[part 7 of 12: package /E40_Platform_System_SystemPackage/Components]
AUTOSAR XML (schema 4-2-1)
package /E40_Platform_System_SystemPackage/Components  (continued)
  10 x constant specification:
    View_IlluminationIlluminationDataDataValue0: value-spec={short-label=View_IlluminationIlluminationDataDataValue0, fields=[View_IlluminationIlluminationDataDataValue_0:0, View_IlluminationIlluminationDataDataValue_1:0, View_IlluminationIlluminationDataDataValue_2:0, View_IlluminationIlluminationDataDataValue_3:0]}
    View_IlluminationIllumStatusValue0: value-spec=View_IlluminationIllumStatusValue0:0
    View_IlluminationIgnitionSubstateValue0: value-spec=View_IlluminationIgnitionSubstateValue0:0
    View_IlluminationWSSCurrentVehicleStateValue0: value-spec=View_IlluminationWSSCurrentVehicleStateValue0:0
    View_IlluminationEcoRunSystem_FlagValue0: value-spec=View_IlluminationEcoRunSystem_FlagValue0:0
    View_IlluminationIllumCtrl_Op_DataValue0: value-spec={short-label=View_IlluminationIllumCtrl_Op_DataValue0, fields=[View_IlluminationIllumCtrl_Op_DataValue_0:0, View_IlluminationIllumCtrl_Op_DataValue_1:0, View_IlluminationIllumCtrl_Op_DataValue_2:0, View_IlluminationIllumCtrl_Op_DataValue_3:0, View_IlluminationIllumCtrl_Op_DataValue_4:0, View_IlluminationIllumCtrl_Op_DataValue_5:0, View_IlluminationIllumCtrl_Op_DataValue_6:0, View_IlluminationIllumCtrl_Op_DataValue_7:0]}
    View_IlluminationRheostatDayStepValue0: value-spec=View_IlluminationRheostatDayStepValue0:0
    View_IlluminationRheostatNightStepValue0: value-spec=View_IlluminationRheostatNightStepValue0:0
    View_IlluminationRheoUpdateValValue0: value-spec=View_IlluminationRheoUpdateValValue0:0
    View_IlluminationTFTDisplayOnValue0: value-spec=View_IlluminationTFTDisplayOnValue0:0
  swc implementation IMPL_View_Illumination: programming-language=C, behavior=IB_View_Illumination
    code-descriptors:
      code CodeDescriptor
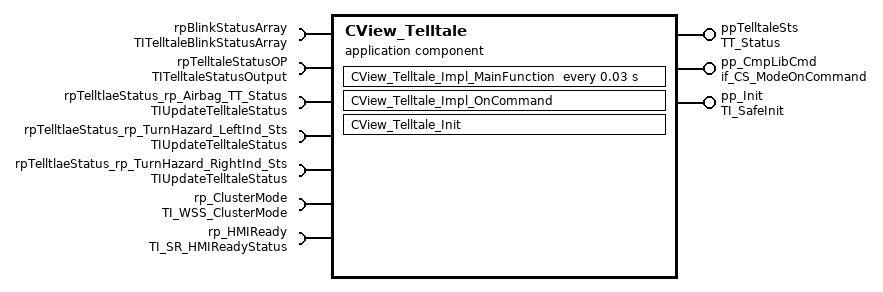
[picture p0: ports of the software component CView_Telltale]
  application sw component type CView_Telltale
    provide port ppTelltaleSts: nonqueued-sender-com-spec{data-element=TT_StatusData, init-value=constant-reference=CView_TelltaleTT_StatusDataValue0}, provided-interface=TT_Status
    provide port pp_CmpLibCmd: server-com-spec{operation=Impl_OnCommand, queue-length=1}, provided-interface=if_CS_ModeOnCommand
    provide port pp_Init: server-com-spec{operation=TI_SafeInit/Init, queue-length=1}, provided-interface=TI_SafeInit
    7 x require port:
      rpBlinkStatusArray: required-interface=TITelltaleBlinkStatusArray
        required-com-specs:
          data-element=TTBlinkStatusArray, init-value=constant-reference=CView_TelltaleTTBlinkStatusArrayValue0
          data-element=TTdummyDataForTypes, init-value=constant-reference=CView_TelltaleTTdummyDataForTypesValue0
      rpTelltaleStatusOP: nonqueued-receiver-com-spec{data-element=TelltaleOpArray, init-value=constant-reference=CView_TelltaleTelltaleOpArrayValue0}, required-interface=TITelltaleStatusOutput
      rpTelltlaeStatus_rp_Airbag_TT_Status: nonqueued-receiver-com-spec{data-element=CurrentTelltaleStatus, init-value=constant-reference=CView_TelltaleCurrentTelltaleStatusValue0}, required-interface=TIUpdateTelltaleStatus
      rpTelltlaeStatus_rp_TurnHazard_LeftInd_Sts: nonqueued-receiver-com-spec{data-element=CurrentTelltaleStatus, init-value=constant-reference=CView_TelltaleCurrentTelltaleStatusValue0}, required-interface=TIUpdateTelltaleStatus
      rpTelltlaeStatus_rp_TurnHazard_RightInd_Sts: nonqueued-receiver-com-spec{data-element=CurrentTelltaleStatus, init-value=constant-reference=CView_TelltaleCurrentTelltaleStatusValue0}, required-interface=TIUpdateTelltaleStatus
      rp_ClusterMode: nonqueued-receiver-com-spec{data-element=WSSCurrentClusterMode, init-value=constant-reference=CView_TelltaleWSSCurrentClusterModeValue0}, required-interface=TI_WSS_ClusterMode
      rp_HMIReady: nonqueued-receiver-com-spec{data-element=HMI_ReadyStatus, init-value=constant-reference=CView_TelltaleHMI_ReadyStatusValue0}, required-interface=TI_SR_HMIReadyStatus
    behavior IB_CView_Telltale
      timing event TECView_Telltale_Impl_MainFunction: start-on-event=CView_Telltale_Impl_MainFunction, period=0.03
      operation invoked event OIE_pp_CmpLibCmd_CView_Telltale_Impl_OnCommandTrigByImpl_OnCommand: start-on-event=CView_Telltale_Impl_OnCommand, operation=pp_CmpLibCmd.Impl_OnCommand
      operation invoked event OIE_pp_Init_CView_Telltale_InitTrigByInit: start-on-event=CView_Telltale_Init, operation=pp_Init.Init
      port-api-options:
        enable-take-address=false, indirect-api=false, port=ppTelltaleSts
        enable-take-address=false, indirect-api=false, port=CView_Telltale/pp_CmpLibCmd
        enable-take-address=false, indirect-api=false, port=CView_Telltale/pp_Init
        enable-take-address=false, indirect-api=false, port=rpBlinkStatusArray
        enable-take-address=false, indirect-api=false, port=CView_Telltale/rpTelltaleStatusOP
        enable-take-address=false, indirect-api=false, port=CView_Telltale/rpTelltlaeStatus_rp_Airbag_TT_Status
        enable-take-address=false, indirect-api=false, port=CView_Telltale/rpTelltlaeStatus_rp_TurnHazard_LeftInd_Sts
        enable-take-address=false, indirect-api=false, port=CView_Telltale/rpTelltlaeStatus_rp_TurnHazard_RightInd_Sts
        enable-take-address=false, indirect-api=false, port=CView_Telltale/rp_ClusterMode
        enable-take-address=false, indirect-api=false, port=rp_HMIReady
      runnable CView_Telltale_Impl_MainFunction: can-be-invoked-concurrently=true
        data-receive-point-by-arguments:
          8 x access:
            DRA_rpBlinkStatusArray_TTBlinkStatusArray: accessed-variable=rpBlinkStatusArray.TTBlinkStatusArray
            DRA_rpBlinkStatusArray_TTdummyDataForTypes: accessed-variable=rpBlinkStatusArray.TTdummyDataForTypes
            DRA_rpTelltaleStatusOP_TelltaleOpArray: accessed-variable=rpTelltaleStatusOP.TelltaleOpArray
            DRA_rpTelltlaeStatus_rp_Airbag_TT_Status_CurrentTelltaleStatus: accessed-variable=rpTelltlaeStatus_rp_Airbag_TT_Status.CurrentTelltaleStatus
            DRA_rpTelltlaeStatus_rp_TurnHazard_LeftInd_Sts_CurrentTelltaleStatus: accessed-variable=rpTelltlaeStatus_rp_TurnHazard_LeftInd_Sts.CurrentTelltaleStatus
            DRA_rpTelltlaeStatus_rp_TurnHazard_RightInd_Sts_CurrentTelltaleStatus: accessed-variable=rpTelltlaeStatus_rp_TurnHazard_RightInd_Sts.CurrentTelltaleStatus
            DRA_rp_ClusterMode_WSSCurrentClusterMode: accessed-variable=rp_ClusterMode.WSSCurrentClusterMode
            DRA_rp_HMIReady_HMI_ReadyStatus: accessed-variable=rp_HMIReady.HMI_ReadyStatus
        data-send-points:
          access DWA_ppTelltaleSts_TT_StatusData: accessed-variable=ppTelltaleSts.TT_StatusData
      runnable CView_Telltale_Impl_OnCommand: can-be-invoked-concurrently=true
      runnable CView_Telltale_Init: can-be-invoked-concurrently=true
  7 x constant specification:
    CView_TelltaleTT_StatusDataValue0: value-spec={short-label=CView_TelltaleTT_StatusDataValue0, fields=CView_TelltaleTT_StatusDataValue_0:[CView_Telltalemask0Value:0, CView_Telltalemask1Value:0, CView_Telltalemask2Value:0, CView_Telltalemask3Value:0, CView_Telltalemask4Value:0, CView_Telltalemask5Value:0, CView_Telltalemask6Value:0, CView_Telltalemask7Value:0, CView_Telltalemask8Value:0, CView_Telltalemask9Value:0, CView_Telltalemask10Value:0, CView_Telltalemask11Value:0, CView_Telltalemask12Value:0, CView_Telltalemask13Value:0, CView_Telltalemask14Value:0]}
    CView_TelltaleTTBlinkStatusArrayValue0: value-spec=CView_TelltaleTTBlinkStatusArrayValue0:[CView_TelltaleTTBlinkStatusArray0Value:0, CView_TelltaleTTBlinkStatusArray1Value:0, CView_TelltaleTTBlinkStatusArray2Value:0, CView_TelltaleTTBlinkStatusArray3Value:0, CView_TelltaleTTBlinkStatusArray4Value:0, CView_TelltaleTTBlinkStatusArray5Value:0, CView_TelltaleTTBlinkStatusArray6Value:0, CView_TelltaleTTBlinkStatusArray7Value:0, CView_TelltaleTTBlinkStatusArray8Value:0, CView_TelltaleTTBlinkStatusArray9Value:0, CView_TelltaleTTBlinkStatusArray10Value:0, CView_TelltaleTTBlinkStatusArray11Value:0, CView_TelltaleTTBlinkStatusArray12Value:0, CView_TelltaleTTBlinkStatusArray13Value:0, CView_TelltaleTTBlinkStatusArray14Value:0, CView_TelltaleTTBlinkStatusArray15Value:0]
    CView_TelltaleTTdummyDataForTypesValue0: value-spec=CView_TelltaleTTdummyDataForTypesValue0:0
    CView_TelltaleTelltaleOpArrayValue0: value-spec=CView_TelltaleTelltaleOpArrayValue0:[CView_TelltaleTelltaleOpArray0Value:0, CView_TelltaleTelltaleOpArray1Value:0, CView_TelltaleTelltaleOpArray2Value:0, CView_TelltaleTelltaleOpArray3Value:0, CView_TelltaleTelltaleOpArray4Value:0, CView_TelltaleTelltaleOpArray5Value:0, CView_TelltaleTelltaleOpArray6Value:0, CView_TelltaleTelltaleOpArray7Value:0, CView_TelltaleTelltaleOpArray8Value:0, CView_TelltaleTelltaleOpArray9Value:0, CView_TelltaleTelltaleOpArray10Value:0, CView_TelltaleTelltaleOpArray11Value:0, CView_TelltaleTelltaleOpArray12Value:0, CView_TelltaleTelltaleOpArray13Value:0, CView_TelltaleTelltaleOpArray14Value:0, CView_TelltaleTelltaleOpArray15Value:0, CView_TelltaleTelltaleOpArray16Value:0, CView_TelltaleTelltaleOpArray17Value:0, CView_TelltaleTelltaleOpArray18Value:0, CView_TelltaleTelltaleOpArray19Value:0, CView_TelltaleTelltaleOpArray20Value:0, CView_TelltaleTelltaleOpArray21Value:0, CView_TelltaleTelltaleOpArray22Value:0, CView_TelltaleTelltaleOpArray23Value:0, CView_TelltaleTelltaleOpArray24Value:0, CView_TelltaleTelltaleOpArray25Value:0, CView_TelltaleTelltaleOpArray26Value:0, CView_TelltaleTelltaleOpArray27Value:0, CView_TelltaleTelltaleOpArray28Value:0, CView_TelltaleTelltaleOpArray29Value:0, CView_TelltaleTelltaleOpArray30Value:0, CView_TelltaleTelltaleOpArray31Value:0, CView_TelltaleTelltaleOpArray32Value:0, CView_TelltaleTelltaleOpArray33Value:0, CView_TelltaleTelltaleOpArray34Value:0, CView_TelltaleTelltaleOpArray35Value:0, CView_TelltaleTelltaleOpArray36Value:0, CView_TelltaleTelltaleOpArray37Value:0, CView_TelltaleTelltaleOpArray38Value:0, CView_TelltaleTelltaleOpArray39Value:0, CView_TelltaleTelltaleOpArray40Value:0, CView_TelltaleTelltaleOpArray41Value:0, CView_TelltaleTelltaleOpArray42Value:0, CView_TelltaleTelltaleOpArray43Value:0, CView_TelltaleTelltaleOpArray44Value:0, CView_TelltaleTelltaleOpArray45Value:0, CView_TelltaleTelltaleOpArray46Value:0, CView_TelltaleTelltaleOpArray47Value:0, CView_TelltaleTelltaleOpArray48Value:0, CView_TelltaleTelltaleOpArray49Value:0, CView_TelltaleTelltaleOpArray50Value:0, CView_TelltaleTelltaleOpArray51Value:0, CView_TelltaleTelltaleOpArray52Value:0, CView_TelltaleTelltaleOpArray53Value:0, CView_TelltaleTelltaleOpArray54Value:0, CView_TelltaleTelltaleOpArray55Value:0, CView_TelltaleTelltaleOpArray56Value:0, CView_TelltaleTelltaleOpArray57Value:0, CView_TelltaleTelltaleOpArray58Value:0, CView_TelltaleTelltaleOpArray59Value:0, CView_TelltaleTelltaleOpArray60Value:0, CView_TelltaleTelltaleOpArray61Value:0, CView_TelltaleTelltaleOpArray62Value:0, CView_TelltaleTelltaleOpArray63Value:0, CView_TelltaleTelltaleOpArray64Value:0, CView_TelltaleTelltaleOpArray65Value:0, CView_TelltaleTelltaleOpArray66Value:0, CView_TelltaleTelltaleOpArray67Value:0, CView_TelltaleTelltaleOpArray68Value:0, CView_TelltaleTelltaleOpArray69Value:0, CView_TelltaleTelltaleOpArray70Value:0, CView_TelltaleTelltaleOpArray71Value:0, CView_TelltaleTelltaleOpArray72Value:0, CView_TelltaleTelltaleOpArray73Value:0, CView_TelltaleTelltaleOpArray74Value:0, CView_TelltaleTelltaleOpArray75Value:0, CView_TelltaleTelltaleOpArray76Value:0, CView_TelltaleTelltaleOpArray77Value:0, CView_TelltaleTelltaleOpArray78Value:0, CView_TelltaleTelltaleOpArray79Value:0, CView_TelltaleTelltaleOpArray80Value:0, CView_TelltaleTelltaleOpArray81Value:0, CView_TelltaleTelltaleOpArray82Value:0, CView_TelltaleTelltaleOpArray83Value:0, CView_TelltaleTelltaleOpArray84Value:0, CView_TelltaleTelltaleOpArray85Value:0, CView_TelltaleTelltaleOpArray86Value:0, CView_TelltaleTelltaleOpArray87Value:0, CView_TelltaleTelltaleOpArray88Value:0, CView_TelltaleTelltaleOpArray89Value:0, CView_TelltaleTelltaleOpArray90Value:0, CView_TelltaleTelltaleOpArray91Value:0]
    CView_TelltaleCurrentTelltaleStatusValue0: value-spec=CView_TelltaleCurrentTelltaleStatusValue0:0
    CView_TelltaleWSSCurrentClusterModeValue0: value-spec=CView_TelltaleWSSCurrentClusterModeValue0:0
    CView_TelltaleHMI_ReadyStatusValue0: value-spec=CView_TelltaleHMI_ReadyStatusValue0:0
  swc implementation IMPL_CView_Telltale: programming-language=C, behavior=IB_CView_Telltale
    code-descriptors:
      code CodeDescriptor
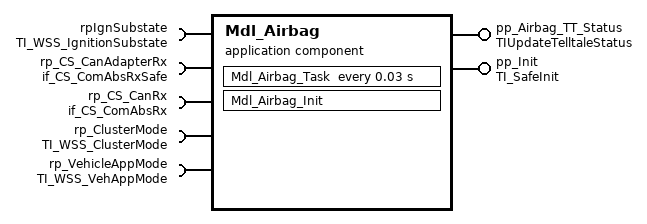
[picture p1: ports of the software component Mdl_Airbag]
  application sw component type Mdl_Airbag
    provide port pp_Airbag_TT_Status: nonqueued-sender-com-spec{data-element=CurrentTelltaleStatus, init-value=constant-reference=Mdl_AirbagCurrentTelltaleStatusValue0}, provided-interface=TIUpdateTelltaleStatus
    provide port pp_Init: server-com-spec{operation=TI_SafeInit/Init, queue-length=1}, provided-interface=TI_SafeInit
    5 x require port:
      rpIgnSubstate: nonqueued-receiver-com-spec{data-element=IgnitionSubstate, init-value=constant-reference=Mdl_AirbagIgnitionSubstateValue0}, required-interface=TI_WSS_IgnitionSubstate
      rp_CS_CanAdapterRx: required-interface=if_CS_ComAbsRxSafe
      rp_CS_CanRx: required-interface=if_CS_ComAbsRx
      rp_ClusterMode: nonqueued-receiver-com-spec{data-element=WSSCurrentClusterMode, init-value=constant-reference=Mdl_AirbagWSSCurrentClusterModeValue0}, required-interface=TI_WSS_ClusterMode
      rp_VehicleAppMode: nonqueued-receiver-com-spec{data-element=WSSCurrentVehicleState, init-value=constant-reference=Mdl_AirbagWSSCurrentVehicleStateValue0}, required-interface=TI_WSS_VehAppMode
    behavior IB_Mdl_Airbag
      operation invoked event OIE_pp_Init_Mdl_Airbag_InitTrigByInit: start-on-event=Mdl_Airbag_Init, operation=pp_Init.Init
      timing event TEMdl_Airbag_Task: start-on-event=Mdl_Airbag_Task, period=0.03
      port-api-options:
        enable-take-address=false, indirect-api=false, port=pp_Airbag_TT_Status
        enable-take-address=false, indirect-api=false, port=Mdl_Airbag/pp_Init
        enable-take-address=false, indirect-api=false, port=Mdl_Airbag/rpIgnSubstate
        enable-take-address=false, indirect-api=false, port=rp_CS_CanAdapterRx
        enable-take-address=false, indirect-api=false, port=Mdl_Airbag/rp_CS_CanRx
        enable-take-address=false, indirect-api=false, port=Mdl_Airbag/rp_ClusterMode
        enable-take-address=false, indirect-api=false, port=rp_VehicleAppMode
      runnable Mdl_Airbag_Init: can-be-invoked-concurrently=true
      runnable Mdl_Airbag_Task: can-be-invoked-concurrently=true
        data-receive-point-by-arguments:
          access DRA_rpIgnSubstate_IgnitionSubstate: accessed-variable=rpIgnSubstate.IgnitionSubstate
          access DRA_rp_ClusterMode_WSSCurrentClusterMode: accessed-variable=rp_ClusterMode.WSSCurrentClusterMode
          access DRA_rp_VehicleAppMode_WSSCurrentVehicleState: accessed-variable=rp_VehicleAppMode.WSSCurrentVehicleState
        data-send-points:
          access DWA_pp_Airbag_TT_Status_CurrentTelltaleStatus: accessed-variable=pp_Airbag_TT_Status.CurrentTelltaleStatus
        18 x sync call, all with timeout=0.0:
          OA_rp_CS_CanAdapterRx_RxCan_GetSignalValueU8Arr: operation=rp_CS_CanAdapterRx.RxCan_GetSignalValueU8Arr
          OA_rp_CS_CanAdapterRx_RxCan_SetSignalInitValue: operation=rp_CS_CanAdapterRx.RxCan_SetSignalInitValue
          OA_rp_CS_CanAdapterRx_RxCan_SetSignalInitValueU8Arr: operation=rp_CS_CanAdapterRx.RxCan_SetSignalInitValueU8Arr
          OA_rp_CS_CanAdapterRx_RxCan_SignalInvalidProcessingControl: operation=rp_CS_CanAdapterRx.RxCan_SignalInvalidProcessingControl
          OA_rp_CS_CanAdapterRx_RxCan_SignalMissingProcessingControl: operation=rp_CS_CanAdapterRx.RxCan_SignalMissingProcessingControl
          OA_rp_CS_CanAdapterRx_RxCan_SignalNRProcessingControl: operation=rp_CS_CanAdapterRx.RxCan_SignalNRProcessingControl
          OA_rp_CS_CanAdapterRx_RxCan_SignalGetJustRcvdStatus: operation=rp_CS_CanAdapterRx.RxCan_SignalGetJustRcvdStatus
          OA_rp_CS_CanAdapterRx_RxCan_SignalClearJustRcvdStatus: operation=rp_CS_CanAdapterRx.RxCan_SignalClearJustRcvdStatus
          OA_rp_CS_CanAdapterRx_RxCan_GetSignalValue: operation=rp_CS_CanAdapterRx.RxCan_GetSignalValue
          OA_rp_CS_CanRx_RxCan_GetSignalValueU8Arr: operation=rp_CS_CanRx.RxCan_GetSignalValueU8Arr
          OA_rp_CS_CanRx_RxCan_SetSignalInitValue: operation=rp_CS_CanRx.RxCan_SetSignalInitValue
          OA_rp_CS_CanRx_RxCan_SetSignalInitValueU8Arr: operation=rp_CS_CanRx.RxCan_SetSignalInitValueU8Arr
          OA_rp_CS_CanRx_RxCan_SignalInvalidProcessingControl: operation=rp_CS_CanRx.RxCan_SignalInvalidProcessingControl
          OA_rp_CS_CanRx_RxCan_SignalMissingProcessingControl: operation=rp_CS_CanRx.RxCan_SignalMissingProcessingControl
          OA_rp_CS_CanRx_RxCan_SignalNRProcessingControl: operation=rp_CS_CanRx.RxCan_SignalNRProcessingControl
          OA_rp_CS_CanRx_RxCan_SignalGetJustRcvdStatus: operation=rp_CS_CanRx.RxCan_SignalGetJustRcvdStatus
          OA_rp_CS_CanRx_RxCan_SignalClearJustRcvdStatus: operation=rp_CS_CanRx.RxCan_SignalClearJustRcvdStatus
          OA_rp_CS_CanRx_RxCan_GetSignalValue: operation=rp_CS_CanRx.RxCan_GetSignalValue
  4 x constant specification:
    Mdl_AirbagCurrentTelltaleStatusValue0: value-spec=Mdl_AirbagCurrentTelltaleStatusValue0:0
    Mdl_AirbagIgnitionSubstateValue0: value-spec=Mdl_AirbagIgnitionSubstateValue0:0
    Mdl_AirbagWSSCurrentClusterModeValue0: value-spec=Mdl_AirbagWSSCurrentClusterModeValue0:0
    Mdl_AirbagWSSCurrentVehicleStateValue0: value-spec=Mdl_AirbagWSSCurrentVehicleStateValue0:0
  swc implementation IMPL_Mdl_Airbag: programming-language=C, behavior=IB_Mdl_Airbag
    code-descriptors:
      code CodeDescriptor
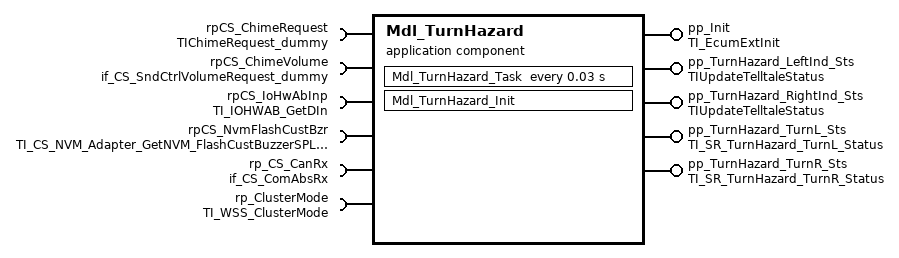
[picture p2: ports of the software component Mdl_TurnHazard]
  application sw component type Mdl_TurnHazard
    5 x provide port:
      pp_Init: server-com-spec{operation=TI_EcumExtInit/Init, queue-length=1}, provided-interface=TI_EcumExtInit
      pp_TurnHazard_LeftInd_Sts: nonqueued-sender-com-spec{data-element=CurrentTelltaleStatus, init-value=constant-reference=Mdl_TurnHazardCurrentTelltaleStatusValue0}, provided-interface=TIUpdateTelltaleStatus
      pp_TurnHazard_RightInd_Sts: nonqueued-sender-com-spec{data-element=CurrentTelltaleStatus, init-value=constant-reference=Mdl_TurnHazardCurrentTelltaleStatusValue0}, provided-interface=TIUpdateTelltaleStatus
      pp_TurnHazard_TurnL_Sts: nonqueued-sender-com-spec{data-element=LeftIndicatorSts, init-value=constant-reference=Mdl_TurnHazardLeftIndicatorStsValue0}, provided-interface=TI_SR_TurnHazard_TurnL_Status
      pp_TurnHazard_TurnR_Sts: nonqueued-sender-com-spec{data-element=RightIndicatorSts, init-value=constant-reference=Mdl_TurnHazardRightIndicatorStsValue0}, provided-interface=TI_SR_TurnHazard_TurnR_Status
    6 x require port:
      rpCS_ChimeRequest: nonqueued-receiver-com-spec{data-element=Chime_Request, init-value=constant-reference=Mdl_TurnHazardChime_RequestValue0}, required-interface=TIChimeRequest_dummy
      rpCS_ChimeVolume: nonqueued-receiver-com-spec{data-element=UpdateChimeVolume, init-value=constant-reference=Mdl_TurnHazardUpdateChimeVolumeValue0}, required-interface=if_CS_SndCtrlVolumeRequest_dummy
      rpCS_IoHwAbInp: required-interface=TI_IOHWAB_GetDIn
      rpCS_NvmFlashCustBzr: nonqueued-receiver-com-spec{data-element=Nvmdata, init-value=constant-reference=Mdl_TurnHazardNvmdataValue0}, required-interface=TI_CS_NVM_Adapter_GetNVM_FlashCustBuzzerSPL_Dummy
      rp_CS_CanRx: required-interface=if_CS_ComAbsRx
      rp_ClusterMode: nonqueued-receiver-com-spec{data-element=WSSCurrentClusterMode, init-value=constant-reference=Mdl_TurnHazardWSSCurrentClusterModeValue0}, required-interface=TI_WSS_ClusterMode
    behavior IB_Mdl_TurnHazard
      operation invoked event OIE_pp_Init_Mdl_TurnHazard_InitTrigByInit: start-on-event=Mdl_TurnHazard_Init, operation=pp_Init.Init
      timing event TEMdl_TurnHazard_Task: start-on-event=Mdl_TurnHazard_Task, period=0.03
      port-api-options:
        enable-take-address=false, indirect-api=false, port=Mdl_TurnHazard/pp_Init
        enable-take-address=false, indirect-api=false, port=pp_TurnHazard_LeftInd_Sts
        enable-take-address=false, indirect-api=false, port=pp_TurnHazard_RightInd_Sts
        enable-take-address=false, indirect-api=false, port=pp_TurnHazard_TurnL_Sts
        enable-take-address=false, indirect-api=false, port=pp_TurnHazard_TurnR_Sts
        enable-take-address=false, indirect-api=false, port=Mdl_TurnHazard/rpCS_ChimeRequest
        enable-take-address=false, indirect-api=false, port=rpCS_ChimeVolume
        enable-take-address=false, indirect-api=false, port=rpCS_IoHwAbInp
        enable-take-address=false, indirect-api=false, port=rpCS_NvmFlashCustBzr
        enable-take-address=false, indirect-api=false, port=Mdl_TurnHazard/rp_CS_CanRx
        enable-take-address=false, indirect-api=false, port=Mdl_TurnHazard/rp_ClusterMode
      runnable Mdl_TurnHazard_Init: can-be-invoked-concurrently=true
      runnable Mdl_TurnHazard_Task: can-be-invoked-concurrently=true
        data-receive-point-by-arguments:
          4 x access:
            DRA_rpCS_ChimeRequest_Chime_Request: accessed-variable=rpCS_ChimeRequest.Chime_Request
            DRA_rpCS_ChimeVolume_UpdateChimeVolume: accessed-variable=rpCS_ChimeVolume.UpdateChimeVolume
            DRA_rpCS_NvmFlashCustBzr_Nvmdata: accessed-variable=rpCS_NvmFlashCustBzr.Nvmdata
            DRA_rp_ClusterMode_WSSCurrentClusterMode: accessed-variable=rp_ClusterMode.WSSCurrentClusterMode
        data-send-points:
          4 x access:
            DWA_pp_TurnHazard_LeftInd_Sts_CurrentTelltaleStatus: accessed-variable=pp_TurnHazard_LeftInd_Sts.CurrentTelltaleStatus
            DWA_pp_TurnHazard_RightInd_Sts_CurrentTelltaleStatus: accessed-variable=pp_TurnHazard_RightInd_Sts.CurrentTelltaleStatus
            DWA_pp_TurnHazard_TurnL_Sts_LeftIndicatorSts: accessed-variable=pp_TurnHazard_TurnL_Sts.LeftIndicatorSts
            DWA_pp_TurnHazard_TurnR_Sts_RightIndicatorSts: accessed-variable=pp_TurnHazard_TurnR_Sts.RightIndicatorSts
        13 x sync call, all with timeout=0.0:
          OA_rpCS_IoHwAbInp_GetAsyncRawInput: operation=rpCS_IoHwAbInp.GetAsyncRawInput
          OA_rpCS_IoHwAbInp_GetProcessedInput: operation=rpCS_IoHwAbInp.GetProcessedInput
          OA_rpCS_IoHwAbInp_GetSyncRawInput: operation=rpCS_IoHwAbInp.GetSyncRawInput
          OA_rpCS_IoHwAbInp_GetInputGroup: operation=rpCS_IoHwAbInp.GetInputGroup
          OA_rp_CS_CanRx_RxCan_GetSignalValueU8Arr: operation=rp_CS_CanRx.RxCan_GetSignalValueU8Arr
          OA_rp_CS_CanRx_RxCan_SetSignalInitValue: operation=rp_CS_CanRx.RxCan_SetSignalInitValue
          OA_rp_CS_CanRx_RxCan_SetSignalInitValueU8Arr: operation=rp_CS_CanRx.RxCan_SetSignalInitValueU8Arr
          OA_rp_CS_CanRx_RxCan_SignalInvalidProcessingControl: operation=rp_CS_CanRx.RxCan_SignalInvalidProcessingControl
          OA_rp_CS_CanRx_RxCan_SignalMissingProcessingControl: operation=rp_CS_CanRx.RxCan_SignalMissingProcessingControl
          OA_rp_CS_CanRx_RxCan_SignalNRProcessingControl: operation=rp_CS_CanRx.RxCan_SignalNRProcessingControl
          OA_rp_CS_CanRx_RxCan_SignalGetJustRcvdStatus: operation=rp_CS_CanRx.RxCan_SignalGetJustRcvdStatus
          OA_rp_CS_CanRx_RxCan_SignalClearJustRcvdStatus: operation=rp_CS_CanRx.RxCan_SignalClearJustRcvdStatus
          OA_rp_CS_CanRx_RxCan_GetSignalValue: operation=rp_CS_CanRx.RxCan_GetSignalValue
  7 x constant specification:
    Mdl_TurnHazardCurrentTelltaleStatusValue0: value-spec=Mdl_TurnHazardCurrentTelltaleStatusValue0:0
    Mdl_TurnHazardLeftIndicatorStsValue0: value-spec=Mdl_TurnHazardLeftIndicatorStsValue0:0
    Mdl_TurnHazardRightIndicatorStsValue0: value-spec=Mdl_TurnHazardRightIndicatorStsValue0:0
    Mdl_TurnHazardChime_RequestValue0: value-spec=Mdl_TurnHazardChime_RequestValue0:0
    Mdl_TurnHazardUpdateChimeVolumeValue0: value-spec=Mdl_TurnHazardUpdateChimeVolumeValue0:0
    Mdl_TurnHazardNvmdataValue0: value-spec=Mdl_TurnHazardNvmdataValue0:0
    Mdl_TurnHazardWSSCurrentClusterModeValue0: value-spec=Mdl_TurnHazardWSSCurrentClusterModeValue0:0
  swc implementation IMPL_Mdl_TurnHazard: programming-language=C, behavior=IB_Mdl_TurnHazard
    code-descriptors:
      code CodeDescriptor
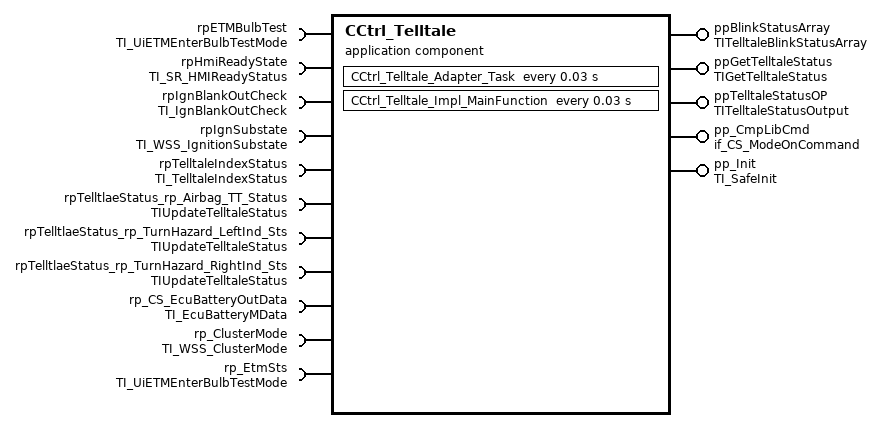
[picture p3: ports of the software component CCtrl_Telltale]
  application sw component type CCtrl_Telltale
    5 x provide port:
      ppBlinkStatusArray: provided-interface=TITelltaleBlinkStatusArray
        provided-com-specs:
          data-element=TTBlinkStatusArray, init-value=constant-reference=CCtrl_TelltaleTTBlinkStatusArrayValue0
          data-element=TTdummyDataForTypes, init-value=constant-reference=CCtrl_TelltaleTTdummyDataForTypesValue0
      ppGetTelltaleStatus: nonqueued-sender-com-spec{data-element=TelltaleFunctionalOpStatus, init-value=constant-reference=CCtrl_TelltaleTelltaleFunctionalOpStatusValue0}, provided-interface=TIGetTelltaleStatus
      ppTelltaleStatusOP: nonqueued-sender-com-spec{data-element=TelltaleOpArray, init-value=constant-reference=CCtrl_TelltaleTelltaleOpArrayValue0}, provided-interface=TITelltaleStatusOutput
      pp_CmpLibCmd: server-com-spec{operation=Impl_OnCommand, queue-length=1}, provided-interface=if_CS_ModeOnCommand
      pp_Init: server-com-spec{operation=TI_SafeInit/Init, queue-length=1}, provided-interface=TI_SafeInit
    11 x require port:
      rpETMBulbTest: nonqueued-receiver-com-spec{data-element=CurrentBulbTestStatus, init-value=constant-reference=CCtrl_TelltaleCurrentBulbTestStatusValue0}, required-interface=TI_UiETMEnterBulbTestMode
      rpHmiReadyState: nonqueued-receiver-com-spec{data-element=HMI_ReadyStatus, init-value=constant-reference=CCtrl_TelltaleHMI_ReadyStatusValue0}, required-interface=TI_SR_HMIReadyStatus
      rpIgnBlankOutCheck: nonqueued-receiver-com-spec{data-element=IgnBlankOutCheck, init-value=constant-reference=CCtrl_TelltaleIgnBlankOutCheckValue0}, required-interface=TI_IgnBlankOutCheck
      rpIgnSubstate: nonqueued-receiver-com-spec{data-element=IgnitionSubstate, init-value=constant-reference=CCtrl_TelltaleIgnitionSubstateValue0}, required-interface=TI_WSS_IgnitionSubstate
      rpTelltaleIndexStatus: required-interface=TI_TelltaleIndexStatus
        required-com-specs:
          data-element=TTIndex, init-value=constant-reference=CCtrl_TelltaleTTIndexValue0
          data-element=TTStatus, init-value=constant-reference=CCtrl_TelltaleTTStatusValue0
      rpTelltlaeStatus_rp_Airbag_TT_Status: nonqueued-receiver-com-spec{data-element=CurrentTelltaleStatus, init-value=constant-reference=CCtrl_TelltaleCurrentTelltaleStatusValue0}, required-interface=TIUpdateTelltaleStatus
      rpTelltlaeStatus_rp_TurnHazard_LeftInd_Sts: nonqueued-receiver-com-spec{data-element=CurrentTelltaleStatus, init-value=constant-reference=CCtrl_TelltaleCurrentTelltaleStatusValue0}, required-interface=TIUpdateTelltaleStatus
      rpTelltlaeStatus_rp_TurnHazard_RightInd_Sts: nonqueued-receiver-com-spec{data-element=CurrentTelltaleStatus, init-value=constant-reference=CCtrl_TelltaleCurrentTelltaleStatusValue0}, required-interface=TIUpdateTelltaleStatus
      rp_CS_EcuBatteryOutData: required-interface=TI_EcuBatteryMData
      rp_ClusterMode: nonqueued-receiver-com-spec{data-element=WSSCurrentClusterMode, init-value=constant-reference=CCtrl_TelltaleWSSCurrentClusterModeValue0}, required-interface=TI_WSS_ClusterMode
      rp_EtmSts: nonqueued-receiver-com-spec{data-element=CurrentBulbTestStatus, init-value=constant-reference=CCtrl_TelltaleCurrentBulbTestStatusValue0}, required-interface=TI_UiETMEnterBulbTestMode
    behavior IB_CCtrl_Telltale
      timing event TECCtrl_Telltale_Adapter_Task: start-on-event=CCtrl_Telltale_Adapter_Task, period=0.03
      timing event TECCtrl_Telltale_Impl_MainFunction: start-on-event=CCtrl_Telltale_Impl_MainFunction, period=0.03
      operation invoked event OIE_pp_CmpLibCmd_CCtrl_Telltale_Impl_OnCommandTrigByImpl_OnCommand: start-on-event=CCtrl_Telltale_Impl_OnCommand, operation=pp_CmpLibCmd.Impl_OnCommand
      operation invoked event OIE_pp_Init_CCtrl_Telltale_InitTrigByInit: start-on-event=CCtrl_Telltale_Init, operation=pp_Init.Init
      port-api-options:
        enable-take-address=false, indirect-api=false, port=ppBlinkStatusArray
        enable-take-address=false, indirect-api=false, port=ppGetTelltaleStatus
        enable-take-address=false, indirect-api=false, port=ppTelltaleStatusOP
        enable-take-address=false, indirect-api=false, port=CCtrl_Telltale/pp_CmpLibCmd
        enable-take-address=false, indirect-api=false, port=CCtrl_Telltale/pp_Init
        enable-take-address=false, indirect-api=false, port=rpETMBulbTest
        enable-take-address=false, indirect-api=false, port=rpHmiReadyState
        enable-take-address=false, indirect-api=false, port=rpIgnBlankOutCheck
        enable-take-address=false, indirect-api=false, port=CCtrl_Telltale/rpIgnSubstate
        enable-take-address=false, indirect-api=false, port=rpTelltaleIndexStatus
        enable-take-address=false, indirect-api=false, port=CCtrl_Telltale/rpTelltlaeStatus_rp_Airbag_TT_Status
        enable-take-address=false, indirect-api=false, port=CCtrl_Telltale/rpTelltlaeStatus_rp_TurnHazard_LeftInd_Sts
        enable-take-address=false, indirect-api=false, port=CCtrl_Telltale/rpTelltlaeStatus_rp_TurnHazard_RightInd_Sts
        enable-take-address=false, indirect-api=false, port=CCtrl_Telltale/rp_CS_EcuBatteryOutData
        enable-take-address=false, indirect-api=false, port=CCtrl_Telltale/rp_ClusterMode
        enable-take-address=false, indirect-api=false, port=rp_EtmSts
      4 x runnable, all with can-be-invoked-concurrently=true:
        CCtrl_Telltale_Adapter_Task
          data-receive-point-by-arguments:
            11 x access:
              DRA_rpETMBulbTest_CurrentBulbTestStatus: accessed-variable=rpETMBulbTest.CurrentBulbTestStatus
              DRA_rpHmiReadyState_HMI_ReadyStatus: accessed-variable=rpHmiReadyState.HMI_ReadyStatus
              DRA_rpIgnBlankOutCheck_IgnBlankOutCheck: accessed-variable=rpIgnBlankOutCheck.IgnBlankOutCheck
              DRA_rpIgnSubstate_IgnitionSubstate: accessed-variable=rpIgnSubstate.IgnitionSubstate
              DRA_rpTelltaleIndexStatus_TTIndex: accessed-variable=rpTelltaleIndexStatus.TTIndex
              DRA_rpTelltaleIndexStatus_TTStatus: accessed-variable=rpTelltaleIndexStatus.TTStatus
              DRA_rpTelltlaeStatus_rp_Airbag_TT_Status_CurrentTelltaleStatus: accessed-variable=rpTelltlaeStatus_rp_Airbag_TT_Status.CurrentTelltaleStatus
              DRA_rpTelltlaeStatus_rp_TurnHazard_LeftInd_Sts_CurrentTelltaleStatus: accessed-variable=rpTelltlaeStatus_rp_TurnHazard_LeftInd_Sts.CurrentTelltaleStatus
              DRA_rpTelltlaeStatus_rp_TurnHazard_RightInd_Sts_CurrentTelltaleStatus: accessed-variable=rpTelltlaeStatus_rp_TurnHazard_RightInd_Sts.CurrentTelltaleStatus
              DRA_rp_ClusterMode_WSSCurrentClusterMode: accessed-variable=rp_ClusterMode.WSSCurrentClusterMode
              DRA_rp_EtmSts_CurrentBulbTestStatus: accessed-variable=rp_EtmSts.CurrentBulbTestStatus
          data-send-points:
            4 x access:
              DWA_ppBlinkStatusArray_TTBlinkStatusArray: accessed-variable=ppBlinkStatusArray.TTBlinkStatusArray
              DWA_ppBlinkStatusArray_TTdummyDataForTypes: accessed-variable=ppBlinkStatusArray.TTdummyDataForTypes
              DWA_ppGetTelltaleStatus_TelltaleFunctionalOpStatus: accessed-variable=ppGetTelltaleStatus.TelltaleFunctionalOpStatus
              DWA_ppTelltaleStatusOP_TelltaleOpArray: accessed-variable=ppTelltaleStatusOP.TelltaleOpArray
          sync call OA_rp_CS_EcuBatteryOutData_EcuBatteryM_GetChannelStatus: operation=rp_CS_EcuBatteryOutData.EcuBatteryM_GetChannelStatus, timeout=0.0
          sync call OA_rp_CS_EcuBatteryOutData_EcuBatteryM_GetDIOStatus: operation=rp_CS_EcuBatteryOutData.EcuBatteryM_GetDIOStatus, timeout=0.0
        CCtrl_Telltale_Impl_MainFunction
          data-receive-point-by-arguments:
            11 x access:
              DRA_rpETMBulbTest_CurrentBulbTestStatus: accessed-variable=rpETMBulbTest.CurrentBulbTestStatus
              DRA_rpHmiReadyState_HMI_ReadyStatus: accessed-variable=rpHmiReadyState.HMI_ReadyStatus
              DRA_rpIgnBlankOutCheck_IgnBlankOutCheck: accessed-variable=rpIgnBlankOutCheck.IgnBlankOutCheck
              DRA_rpIgnSubstate_IgnitionSubstate: accessed-variable=rpIgnSubstate.IgnitionSubstate
              DRA_rpTelltaleIndexStatus_TTIndex: accessed-variable=rpTelltaleIndexStatus.TTIndex
              DRA_rpTelltaleIndexStatus_TTStatus: accessed-variable=rpTelltaleIndexStatus.TTStatus
              DRA_rpTelltlaeStatus_rp_Airbag_TT_Status_CurrentTelltaleStatus: accessed-variable=rpTelltlaeStatus_rp_Airbag_TT_Status.CurrentTelltaleStatus
              DRA_rpTelltlaeStatus_rp_TurnHazard_LeftInd_Sts_CurrentTelltaleStatus: accessed-variable=rpTelltlaeStatus_rp_TurnHazard_LeftInd_Sts.CurrentTelltaleStatus
              DRA_rpTelltlaeStatus_rp_TurnHazard_RightInd_Sts_CurrentTelltaleStatus: accessed-variable=rpTelltlaeStatus_rp_TurnHazard_RightInd_Sts.CurrentTelltaleStatus
              DRA_rp_ClusterMode_WSSCurrentClusterMode: accessed-variable=rp_ClusterMode.WSSCurrentClusterMode
              DRA_rp_EtmSts_CurrentBulbTestStatus: accessed-variable=rp_EtmSts.CurrentBulbTestStatus
          data-send-points:
            4 x access:
              DWA_ppBlinkStatusArray_TTBlinkStatusArray: accessed-variable=ppBlinkStatusArray.TTBlinkStatusArray
              DWA_ppBlinkStatusArray_TTdummyDataForTypes: accessed-variable=ppBlinkStatusArray.TTdummyDataForTypes
              DWA_ppGetTelltaleStatus_TelltaleFunctionalOpStatus: accessed-variable=ppGetTelltaleStatus.TelltaleFunctionalOpStatus
              DWA_ppTelltaleStatusOP_TelltaleOpArray: accessed-variable=ppTelltaleStatusOP.TelltaleOpArray
          sync call OA_rp_CS_EcuBatteryOutData_EcuBatteryM_GetChannelStatus: operation=rp_CS_EcuBatteryOutData.EcuBatteryM_GetChannelStatus, timeout=0.0
          sync call OA_rp_CS_EcuBatteryOutData_EcuBatteryM_GetDIOStatus: operation=rp_CS_EcuBatteryOutData.EcuBatteryM_GetDIOStatus, timeout=0.0
        CCtrl_Telltale_Impl_OnCommand
        CCtrl_Telltale_Init
  12 x constant specification:
    CCtrl_TelltaleTTBlinkStatusArrayValue0: value-spec=CCtrl_TelltaleTTBlinkStatusArrayValue0:[CCtrl_TelltaleTTBlinkStatusArray0Value:0, CCtrl_TelltaleTTBlinkStatusArray1Value:0, CCtrl_TelltaleTTBlinkStatusArray2Value:0, CCtrl_TelltaleTTBlinkStatusArray3Value:0, CCtrl_TelltaleTTBlinkStatusArray4Value:0, CCtrl_TelltaleTTBlinkStatusArray5Value:0, CCtrl_TelltaleTTBlinkStatusArray6Value:0, CCtrl_TelltaleTTBlinkStatusArray7Value:0, CCtrl_TelltaleTTBlinkStatusArray8Value:0, CCtrl_TelltaleTTBlinkStatusArray9Value:0, CCtrl_TelltaleTTBlinkStatusArray10Value:0, CCtrl_TelltaleTTBlinkStatusArray11Value:0, CCtrl_TelltaleTTBlinkStatusArray12Value:0, CCtrl_TelltaleTTBlinkStatusArray13Value:0, CCtrl_TelltaleTTBlinkStatusArray14Value:0, CCtrl_TelltaleTTBlinkStatusArray15Value:0]
    CCtrl_TelltaleTTdummyDataForTypesValue0: value-spec=CCtrl_TelltaleTTdummyDataForTypesValue0:0
    CCtrl_TelltaleTelltaleFunctionalOpStatusValue0: value-spec=CCtrl_TelltaleTelltaleFunctionalOpStatusValue0:[CCtrl_TelltaleTelltaleFunctionalOpStatus0Value:0, CCtrl_TelltaleTelltaleFunctionalOpStatus1Value:0, CCtrl_TelltaleTelltaleFunctionalOpStatus2Value:0, CCtrl_TelltaleTelltaleFunctionalOpStatus3Value:0, CCtrl_TelltaleTelltaleFunctionalOpStatus4Value:0, CCtrl_TelltaleTelltaleFunctionalOpStatus5Value:0, CCtrl_TelltaleTelltaleFunctionalOpStatus6Value:0, CCtrl_TelltaleTelltaleFunctionalOpStatus7Value:0, CCtrl_TelltaleTelltaleFunctionalOpStatus8Value:0, CCtrl_TelltaleTelltaleFunctionalOpStatus9Value:0, CCtrl_TelltaleTelltaleFunctionalOpStatus10Value:0, CCtrl_TelltaleTelltaleFunctionalOpStatus11Value:0, CCtrl_TelltaleTelltaleFunctionalOpStatus12Value:0, CCtrl_TelltaleTelltaleFunctionalOpStatus13Value:0, CCtrl_TelltaleTelltaleFunctionalOpStatus14Value:0, CCtrl_TelltaleTelltaleFunctionalOpStatus15Value:0, CCtrl_TelltaleTelltaleFunctionalOpStatus16Value:0, CCtrl_TelltaleTelltaleFunctionalOpStatus17Value:0, CCtrl_TelltaleTelltaleFunctionalOpStatus18Value:0, CCtrl_TelltaleTelltaleFunctionalOpStatus19Value:0, CCtrl_TelltaleTelltaleFunctionalOpStatus20Value:0, CCtrl_TelltaleTelltaleFunctionalOpStatus21Value:0, CCtrl_TelltaleTelltaleFunctionalOpStatus22Value:0, CCtrl_TelltaleTelltaleFunctionalOpStatus23Value:0, CCtrl_TelltaleTelltaleFunctionalOpStatus24Value:0, CCtrl_TelltaleTelltaleFunctionalOpStatus25Value:0, CCtrl_TelltaleTelltaleFunctionalOpStatus26Value:0, CCtrl_TelltaleTelltaleFunctionalOpStatus27Value:0, CCtrl_TelltaleTelltaleFunctionalOpStatus28Value:0, CCtrl_TelltaleTelltaleFunctionalOpStatus29Value:0, CCtrl_TelltaleTelltaleFunctionalOpStatus30Value:0, CCtrl_TelltaleTelltaleFunctionalOpStatus31Value:0, CCtrl_TelltaleTelltaleFunctionalOpStatus32Value:0, CCtrl_TelltaleTelltaleFunctionalOpStatus33Value:0, CCtrl_TelltaleTelltaleFunctionalOpStatus34Value:0, CCtrl_TelltaleTelltaleFunctionalOpStatus35Value:0, CCtrl_TelltaleTelltaleFunctionalOpStatus36Value:0, CCtrl_TelltaleTelltaleFunctionalOpStatus37Value:0, CCtrl_TelltaleTelltaleFunctionalOpStatus38Value:0, CCtrl_TelltaleTelltaleFunctionalOpStatus39Value:0, CCtrl_TelltaleTelltaleFunctionalOpStatus40Value:0, CCtrl_TelltaleTelltaleFunctionalOpStatus41Value:0, CCtrl_TelltaleTelltaleFunctionalOpStatus42Value:0, CCtrl_TelltaleTelltaleFunctionalOpStatus43Value:0, CCtrl_TelltaleTelltaleFunctionalOpStatus44Value:0, CCtrl_TelltaleTelltaleFunctionalOpStatus45Value:0, CCtrl_TelltaleTelltaleFunctionalOpStatus46Value:0, CCtrl_TelltaleTelltaleFunctionalOpStatus47Value:0, CCtrl_TelltaleTelltaleFunctionalOpStatus48Value:0, CCtrl_TelltaleTelltaleFunctionalOpStatus49Value:0, CCtrl_TelltaleTelltaleFunctionalOpStatus50Value:0, CCtrl_TelltaleTelltaleFunctionalOpStatus51Value:0, CCtrl_TelltaleTelltaleFunctionalOpStatus52Value:0, CCtrl_TelltaleTelltaleFunctionalOpStatus53Value:0, CCtrl_TelltaleTelltaleFunctionalOpStatus54Value:0, CCtrl_TelltaleTelltaleFunctionalOpStatus55Value:0, CCtrl_TelltaleTelltaleFunctionalOpStatus56Value:0, CCtrl_TelltaleTelltaleFunctionalOpStatus57Value:0, CCtrl_TelltaleTelltaleFunctionalOpStatus58Value:0, CCtrl_TelltaleTelltaleFunctionalOpStatus59Value:0, CCtrl_TelltaleTelltaleFunctionalOpStatus60Value:0, CCtrl_TelltaleTelltaleFunctionalOpStatus61Value:0, CCtrl_TelltaleTelltaleFunctionalOpStatus62Value:0, CCtrl_TelltaleTelltaleFunctionalOpStatus63Value:0, CCtrl_TelltaleTelltaleFunctionalOpStatus64Value:0, CCtrl_TelltaleTelltaleFunctionalOpStatus65Value:0, CCtrl_TelltaleTelltaleFunctionalOpStatus66Value:0, CCtrl_TelltaleTelltaleFunctionalOpStatus67Value:0, CCtrl_TelltaleTelltaleFunctionalOpStatus68Value:0, CCtrl_TelltaleTelltaleFunctionalOpStatus69Value:0, CCtrl_TelltaleTelltaleFunctionalOpStatus70Value:0, CCtrl_TelltaleTelltaleFunctionalOpStatus71Value:0, CCtrl_TelltaleTelltaleFunctionalOpStatus72Value:0, CCtrl_TelltaleTelltaleFunctionalOpStatus73Value:0, CCtrl_TelltaleTelltaleFunctionalOpStatus74Value:0, CCtrl_TelltaleTelltaleFunctionalOpStatus75Value:0, CCtrl_TelltaleTelltaleFunctionalOpStatus76Value:0, CCtrl_TelltaleTelltaleFunctionalOpStatus77Value:0, CCtrl_TelltaleTelltaleFunctionalOpStatus78Value:0, CCtrl_TelltaleTelltaleFunctionalOpStatus79Value:0, CCtrl_TelltaleTelltaleFunctionalOpStatus80Value:0, CCtrl_TelltaleTelltaleFunctionalOpStatus81Value:0, CCtrl_TelltaleTelltaleFunctionalOpStatus82Value:0, CCtrl_TelltaleTelltaleFunctionalOpStatus83Value:0, CCtrl_TelltaleTelltaleFunctionalOpStatus84Value:0, CCtrl_TelltaleTelltaleFunctionalOpStatus85Value:0, CCtrl_TelltaleTelltaleFunctionalOpStatus86Value:0, CCtrl_TelltaleTelltaleFunctionalOpStatus87Value:0, CCtrl_TelltaleTelltaleFunctionalOpStatus88Value:0, CCtrl_TelltaleTelltaleFunctionalOpStatus89Value:0, CCtrl_TelltaleTelltaleFunctionalOpStatus90Value:0, CCtrl_TelltaleTelltaleFunctionalOpStatus91Value:0]
    CCtrl_TelltaleTelltaleOpArrayValue0: value-spec=CCtrl_TelltaleTelltaleOpArrayValue0:[CCtrl_TelltaleTelltaleOpArray0Value:0, CCtrl_TelltaleTelltaleOpArray1Value:0, CCtrl_TelltaleTelltaleOpArray2Value:0, CCtrl_TelltaleTelltaleOpArray3Value:0, CCtrl_TelltaleTelltaleOpArray4Value:0, CCtrl_TelltaleTelltaleOpArray5Value:0, CCtrl_TelltaleTelltaleOpArray6Value:0, CCtrl_TelltaleTelltaleOpArray7Value:0, CCtrl_TelltaleTelltaleOpArray8Value:0, CCtrl_TelltaleTelltaleOpArray9Value:0, CCtrl_TelltaleTelltaleOpArray10Value:0, CCtrl_TelltaleTelltaleOpArray11Value:0, CCtrl_TelltaleTelltaleOpArray12Value:0, CCtrl_TelltaleTelltaleOpArray13Value:0, CCtrl_TelltaleTelltaleOpArray14Value:0, CCtrl_TelltaleTelltaleOpArray15Value:0, CCtrl_TelltaleTelltaleOpArray16Value:0, CCtrl_TelltaleTelltaleOpArray17Value:0, CCtrl_TelltaleTelltaleOpArray18Value:0, CCtrl_TelltaleTelltaleOpArray19Value:0, CCtrl_TelltaleTelltaleOpArray20Value:0, CCtrl_TelltaleTelltaleOpArray21Value:0, CCtrl_TelltaleTelltaleOpArray22Value:0, CCtrl_TelltaleTelltaleOpArray23Value:0, CCtrl_TelltaleTelltaleOpArray24Value:0, CCtrl_TelltaleTelltaleOpArray25Value:0, CCtrl_TelltaleTelltaleOpArray26Value:0, CCtrl_TelltaleTelltaleOpArray27Value:0, CCtrl_TelltaleTelltaleOpArray28Value:0, CCtrl_TelltaleTelltaleOpArray29Value:0, CCtrl_TelltaleTelltaleOpArray30Value:0, CCtrl_TelltaleTelltaleOpArray31Value:0, CCtrl_TelltaleTelltaleOpArray32Value:0, CCtrl_TelltaleTelltaleOpArray33Value:0, CCtrl_TelltaleTelltaleOpArray34Value:0, CCtrl_TelltaleTelltaleOpArray35Value:0, CCtrl_TelltaleTelltaleOpArray36Value:0, CCtrl_TelltaleTelltaleOpArray37Value:0, CCtrl_TelltaleTelltaleOpArray38Value:0, CCtrl_TelltaleTelltaleOpArray39Value:0, CCtrl_TelltaleTelltaleOpArray40Value:0, CCtrl_TelltaleTelltaleOpArray41Value:0, CCtrl_TelltaleTelltaleOpArray42Value:0, CCtrl_TelltaleTelltaleOpArray43Value:0, CCtrl_TelltaleTelltaleOpArray44Value:0, CCtrl_TelltaleTelltaleOpArray45Value:0, CCtrl_TelltaleTelltaleOpArray46Value:0, CCtrl_TelltaleTelltaleOpArray47Value:0, CCtrl_TelltaleTelltaleOpArray48Value:0, CCtrl_TelltaleTelltaleOpArray49Value:0, CCtrl_TelltaleTelltaleOpArray50Value:0, CCtrl_TelltaleTelltaleOpArray51Value:0, CCtrl_TelltaleTelltaleOpArray52Value:0, CCtrl_TelltaleTelltaleOpArray53Value:0, CCtrl_TelltaleTelltaleOpArray54Value:0, CCtrl_TelltaleTelltaleOpArray55Value:0, CCtrl_TelltaleTelltaleOpArray56Value:0, CCtrl_TelltaleTelltaleOpArray57Value:0, CCtrl_TelltaleTelltaleOpArray58Value:0, CCtrl_TelltaleTelltaleOpArray59Value:0, CCtrl_TelltaleTelltaleOpArray60Value:0, CCtrl_TelltaleTelltaleOpArray61Value:0, CCtrl_TelltaleTelltaleOpArray62Value:0, CCtrl_TelltaleTelltaleOpArray63Value:0, CCtrl_TelltaleTelltaleOpArray64Value:0, CCtrl_TelltaleTelltaleOpArray65Value:0, CCtrl_TelltaleTelltaleOpArray66Value:0, CCtrl_TelltaleTelltaleOpArray67Value:0, CCtrl_TelltaleTelltaleOpArray68Value:0, CCtrl_TelltaleTelltaleOpArray69Value:0, CCtrl_TelltaleTelltaleOpArray70Value:0, CCtrl_TelltaleTelltaleOpArray71Value:0, CCtrl_TelltaleTelltaleOpArray72Value:0, CCtrl_TelltaleTelltaleOpArray73Value:0, CCtrl_TelltaleTelltaleOpArray74Value:0, CCtrl_TelltaleTelltaleOpArray75Value:0, CCtrl_TelltaleTelltaleOpArray76Value:0, CCtrl_TelltaleTelltaleOpArray77Value:0, CCtrl_TelltaleTelltaleOpArray78Value:0, CCtrl_TelltaleTelltaleOpArray79Value:0, CCtrl_TelltaleTelltaleOpArray80Value:0, CCtrl_TelltaleTelltaleOpArray81Value:0, CCtrl_TelltaleTelltaleOpArray82Value:0, CCtrl_TelltaleTelltaleOpArray83Value:0, CCtrl_TelltaleTelltaleOpArray84Value:0, CCtrl_TelltaleTelltaleOpArray85Value:0, CCtrl_TelltaleTelltaleOpArray86Value:0, CCtrl_TelltaleTelltaleOpArray87Value:0, CCtrl_TelltaleTelltaleOpArray88Value:0, CCtrl_TelltaleTelltaleOpArray89Value:0, CCtrl_TelltaleTelltaleOpArray90Value:0, CCtrl_TelltaleTelltaleOpArray91Value:0]
    CCtrl_TelltaleCurrentBulbTestStatusValue0: value-spec=CCtrl_TelltaleCurrentBulbTestStatusValue0:0
    CCtrl_TelltaleHMI_ReadyStatusValue0: value-spec=CCtrl_TelltaleHMI_ReadyStatusValue0:0
    CCtrl_TelltaleIgnBlankOutCheckValue0: value-spec=CCtrl_TelltaleIgnBlankOutCheckValue0:0
    CCtrl_TelltaleIgnitionSubstateValue0: value-spec=CCtrl_TelltaleIgnitionSubstateValue0:0
    CCtrl_TelltaleTTIndexValue0: value-spec=CCtrl_TelltaleTTIndexValue0:0
    CCtrl_TelltaleTTStatusValue0: value-spec=CCtrl_TelltaleTTStatusValue0:0
    CCtrl_TelltaleCurrentTelltaleStatusValue0: value-spec=CCtrl_TelltaleCurrentTelltaleStatusValue0:0
    CCtrl_TelltaleWSSCurrentClusterModeValue0: value-spec=CCtrl_TelltaleWSSCurrentClusterModeValue0:0
  swc implementation IMPL_CCtrl_Telltale: programming-language=C, behavior=IB_CCtrl_Telltale
    code-descriptors:
      code CodeDescriptor
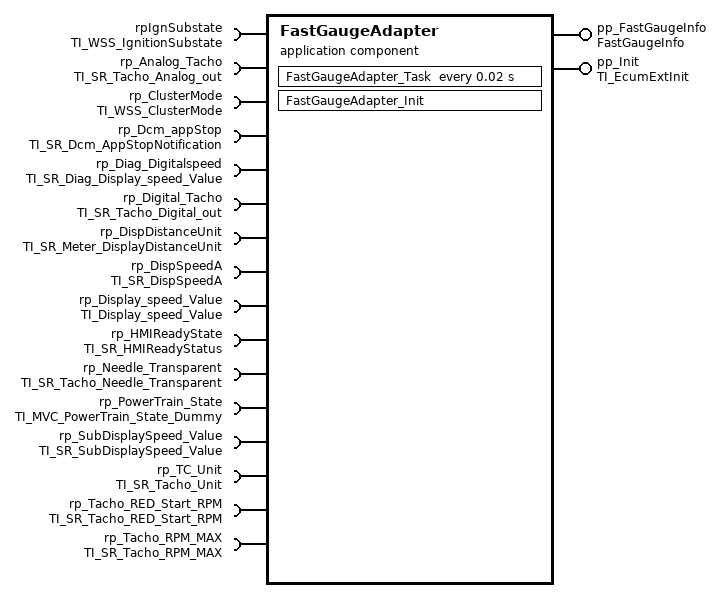
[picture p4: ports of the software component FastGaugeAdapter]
  application sw component type FastGaugeAdapter
    provide port pp_FastGaugeInfo: nonqueued-sender-com-spec{data-element=FastGaugeInfoData, init-value=constant-reference=FastGaugeAdapterFastGaugeInfoDataValue0}, provided-interface=FastGaugeInfo
    provide port pp_Init: server-com-spec{operation=TI_EcumExtInit/Init, queue-length=1}, provided-interface=TI_EcumExtInit
    16 x require port:
      rpIgnSubstate: nonqueued-receiver-com-spec{data-element=IgnitionSubstate, init-value=constant-reference=FastGaugeAdapterIgnitionSubstateValue0}, required-interface=TI_WSS_IgnitionSubstate
      rp_Analog_Tacho: nonqueued-receiver-com-spec{data-element=Analog_Tacho, init-value=constant-reference=FastGaugeAdapterAnalog_TachoValue0}, required-interface=TI_SR_Tacho_Analog_out
      rp_ClusterMode: nonqueued-receiver-com-spec{data-element=WSSCurrentClusterMode, init-value=constant-reference=FastGaugeAdapterWSSCurrentClusterModeValue0}, required-interface=TI_WSS_ClusterMode
      rp_Dcm_appStop: nonqueued-receiver-com-spec{data-element=AppId, init-value=constant-reference=FastGaugeAdapterAppIdValue0}, required-interface=TI_SR_Dcm_AppStopNotification
      rp_Diag_Digitalspeed: nonqueued-receiver-com-spec{data-element=Diag_Digital_Speed_Value, init-value=constant-reference=FastGaugeAdapterDiag_Digital_Speed_ValueValue0}, required-interface=TI_SR_Diag_Display_speed_Value
      rp_Digital_Tacho: nonqueued-receiver-com-spec{data-element=Digital_Tacho, init-value=constant-reference=FastGaugeAdapterDigital_TachoValue0}, required-interface=TI_SR_Tacho_Digital_out
      rp_DispDistanceUnit: nonqueued-receiver-com-spec{data-element=DisplayUnit, init-value=constant-reference=FastGaugeAdapterDisplayUnitValue0}, required-interface=TI_SR_Meter_DisplayDistanceUnit
      rp_DispSpeedA: nonqueued-receiver-com-spec{data-element=DispSpeedVal, init-value=constant-reference=FastGaugeAdapterDispSpeedValValue0}, required-interface=TI_SR_DispSpeedA
      rp_Display_speed_Value: nonqueued-receiver-com-spec{data-element=Digital_Speed_Value, init-value=constant-reference=FastGaugeAdapterDigital_Speed_ValueValue0}, required-interface=TI_Display_speed_Value
      rp_HMIReadyState: nonqueued-receiver-com-spec{data-element=HMI_ReadyStatus, init-value=constant-reference=FastGaugeAdapterHMI_ReadyStatusValue0}, required-interface=TI_SR_HMIReadyStatus
      rp_Needle_Transparent: nonqueued-receiver-com-spec{data-element=Needle_TR, init-value=constant-reference=FastGaugeAdapterNeedle_TRValue0}, required-interface=TI_SR_Tacho_Needle_Transparent
      rp_PowerTrain_State: nonqueued-receiver-com-spec{data-element=PowerTrain_Flag, init-value=constant-reference=FastGaugeAdapterPowerTrain_FlagValue0}, required-interface=TI_MVC_PowerTrain_State_Dummy
      rp_SubDisplaySpeed_Value: nonqueued-receiver-com-spec{data-element=SubDispSpeedVal, init-value=constant-reference=FastGaugeAdapterSubDispSpeedValValue0}, required-interface=TI_SR_SubDisplaySpeed_Value
      rp_TC_Unit: nonqueued-receiver-com-spec{data-element=Digital_TachoUnit, init-value=constant-reference=FastGaugeAdapterDigital_TachoUnitValue0}, required-interface=TI_SR_Tacho_Unit
      rp_Tacho_RED_Start_RPM: nonqueued-receiver-com-spec{data-element=RED_Start_RPM, init-value=constant-reference=FastGaugeAdapterRED_Start_RPMValue0}, required-interface=TI_SR_Tacho_RED_Start_RPM
      rp_Tacho_RPM_MAX: nonqueued-receiver-com-spec{data-element=REVP_RPM_MAX, init-value=constant-reference=FastGaugeAdapterREVP_RPM_MAXValue0}, required-interface=TI_SR_Tacho_RPM_MAX
    behavior IB_FastGaugeAdapter
      operation invoked event OIE_pp_Init_FastGaugeAdapter_InitTrigByInit: start-on-event=FastGaugeAdapter_Init, operation=pp_Init.Init
      timing event TEFastGaugeAdapter_Task: start-on-event=FastGaugeAdapter_Task, period=0.02
      port-api-options:
        enable-take-address=false, indirect-api=false, port=pp_FastGaugeInfo
        enable-take-address=false, indirect-api=false, port=FastGaugeAdapter/pp_Init
        enable-take-address=false, indirect-api=false, port=FastGaugeAdapter/rpIgnSubstate
        enable-take-address=false, indirect-api=false, port=rp_Analog_Tacho
        enable-take-address=false, indirect-api=false, port=FastGaugeAdapter/rp_ClusterMode
        enable-take-address=false, indirect-api=false, port=FastGaugeAdapter/rp_Dcm_appStop
        enable-take-address=false, indirect-api=false, port=FastGaugeAdapter/rp_Diag_Digitalspeed
        enable-take-address=false, indirect-api=false, port=rp_Digital_Tacho
        enable-take-address=false, indirect-api=false, port=FastGaugeAdapter/rp_DispDistanceUnit
        enable-take-address=false, indirect-api=false, port=rp_DispSpeedA
        enable-take-address=false, indirect-api=false, port=rp_Display_speed_Value
        enable-take-address=false, indirect-api=false, port=FastGaugeAdapter/rp_HMIReadyState
        enable-take-address=false, indirect-api=false, port=rp_Needle_Transparent
        enable-take-address=false, indirect-api=false, port=FastGaugeAdapter/rp_PowerTrain_State
        enable-take-address=false, indirect-api=false, port=rp_SubDisplaySpeed_Value
        enable-take-address=false, indirect-api=false, port=rp_TC_Unit
        enable-take-address=false, indirect-api=false, port=rp_Tacho_RED_Start_RPM
        enable-take-address=false, indirect-api=false, port=rp_Tacho_RPM_MAX
      runnable FastGaugeAdapter_Init: can-be-invoked-concurrently=true
      runnable FastGaugeAdapter_Task: can-be-invoked-concurrently=true
        data-receive-point-by-arguments:
          16 x access:
            DRA_rpIgnSubstate_IgnitionSubstate: accessed-variable=rpIgnSubstate.IgnitionSubstate
            DRA_rp_Analog_Tacho_Analog_Tacho: accessed-variable=rp_Analog_Tacho.Analog_Tacho
            DRA_rp_ClusterMode_WSSCurrentClusterMode: accessed-variable=rp_ClusterMode.WSSCurrentClusterMode
            DRA_rp_Dcm_appStop_AppId: accessed-variable=rp_Dcm_appStop.AppId
            DRA_rp_Diag_Digitalspeed_Diag_Digital_Speed_Value: accessed-variable=rp_Diag_Digitalspeed.Diag_Digital_Speed_Value
            DRA_rp_Digital_Tacho_Digital_Tacho: accessed-variable=rp_Digital_Tacho.Digital_Tacho
            DRA_rp_DispDistanceUnit_DisplayUnit: accessed-variable=rp_DispDistanceUnit.DisplayUnit
            DRA_rp_DispSpeedA_DispSpeedVal: accessed-variable=rp_DispSpeedA.DispSpeedVal
            DRA_rp_Display_speed_Value_Digital_Speed_Value: accessed-variable=rp_Display_speed_Value.Digital_Speed_Value
            DRA_rp_HMIReadyState_HMI_ReadyStatus: accessed-variable=rp_HMIReadyState.HMI_ReadyStatus
            DRA_rp_Needle_Transparent_Needle_TR: accessed-variable=rp_Needle_Transparent.Needle_TR
            DRA_rp_PowerTrain_State_PowerTrain_Flag: accessed-variable=rp_PowerTrain_State.PowerTrain_Flag
            DRA_rp_SubDisplaySpeed_Value_SubDispSpeedVal: accessed-variable=rp_SubDisplaySpeed_Value.SubDispSpeedVal
            DRA_rp_TC_Unit_Digital_TachoUnit: accessed-variable=rp_TC_Unit.Digital_TachoUnit
            DRA_rp_Tacho_RED_Start_RPM_RED_Start_RPM: accessed-variable=rp_Tacho_RED_Start_RPM.RED_Start_RPM
            DRA_rp_Tacho_RPM_MAX_REVP_RPM_MAX: accessed-variable=rp_Tacho_RPM_MAX.REVP_RPM_MAX
        data-send-points:
          access DWA_pp_FastGaugeInfo_FastGaugeInfoData: accessed-variable=pp_FastGaugeInfo.FastGaugeInfoData
  17 x constant specification:
    FastGaugeAdapterFastGaugeInfoDataValue0: value-spec={short-label=FastGaugeAdapterFastGaugeInfoDataValue0, fields={short-label=FastGaugeAdapterFastGaugeInfoDataValue_0, fields=[FastGaugeAdaptergaugeInfoValue_0:0, FastGaugeAdaptergaugeInfoValue_1:0, FastGaugeAdaptergaugeInfoValue_2:0, FastGaugeAdaptergaugeInfoValue_3:0, FastGaugeAdaptergaugeInfoValue_4:0]}}
    FastGaugeAdapterIgnitionSubstateValue0: value-spec=FastGaugeAdapterIgnitionSubstateValue0:0
    FastGaugeAdapterAnalog_TachoValue0: value-spec=FastGaugeAdapterAnalog_TachoValue0:0
    FastGaugeAdapterWSSCurrentClusterModeValue0: value-spec=FastGaugeAdapterWSSCurrentClusterModeValue0:0
    FastGaugeAdapterAppIdValue0: value-spec=FastGaugeAdapterAppIdValue0:0
    FastGaugeAdapterDiag_Digital_Speed_ValueValue0: value-spec=FastGaugeAdapterDiag_Digital_Speed_ValueValue0:0
    FastGaugeAdapterDigital_TachoValue0: value-spec=FastGaugeAdapterDigital_TachoValue0:0
    FastGaugeAdapterDisplayUnitValue0: value-spec=FastGaugeAdapterDisplayUnitValue0:0
    FastGaugeAdapterDispSpeedValValue0: value-spec=FastGaugeAdapterDispSpeedValValue0:0
    FastGaugeAdapterDigital_Speed_ValueValue0: value-spec=FastGaugeAdapterDigital_Speed_ValueValue0:0
    FastGaugeAdapterHMI_ReadyStatusValue0: value-spec=FastGaugeAdapterHMI_ReadyStatusValue0:0
    FastGaugeAdapterNeedle_TRValue0: value-spec=FastGaugeAdapterNeedle_TRValue0:0
    FastGaugeAdapterPowerTrain_FlagValue0: value-spec=FastGaugeAdapterPowerTrain_FlagValue0:0
    FastGaugeAdapterSubDispSpeedValValue0: value-spec=FastGaugeAdapterSubDispSpeedValValue0:0
    FastGaugeAdapterDigital_TachoUnitValue0: value-spec=FastGaugeAdapterDigital_TachoUnitValue0:false
    FastGaugeAdapterRED_Start_RPMValue0: value-spec=FastGaugeAdapterRED_Start_RPMValue0:0
    FastGaugeAdapterREVP_RPM_MAXValue0: value-spec=FastGaugeAdapterREVP_RPM_MAXValue0:0
  swc implementation IMPL_FastGaugeAdapter: programming-language=C, behavior=IB_FastGaugeAdapter
    code-descriptors:
      code CodeDescriptor
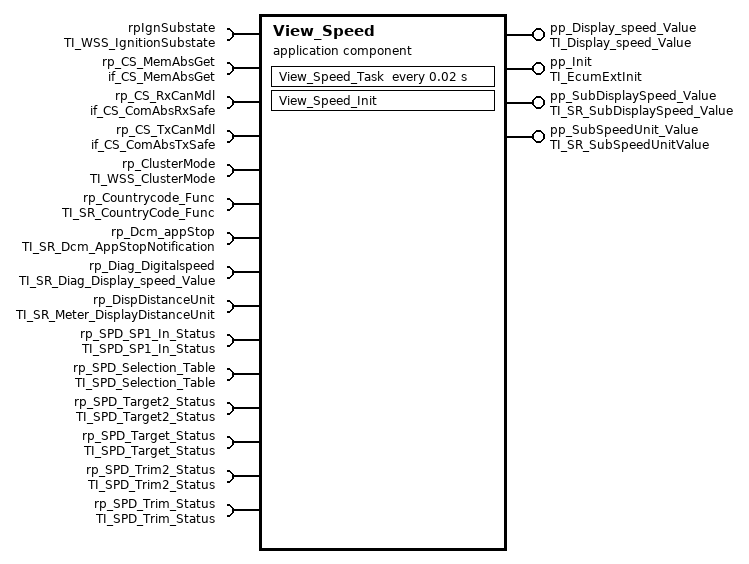
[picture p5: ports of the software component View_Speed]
  application sw component type View_Speed
    4 x provide port:
      pp_Display_speed_Value: nonqueued-sender-com-spec{data-element=Digital_Speed_Value, init-value=constant-reference=View_SpeedDigital_Speed_ValueValue0}, provided-interface=TI_Display_speed_Value
      pp_Init: server-com-spec{operation=TI_EcumExtInit/Init, queue-length=1}, provided-interface=TI_EcumExtInit
      pp_SubDisplaySpeed_Value: nonqueued-sender-com-spec{data-element=SubDispSpeedVal, init-value=constant-reference=View_SpeedSubDispSpeedValValue0}, provided-interface=TI_SR_SubDisplaySpeed_Value
      pp_SubSpeedUnit_Value: nonqueued-sender-com-spec{data-element=SubSpeedunit, init-value=constant-reference=View_SpeedSubSpeedunitValue0}, provided-interface=TI_SR_SubSpeedUnitValue
    15 x require port:
      rpIgnSubstate: nonqueued-receiver-com-spec{data-element=IgnitionSubstate, init-value=constant-reference=View_SpeedIgnitionSubstateValue0}, required-interface=TI_WSS_IgnitionSubstate
      rp_CS_MemAbsGet: required-interface=if_CS_MemAbsGet
      rp_CS_RxCanMdl: required-interface=if_CS_ComAbsRxSafe
      rp_CS_TxCanMdl: required-interface=if_CS_ComAbsTxSafe
      rp_ClusterMode: nonqueued-receiver-com-spec{data-element=WSSCurrentClusterMode, init-value=constant-reference=View_SpeedWSSCurrentClusterModeValue0}, required-interface=TI_WSS_ClusterMode
      rp_Countrycode_Func: nonqueued-receiver-com-spec{data-element=CountryCode_Func, init-value=constant-reference=View_SpeedCountryCode_FuncValue0}, required-interface=TI_SR_CountryCode_Func
      rp_Dcm_appStop: nonqueued-receiver-com-spec{data-element=AppId, init-value=constant-reference=View_SpeedAppIdValue0}, required-interface=TI_SR_Dcm_AppStopNotification
      rp_Diag_Digitalspeed: nonqueued-receiver-com-spec{data-element=Diag_Digital_Speed_Value, init-value=constant-reference=View_SpeedDiag_Digital_Speed_ValueValue0}, required-interface=TI_SR_Diag_Display_speed_Value
      rp_DispDistanceUnit: nonqueued-receiver-com-spec{data-element=DisplayUnit, init-value=constant-reference=View_SpeedDisplayUnitValue0}, required-interface=TI_SR_Meter_DisplayDistanceUnit
      rp_SPD_SP1_In_Status: nonqueued-receiver-com-spec{data-element=SP1_In_Status, init-value=constant-reference=View_SpeedSP1_In_StatusValue0}, required-interface=TI_SPD_SP1_In_Status
      rp_SPD_Selection_Table: nonqueued-receiver-com-spec{data-element=Speed_Selection_Table, init-value=constant-reference=View_SpeedSpeed_Selection_TableValue0}, required-interface=TI_SPD_Selection_Table
      rp_SPD_Target2_Status: nonqueued-receiver-com-spec{data-element=Spd_Target2_Status, init-value=constant-reference=View_SpeedSpd_Target2_StatusValue0}, required-interface=TI_SPD_Target2_Status
      rp_SPD_Target_Status: nonqueued-receiver-com-spec{data-element=Spd_Target_Status, init-value=constant-reference=View_SpeedSpd_Target_StatusValue0}, required-interface=TI_SPD_Target_Status
      rp_SPD_Trim2_Status: nonqueued-receiver-com-spec{data-element=Spd_Trim2_Status, init-value=constant-reference=View_SpeedSpd_Trim2_StatusValue0}, required-interface=TI_SPD_Trim2_Status
      rp_SPD_Trim_Status: nonqueued-receiver-com-spec{data-element=Spd_Trim_Status, init-value=constant-reference=View_SpeedSpd_Trim_StatusValue0}, required-interface=TI_SPD_Trim_Status
    behavior IB_View_Speed
      operation invoked event OIE_pp_Init_View_Speed_InitTrigByInit: start-on-event=View_Speed_Init, operation=pp_Init.Init
      timing event TEView_Speed_Task: start-on-event=View_Speed_Task, period=0.02
      port-api-options:
        enable-take-address=false, indirect-api=false, port=pp_Display_speed_Value
        enable-take-address=false, indirect-api=false, port=View_Speed/pp_Init
        enable-take-address=false, indirect-api=false, port=pp_SubDisplaySpeed_Value
        enable-take-address=false, indirect-api=false, port=pp_SubSpeedUnit_Value
        enable-take-address=false, indirect-api=false, port=View_Speed/rpIgnSubstate
        enable-take-address=false, indirect-api=false, port=View_Speed/rp_CS_MemAbsGet
        enable-take-address=false, indirect-api=false, port=View_Speed/rp_CS_RxCanMdl
        enable-take-address=false, indirect-api=false, port=View_Speed/rp_CS_TxCanMdl
        enable-take-address=false, indirect-api=false, port=View_Speed/rp_ClusterMode
        enable-take-address=false, indirect-api=false, port=View_Speed/rp_Countrycode_Func
        enable-take-address=false, indirect-api=false, port=View_Speed/rp_Dcm_appStop
        enable-take-address=false, indirect-api=false, port=View_Speed/rp_Diag_Digitalspeed
        enable-take-address=false, indirect-api=false, port=View_Speed/rp_DispDistanceUnit
        enable-take-address=false, indirect-api=false, port=View_Speed/rp_SPD_SP1_In_Status
        enable-take-address=false, indirect-api=false, port=rp_SPD_Selection_Table
        enable-take-address=false, indirect-api=false, port=rp_SPD_Target2_Status
        enable-take-address=false, indirect-api=false, port=rp_SPD_Target_Status
        enable-take-address=false, indirect-api=false, port=rp_SPD_Trim2_Status
        enable-take-address=false, indirect-api=false, port=rp_SPD_Trim_Status
      runnable View_Speed_Init: can-be-invoked-concurrently=true
      runnable View_Speed_Task: can-be-invoked-concurrently=true
        data-receive-point-by-arguments:
          12 x access:
            DRA_rpIgnSubstate_IgnitionSubstate: accessed-variable=rpIgnSubstate.IgnitionSubstate
            DRA_rp_ClusterMode_WSSCurrentClusterMode: accessed-variable=rp_ClusterMode.WSSCurrentClusterMode
            DRA_rp_Countrycode_Func_CountryCode_Func: accessed-variable=rp_Countrycode_Func.CountryCode_Func
            DRA_rp_Dcm_appStop_AppId: accessed-variable=rp_Dcm_appStop.AppId
            DRA_rp_Diag_Digitalspeed_Diag_Digital_Speed_Value: accessed-variable=rp_Diag_Digitalspeed.Diag_Digital_Speed_Value
            DRA_rp_DispDistanceUnit_DisplayUnit: accessed-variable=rp_DispDistanceUnit.DisplayUnit
            DRA_rp_SPD_SP1_In_Status_SP1_In_Status: accessed-variable=rp_SPD_SP1_In_Status.SP1_In_Status
            DRA_rp_SPD_Selection_Table_Speed_Selection_Table: accessed-variable=rp_SPD_Selection_Table.Speed_Selection_Table
            DRA_rp_SPD_Target2_Status_Spd_Target2_Status: accessed-variable=rp_SPD_Target2_Status.Spd_Target2_Status
            DRA_rp_SPD_Target_Status_Spd_Target_Status: accessed-variable=rp_SPD_Target_Status.Spd_Target_Status
            DRA_rp_SPD_Trim2_Status_Spd_Trim2_Status: accessed-variable=rp_SPD_Trim2_Status.Spd_Trim2_Status
            DRA_rp_SPD_Trim_Status_Spd_Trim_Status: accessed-variable=rp_SPD_Trim_Status.Spd_Trim_Status
        data-send-points:
          access DWA_pp_Display_speed_Value_Digital_Speed_Value: accessed-variable=pp_Display_speed_Value.Digital_Speed_Value
          access DWA_pp_SubDisplaySpeed_Value_SubDispSpeedVal: accessed-variable=pp_SubDisplaySpeed_Value.SubDispSpeedVal
          access DWA_pp_SubSpeedUnit_Value_SubSpeedunit: accessed-variable=pp_SubSpeedUnit_Value.SubSpeedunit
        108 x sync call, all with timeout=0.0:
          OA_rp_CS_MemAbsGet_Get_BsShare_SwUpdReflash_Element: operation=rp_CS_MemAbsGet.Get_BsShare_SwUpdReflash_Element
          OA_rp_CS_MemAbsGet_Get_BsShare_SwUpdFotaMode_Element: operation=rp_CS_MemAbsGet.Get_BsShare_SwUpdFotaMode_Element
          OA_rp_CS_MemAbsGet_Get_BsShare_SwUpdFotaFinPrint_Element: operation=rp_CS_MemAbsGet.Get_BsShare_SwUpdFotaFinPrint_Element
          OA_rp_CS_MemAbsGet_Get_BsShare_SwUpdFotaStatus_Element: operation=rp_CS_MemAbsGet.Get_BsShare_SwUpdFotaStatus_Element
          OA_rp_CS_MemAbsGet_Get_BsShare_SwUpdFotadecrypt_Element: operation=rp_CS_MemAbsGet.Get_BsShare_SwUpdFotadecrypt_Element
          OA_rp_CS_MemAbsGet_Get_BsShare_EcuPartNumber_Element: operation=rp_CS_MemAbsGet.Get_BsShare_EcuPartNumber_Element
          OA_rp_CS_MemAbsGet_Get_BsShare_VisteonPartNumber: operation=rp_CS_MemAbsGet.Get_BsShare_VisteonPartNumber
          OA_rp_CS_MemAbsGet_Get_BsShare_VisteonPCBPartNumber: operation=rp_CS_MemAbsGet.Get_BsShare_VisteonPCBPartNumber
          OA_rp_CS_MemAbsGet_Get_BsShare_ProductSerialNumber: operation=rp_CS_MemAbsGet.Get_BsShare_ProductSerialNumber
          OA_rp_CS_MemAbsGet_Get_BsShare_PCBSerialNumber: operation=rp_CS_MemAbsGet.Get_BsShare_PCBSerialNumber
          OA_rp_CS_MemAbsGet_Get_BsShare_SMTManufacturingDate: operation=rp_CS_MemAbsGet.Get_BsShare_SMTManufacturingDate
          OA_rp_CS_MemAbsGet_Get_BsShare_AssemblyManufacturingDate: operation=rp_CS_MemAbsGet.Get_BsShare_AssemblyManufacturingDate
          OA_rp_CS_MemAbsGet_Get_BsShare_SMTPlantNumber: operation=rp_CS_MemAbsGet.Get_BsShare_SMTPlantNumber
          OA_rp_CS_MemAbsGet_Get_BsShare_AssemblyPlantNumber: operation=rp_CS_MemAbsGet.Get_BsShare_AssemblyPlantNumber
          OA_rp_CS_MemAbsGet_Get_BsShare_HWModification: operation=rp_CS_MemAbsGet.Get_BsShare_HWModification
          OA_rp_CS_MemAbsGet_Get_BsShare_VisMeet_Element: operation=rp_CS_MemAbsGet.Get_BsShare_VisMeet_Element
          OA_rp_CS_MemAbsGet_Get_BsShare_VisMeet_EOLEntry_Element: operation=rp_CS_MemAbsGet.Get_BsShare_VisMeet_EOLEntry_Element
          OA_rp_CS_MemAbsGet_Get_BsShare_VehicleConfig_Element: operation=rp_CS_MemAbsGet.Get_BsShare_VehicleConfig_Element
          OA_rp_CS_MemAbsGet_Get_BsConst_SpeedoGauge_Element: operation=rp_CS_MemAbsGet.Get_BsConst_SpeedoGauge_Element
          OA_rp_CS_MemAbsGet_Get_BsConst_TachoGauge_Element: operation=rp_CS_MemAbsGet.Get_BsConst_TachoGauge_Element
          OA_rp_CS_MemAbsGet_Get_BsConst_FuelGauge_Element: operation=rp_CS_MemAbsGet.Get_BsConst_FuelGauge_Element
          OA_rp_CS_MemAbsGet_Get_BsConst_TempGauge_Element: operation=rp_CS_MemAbsGet.Get_BsConst_TempGauge_Element
          OA_rp_CS_MemAbsGet_Get_BsConst_PowerGauge_Element: operation=rp_CS_MemAbsGet.Get_BsConst_PowerGauge_Element
          OA_rp_CS_MemAbsGet_Get_BsConst_OilGauge_Element: operation=rp_CS_MemAbsGet.Get_BsConst_OilGauge_Element
          OA_rp_CS_MemAbsGet_Get_BsConst_TripComputer_Element: operation=rp_CS_MemAbsGet.Get_BsConst_TripComputer_Element
          OA_rp_CS_MemAbsGet_Get_BsConst_Compensation_Line_Slope_m: operation=rp_CS_MemAbsGet.Get_BsConst_Compensation_Line_Slope_m
          OA_rp_CS_MemAbsGet_Get_BsConst_Compensation_Line_Shift_b: operation=rp_CS_MemAbsGet.Get_BsConst_Compensation_Line_Shift_b
          OA_rp_CS_MemAbsGet_Get_BsConst_Lookup_Curve_HotSpot_Coef_X: operation=rp_CS_MemAbsGet.Get_BsConst_Lookup_Curve_HotSpot_Coef_X
          OA_rp_CS_MemAbsGet_Get_BsConst_Lookup_Curve_HotSpot_Coef_Y: operation=rp_CS_MemAbsGet.Get_BsConst_Lookup_Curve_HotSpot_Coef_Y
          OA_rp_CS_MemAbsGet_Get_BsConst_Temp_Threshold_Hysteresis_Derating: operation=rp_CS_MemAbsGet.Get_BsConst_Temp_Threshold_Hysteresis_Derating
          OA_rp_CS_MemAbsGet_Get_BsConst_Derating_Backlight_Disable: operation=rp_CS_MemAbsGet.Get_BsConst_Derating_Backlight_Disable
          OA_rp_CS_MemAbsGet_Get_BsConst_Temperature_Sensor_Conv: operation=rp_CS_MemAbsGet.Get_BsConst_Temperature_Sensor_Conv
          OA_rp_CS_MemAbsGet_Get_BsConst_PCB_Temperature_Sensor_Conv: operation=rp_CS_MemAbsGet.Get_BsConst_PCB_Temperature_Sensor_Conv
          OA_rp_CS_MemAbsGet_Get_BsConst_Display_Illum_Max_Level: operation=rp_CS_MemAbsGet.Get_BsConst_Display_Illum_Max_Level
          OA_rp_CS_MemAbsGet_Get_BsConst_PWM_boost_bypass_duty: operation=rp_CS_MemAbsGet.Get_BsConst_PWM_boost_bypass_duty
          OA_rp_CS_MemAbsGet_Get_BsConst_BsConst_Illumination_ReservedByte: operation=rp_CS_MemAbsGet.Get_BsConst_BsConst_Illumination_ReservedByte
          OA_rp_CS_MemAbsGet_Get_BsConst_Compensation_Line_Slope_m_SafeCopy1: operation=rp_CS_MemAbsGet.Get_BsConst_Compensation_Line_Slope_m_SafeCopy1
          OA_rp_CS_MemAbsGet_Get_BsConst_Compensation_Line_Shift_b_SafeCopy1: operation=rp_CS_MemAbsGet.Get_BsConst_Compensation_Line_Shift_b_SafeCopy1
          OA_rp_CS_MemAbsGet_Get_BsConst_Lookup_Curve_HotSpot_Coef_X_SafeCopy1: operation=rp_CS_MemAbsGet.Get_BsConst_Lookup_Curve_HotSpot_Coef_X_SafeCopy1
          OA_rp_CS_MemAbsGet_Get_BsConst_Lookup_Curve_HotSpot_Coef_Y_SafeCopy1: operation=rp_CS_MemAbsGet.Get_BsConst_Lookup_Curve_HotSpot_Coef_Y_SafeCopy1
          OA_rp_CS_MemAbsGet_Get_BsConst_Temp_Threshold_Hysteresis_Derating_SafeCopy1: operation=rp_CS_MemAbsGet.Get_BsConst_Temp_Threshold_Hysteresis_Derating_SafeCopy1
          OA_rp_CS_MemAbsGet_Get_BsConst_Derating_Backlight_Disable_SafeCopy1: operation=rp_CS_MemAbsGet.Get_BsConst_Derating_Backlight_Disable_SafeCopy1
          OA_rp_CS_MemAbsGet_Get_BsConst_Temperature_Sensor_Conv_SafeCopy1: operation=rp_CS_MemAbsGet.Get_BsConst_Temperature_Sensor_Conv_SafeCopy1
          OA_rp_CS_MemAbsGet_Get_BsConst_PCB_Temperature_Sensor_Conv_SafeCopy1: operation=rp_CS_MemAbsGet.Get_BsConst_PCB_Temperature_Sensor_Conv_SafeCopy1
          OA_rp_CS_MemAbsGet_Get_BsConst_Display_Illum_Max_Level_SafeCopy1: operation=rp_CS_MemAbsGet.Get_BsConst_Display_Illum_Max_Level_SafeCopy1
          OA_rp_CS_MemAbsGet_Get_BsConst_PWM_boost_bypass_duty_SafeCopy1: operation=rp_CS_MemAbsGet.Get_BsConst_PWM_boost_bypass_duty_SafeCopy1
          OA_rp_CS_MemAbsGet_Get_BsConst_BsConst_Illumination_ReservedByte_SafeCopy1: operation=rp_CS_MemAbsGet.Get_BsConst_BsConst_Illumination_ReservedByte_SafeCopy1
          OA_rp_CS_MemAbsGet_Get_BsConst_Compensation_Line_Slope_m_SafeCopy2: operation=rp_CS_MemAbsGet.Get_BsConst_Compensation_Line_Slope_m_SafeCopy2
          OA_rp_CS_MemAbsGet_Get_BsConst_Compensation_Line_Shift_b_SafeCopy2: operation=rp_CS_MemAbsGet.Get_BsConst_Compensation_Line_Shift_b_SafeCopy2
          OA_rp_CS_MemAbsGet_Get_BsConst_Lookup_Curve_HotSpot_Coef_X_SafeCopy2: operation=rp_CS_MemAbsGet.Get_BsConst_Lookup_Curve_HotSpot_Coef_X_SafeCopy2
          OA_rp_CS_MemAbsGet_Get_BsConst_Lookup_Curve_HotSpot_Coef_Y_SafeCopy2: operation=rp_CS_MemAbsGet.Get_BsConst_Lookup_Curve_HotSpot_Coef_Y_SafeCopy2
          OA_rp_CS_MemAbsGet_Get_BsConst_Temp_Threshold_Hysteresis_Derating_SafeCopy2: operation=rp_CS_MemAbsGet.Get_BsConst_Temp_Threshold_Hysteresis_Derating_SafeCopy2
          OA_rp_CS_MemAbsGet_Get_BsConst_Derating_Backlight_Disable_SafeCopy2: operation=rp_CS_MemAbsGet.Get_BsConst_Derating_Backlight_Disable_SafeCopy2
          OA_rp_CS_MemAbsGet_Get_BsConst_Temperature_Sensor_Conv_SafeCopy2: operation=rp_CS_MemAbsGet.Get_BsConst_Temperature_Sensor_Conv_SafeCopy2
          OA_rp_CS_MemAbsGet_Get_BsConst_PCB_Temperature_Sensor_Conv_SafeCopy2: operation=rp_CS_MemAbsGet.Get_BsConst_PCB_Temperature_Sensor_Conv_SafeCopy2
          OA_rp_CS_MemAbsGet_Get_BsConst_Display_Illum_Max_Level_SafeCopy2: operation=rp_CS_MemAbsGet.Get_BsConst_Display_Illum_Max_Level_SafeCopy2
          OA_rp_CS_MemAbsGet_Get_BsConst_PWM_boost_bypass_duty_SafeCopy2: operation=rp_CS_MemAbsGet.Get_BsConst_PWM_boost_bypass_duty_SafeCopy2
          OA_rp_CS_MemAbsGet_Get_BsConst_BsConst_Illumination_ReservedByte_SafeCopy2: operation=rp_CS_MemAbsGet.Get_BsConst_BsConst_Illumination_ReservedByte_SafeCopy2
          OA_rp_CS_MemAbsGet_Get_BsConst_Audio_Element: operation=rp_CS_MemAbsGet.Get_BsConst_Audio_Element
          OA_rp_CS_MemAbsGet_Get_BsConst_Warning_Element: operation=rp_CS_MemAbsGet.Get_BsConst_Warning_Element
          OA_rp_CS_MemAbsGet_Get_BsConst_RealTimeClock_Element: operation=rp_CS_MemAbsGet.Get_BsConst_RealTimeClock_Element
          OA_rp_CS_MemAbsGet_Get_BsConst_Communication_Element: operation=rp_CS_MemAbsGet.Get_BsConst_Communication_Element
          OA_rp_CS_MemAbsGet_Get_BsConst_Power_Element: operation=rp_CS_MemAbsGet.Get_BsConst_Power_Element
          OA_rp_CS_MemAbsGet_Get_BsConst_ServiceReminder_Element: operation=rp_CS_MemAbsGet.Get_BsConst_ServiceReminder_Element
          OA_rp_CS_MemAbsGet_Get_BsConst_EngOffTimer_Element: operation=rp_CS_MemAbsGet.Get_BsConst_EngOffTimer_Element
          OA_rp_CS_MemAbsGet_Get_BsCys_Certicificate_Element: operation=rp_CS_MemAbsGet.Get_BsCys_Certicificate_Element
          OA_rp_CS_MemAbsGet_Get_RefCys_Certicificate_Element: operation=rp_CS_MemAbsGet.Get_RefCys_Certicificate_Element
          OA_rp_CS_MemAbsGet_Get_RefCys_Certicificate1_Element: operation=rp_CS_MemAbsGet.Get_RefCys_Certicificate1_Element
          OA_rp_CS_MemAbsGet_Get_BsRt_Odometer_Element: operation=rp_CS_MemAbsGet.Get_BsRt_Odometer_Element
          OA_rp_CS_MemAbsGet_Get_BsRt_SpeedoGauge_Element: operation=rp_CS_MemAbsGet.Get_BsRt_SpeedoGauge_Element
          OA_rp_CS_MemAbsGet_Get_BsRt_TachoGauge_Element: operation=rp_CS_MemAbsGet.Get_BsRt_TachoGauge_Element
          OA_rp_CS_MemAbsGet_Get_BsRt_FuelGauge_Element: operation=rp_CS_MemAbsGet.Get_BsRt_FuelGauge_Element
          OA_rp_CS_MemAbsGet_Get_BsRt_TempGauge_Element: operation=rp_CS_MemAbsGet.Get_BsRt_TempGauge_Element
          OA_rp_CS_MemAbsGet_Get_BsRt_PowerGauge_Element: operation=rp_CS_MemAbsGet.Get_BsRt_PowerGauge_Element
          OA_rp_CS_MemAbsGet_Get_BsRt_OilGauge_Element: operation=rp_CS_MemAbsGet.Get_BsRt_OilGauge_Element
          OA_rp_CS_MemAbsGet_Get_BsRt_TripComputer_Element: operation=rp_CS_MemAbsGet.Get_BsRt_TripComputer_Element
          OA_rp_CS_MemAbsGet_Get_BsRt_Warning_Element: operation=rp_CS_MemAbsGet.Get_BsRt_Warning_Element
          OA_rp_CS_MemAbsGet_Get_BsRt_RealTimeClock_Element: operation=rp_CS_MemAbsGet.Get_BsRt_RealTimeClock_Element
          OA_rp_CS_MemAbsGet_Get_BsRt_Personalization_Element: operation=rp_CS_MemAbsGet.Get_BsRt_Personalization_Element
          OA_rp_CS_MemAbsGet_Get_BsRt_Illumination_Element: operation=rp_CS_MemAbsGet.Get_BsRt_Illumination_Element
          OA_rp_CS_MemAbsGet_Get_BsRt_CusDlt_Element: operation=rp_CS_MemAbsGet.Get_BsRt_CusDlt_Element
          OA_rp_CS_MemAbsGet_Get_BsReten_Odometer_Element: operation=rp_CS_MemAbsGet.Get_BsReten_Odometer_Element
          OA_rp_CS_MemAbsGet_Get_BsReten_Gauges_Element: operation=rp_CS_MemAbsGet.Get_BsReten_Gauges_Element
          OA_rp_CS_MemAbsGet_Get_BsReten_Tripcomputer_Element: operation=rp_CS_MemAbsGet.Get_BsReten_Tripcomputer_Element
          OA_rp_CS_MemAbsGet_Get_BsReten_Illumination_Element: operation=rp_CS_MemAbsGet.Get_BsReten_Illumination_Element
          OA_rp_CS_MemAbsGet_Get_BsReten_Audio_Element: operation=rp_CS_MemAbsGet.Get_BsReten_Audio_Element
          OA_rp_CS_MemAbsGet_Get_BsReten_Warning_Element: operation=rp_CS_MemAbsGet.Get_BsReten_Warning_Element
          OA_rp_CS_MemAbsGet_Get_BsReten_RealTimeClock_Element: operation=rp_CS_MemAbsGet.Get_BsReten_RealTimeClock_Element
          OA_rp_CS_MemAbsGet_Get_BsReten_Communication_Element: operation=rp_CS_MemAbsGet.Get_BsReten_Communication_Element
          OA_rp_CS_MemAbsGet_Get_BsReten_Personalization_Element: operation=rp_CS_MemAbsGet.Get_BsReten_Personalization_Element
          OA_rp_CS_MemAbsGet_Get_BsReten_Power_Element: operation=rp_CS_MemAbsGet.Get_BsReten_Power_Element
          OA_rp_CS_MemAbsGet_Get_BsReten_Display_Element: operation=rp_CS_MemAbsGet.Get_BsReten_Display_Element
          OA_rp_CS_MemAbsGet_Get_BsDiag_ErrorRecord_Element: operation=rp_CS_MemAbsGet.Get_BsDiag_ErrorRecord_Element
          OA_rp_CS_MemAbsGet_Get_BsDiag_Dtc_Element: operation=rp_CS_MemAbsGet.Get_BsDiag_Dtc_Element
          OA_rp_CS_RxCanMdl_RxCan_GetSignalValueU8Arr: operation=rp_CS_RxCanMdl.RxCan_GetSignalValueU8Arr
          OA_rp_CS_RxCanMdl_RxCan_SetSignalInitValue: operation=rp_CS_RxCanMdl.RxCan_SetSignalInitValue
          OA_rp_CS_RxCanMdl_RxCan_SetSignalInitValueU8Arr: operation=rp_CS_RxCanMdl.RxCan_SetSignalInitValueU8Arr
          OA_rp_CS_RxCanMdl_RxCan_SignalInvalidProcessingControl: operation=rp_CS_RxCanMdl.RxCan_SignalInvalidProcessingControl
          OA_rp_CS_RxCanMdl_RxCan_SignalMissingProcessingControl: operation=rp_CS_RxCanMdl.RxCan_SignalMissingProcessingControl
          OA_rp_CS_RxCanMdl_RxCan_SignalNRProcessingControl: operation=rp_CS_RxCanMdl.RxCan_SignalNRProcessingControl
          OA_rp_CS_RxCanMdl_RxCan_SignalGetJustRcvdStatus: operation=rp_CS_RxCanMdl.RxCan_SignalGetJustRcvdStatus
          OA_rp_CS_RxCanMdl_RxCan_SignalClearJustRcvdStatus: operation=rp_CS_RxCanMdl.RxCan_SignalClearJustRcvdStatus
          OA_rp_CS_RxCanMdl_RxCan_GetSignalValue: operation=rp_CS_RxCanMdl.RxCan_GetSignalValue
          OA_rp_CS_TxCanMdl_TxCan_ClearCanSignalTxConfirmation: operation=rp_CS_TxCanMdl.TxCan_ClearCanSignalTxConfirmation
          OA_rp_CS_TxCanMdl_TxCan_GetCanSignalTxConfirmation: operation=rp_CS_TxCanMdl.TxCan_GetCanSignalTxConfirmation
          OA_rp_CS_TxCanMdl_TxCan_SetSignalFromRetentionBuffer: operation=rp_CS_TxCanMdl.TxCan_SetSignalFromRetentionBuffer
          OA_rp_CS_TxCanMdl_TxCan_SetSignalValue: operation=rp_CS_TxCanMdl.TxCan_SetSignalValue
          OA_rp_CS_TxCanMdl_TxCan_SetSignalValueU8Arr: operation=rp_CS_TxCanMdl.TxCan_SetSignalValueU8Arr
  15 x constant specification:
    View_SpeedDigital_Speed_ValueValue0: value-spec=View_SpeedDigital_Speed_ValueValue0:0
    View_SpeedSubDispSpeedValValue0: value-spec=View_SpeedSubDispSpeedValValue0:0
    View_SpeedSubSpeedunitValue0: value-spec=View_SpeedSubSpeedunitValue0:0
    View_SpeedIgnitionSubstateValue0: value-spec=View_SpeedIgnitionSubstateValue0:0
    View_SpeedWSSCurrentClusterModeValue0: value-spec=View_SpeedWSSCurrentClusterModeValue0:0
    View_SpeedCountryCode_FuncValue0: value-spec=View_SpeedCountryCode_FuncValue0:0
    View_SpeedAppIdValue0: value-spec=View_SpeedAppIdValue0:0
    View_SpeedDiag_Digital_Speed_ValueValue0: value-spec=View_SpeedDiag_Digital_Speed_ValueValue0:0
    View_SpeedDisplayUnitValue0: value-spec=View_SpeedDisplayUnitValue0:0
    View_SpeedSP1_In_StatusValue0: value-spec=View_SpeedSP1_In_StatusValue0:0
    View_SpeedSpeed_Selection_TableValue0: value-spec=View_SpeedSpeed_Selection_TableValue0:0
    View_SpeedSpd_Target2_StatusValue0: value-spec=View_SpeedSpd_Target2_StatusValue0:0
    View_SpeedSpd_Target_StatusValue0: value-spec=View_SpeedSpd_Target_StatusValue0:0
    View_SpeedSpd_Trim2_StatusValue0: value-spec=View_SpeedSpd_Trim2_StatusValue0:0
    View_SpeedSpd_Trim_StatusValue0: value-spec=View_SpeedSpd_Trim_StatusValue0:0
  swc implementation IMPL_View_Speed: programming-language=C, behavior=IB_View_Speed
    code-descriptors:
      code CodeDescriptor
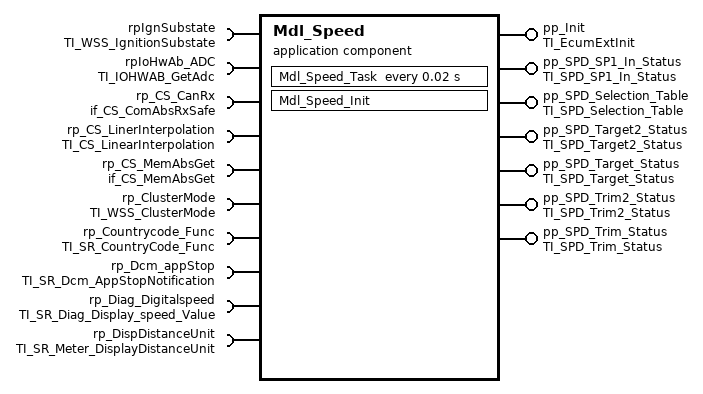
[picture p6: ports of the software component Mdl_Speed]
  application sw component type Mdl_Speed
    7 x provide port:
      pp_Init: server-com-spec{operation=TI_EcumExtInit/Init, queue-length=1}, provided-interface=TI_EcumExtInit
      pp_SPD_SP1_In_Status: nonqueued-sender-com-spec{data-element=SP1_In_Status, init-value=constant-reference=Mdl_SpeedSP1_In_StatusValue0}, provided-interface=TI_SPD_SP1_In_Status
      pp_SPD_Selection_Table: nonqueued-sender-com-spec{data-element=Speed_Selection_Table, init-value=constant-reference=Mdl_SpeedSpeed_Selection_TableValue0}, provided-interface=TI_SPD_Selection_Table
      pp_SPD_Target2_Status: nonqueued-sender-com-spec{data-element=Spd_Target2_Status, init-value=constant-reference=Mdl_SpeedSpd_Target2_StatusValue0}, provided-interface=TI_SPD_Target2_Status
      pp_SPD_Target_Status: nonqueued-sender-com-spec{data-element=Spd_Target_Status, init-value=constant-reference=Mdl_SpeedSpd_Target_StatusValue0}, provided-interface=TI_SPD_Target_Status
      pp_SPD_Trim2_Status: nonqueued-sender-com-spec{data-element=Spd_Trim2_Status, init-value=constant-reference=Mdl_SpeedSpd_Trim2_StatusValue0}, provided-interface=TI_SPD_Trim2_Status
      pp_SPD_Trim_Status: nonqueued-sender-com-spec{data-element=Spd_Trim_Status, init-value=constant-reference=Mdl_SpeedSpd_Trim_StatusValue0}, provided-interface=TI_SPD_Trim_Status
    10 x require port:
      rpIgnSubstate: nonqueued-receiver-com-spec{data-element=IgnitionSubstate, init-value=constant-reference=Mdl_SpeedIgnitionSubstateValue0}, required-interface=TI_WSS_IgnitionSubstate
      rpIoHwAb_ADC: required-interface=TI_IOHWAB_GetAdc
      rp_CS_CanRx: required-interface=if_CS_ComAbsRxSafe
      rp_CS_LinerInterpolation: required-interface=TI_CS_LinearInterpolation
      rp_CS_MemAbsGet: required-interface=if_CS_MemAbsGet
      rp_ClusterMode: nonqueued-receiver-com-spec{data-element=WSSCurrentClusterMode, init-value=constant-reference=Mdl_SpeedWSSCurrentClusterModeValue0}, required-interface=TI_WSS_ClusterMode
      rp_Countrycode_Func: nonqueued-receiver-com-spec{data-element=CountryCode_Func, init-value=constant-reference=Mdl_SpeedCountryCode_FuncValue0}, required-interface=TI_SR_CountryCode_Func
      rp_Dcm_appStop: nonqueued-receiver-com-spec{data-element=AppId, init-value=constant-reference=Mdl_SpeedAppIdValue0}, required-interface=TI_SR_Dcm_AppStopNotification
      rp_Diag_Digitalspeed: nonqueued-receiver-com-spec{data-element=Diag_Digital_Speed_Value, init-value=constant-reference=Mdl_SpeedDiag_Digital_Speed_ValueValue0}, required-interface=TI_SR_Diag_Display_speed_Value
      rp_DispDistanceUnit: nonqueued-receiver-com-spec{data-element=DisplayUnit, init-value=constant-reference=Mdl_SpeedDisplayUnitValue0}, required-interface=TI_SR_Meter_DisplayDistanceUnit
    behavior IB_Mdl_Speed
      operation invoked event OIE_pp_Init_Mdl_Speed_InitTrigByInit: start-on-event=Mdl_Speed_Init, operation=pp_Init.Init
      timing event TEMdl_Speed_Task: start-on-event=Mdl_Speed_Task, period=0.02
      port-api-options:
        enable-take-address=false, indirect-api=false, port=Mdl_Speed/pp_Init
        enable-take-address=false, indirect-api=false, port=pp_SPD_SP1_In_Status
        enable-take-address=false, indirect-api=false, port=pp_SPD_Selection_Table
        enable-take-address=false, indirect-api=false, port=pp_SPD_Target2_Status
        enable-take-address=false, indirect-api=false, port=pp_SPD_Target_Status
        enable-take-address=false, indirect-api=false, port=pp_SPD_Trim2_Status
        enable-take-address=false, indirect-api=false, port=pp_SPD_Trim_Status
        enable-take-address=false, indirect-api=false, port=Mdl_Speed/rpIgnSubstate
        enable-take-address=false, indirect-api=false, port=Mdl_Speed/rpIoHwAb_ADC
        enable-take-address=false, indirect-api=false, port=Mdl_Speed/rp_CS_CanRx
        enable-take-address=false, indirect-api=false, port=rp_CS_LinerInterpolation
        enable-take-address=false, indirect-api=false, port=Mdl_Speed/rp_CS_MemAbsGet
        enable-take-address=false, indirect-api=false, port=Mdl_Speed/rp_ClusterMode
        enable-take-address=false, indirect-api=false, port=Mdl_Speed/rp_Countrycode_Func
        enable-take-address=false, indirect-api=false, port=Mdl_Speed/rp_Dcm_appStop
        enable-take-address=false, indirect-api=false, port=Mdl_Speed/rp_Diag_Digitalspeed
        enable-take-address=false, indirect-api=false, port=Mdl_Speed/rp_DispDistanceUnit
      runnable Mdl_Speed_Init: can-be-invoked-concurrently=true
      runnable Mdl_Speed_Task: can-be-invoked-concurrently=true
        data-receive-point-by-arguments:
          6 x access:
            DRA_rpIgnSubstate_IgnitionSubstate: accessed-variable=rpIgnSubstate.IgnitionSubstate
            DRA_rp_ClusterMode_WSSCurrentClusterMode: accessed-variable=rp_ClusterMode.WSSCurrentClusterMode
            DRA_rp_Countrycode_Func_CountryCode_Func: accessed-variable=rp_Countrycode_Func.CountryCode_Func
            DRA_rp_Dcm_appStop_AppId: accessed-variable=rp_Dcm_appStop.AppId
            DRA_rp_Diag_Digitalspeed_Diag_Digital_Speed_Value: accessed-variable=rp_Diag_Digitalspeed.Diag_Digital_Speed_Value
            DRA_rp_DispDistanceUnit_DisplayUnit: accessed-variable=rp_DispDistanceUnit.DisplayUnit
        data-send-points:
          6 x access:
            DWA_pp_SPD_SP1_In_Status_SP1_In_Status: accessed-variable=pp_SPD_SP1_In_Status.SP1_In_Status
            DWA_pp_SPD_Selection_Table_Speed_Selection_Table: accessed-variable=pp_SPD_Selection_Table.Speed_Selection_Table
            DWA_pp_SPD_Target2_Status_Spd_Target2_Status: accessed-variable=pp_SPD_Target2_Status.Spd_Target2_Status
            DWA_pp_SPD_Target_Status_Spd_Target_Status: accessed-variable=pp_SPD_Target_Status.Spd_Target_Status
            DWA_pp_SPD_Trim2_Status_Spd_Trim2_Status: accessed-variable=pp_SPD_Trim2_Status.Spd_Trim2_Status
            DWA_pp_SPD_Trim_Status_Spd_Trim_Status: accessed-variable=pp_SPD_Trim_Status.Spd_Trim_Status
        110 x sync call, all with timeout=0.0:
          OA_rpIoHwAb_ADC_GetAsyncRawAdc: operation=rpIoHwAb_ADC.GetAsyncRawAdc
          OA_rpIoHwAb_ADC_GetSyncRawAdc: operation=rpIoHwAb_ADC.GetSyncRawAdc
          OA_rpIoHwAb_ADC_GetProcessedAdc: operation=rpIoHwAb_ADC.GetProcessedAdc
          OA_rp_CS_CanRx_RxCan_GetSignalValueU8Arr: operation=rp_CS_CanRx.RxCan_GetSignalValueU8Arr
          OA_rp_CS_CanRx_RxCan_SetSignalInitValue: operation=rp_CS_CanRx.RxCan_SetSignalInitValue
          OA_rp_CS_CanRx_RxCan_SetSignalInitValueU8Arr: operation=rp_CS_CanRx.RxCan_SetSignalInitValueU8Arr
          OA_rp_CS_CanRx_RxCan_SignalInvalidProcessingControl: operation=rp_CS_CanRx.RxCan_SignalInvalidProcessingControl
          OA_rp_CS_CanRx_RxCan_SignalMissingProcessingControl: operation=rp_CS_CanRx.RxCan_SignalMissingProcessingControl
          OA_rp_CS_CanRx_RxCan_SignalNRProcessingControl: operation=rp_CS_CanRx.RxCan_SignalNRProcessingControl
          OA_rp_CS_CanRx_RxCan_SignalGetJustRcvdStatus: operation=rp_CS_CanRx.RxCan_SignalGetJustRcvdStatus
          OA_rp_CS_CanRx_RxCan_SignalClearJustRcvdStatus: operation=rp_CS_CanRx.RxCan_SignalClearJustRcvdStatus
          OA_rp_CS_CanRx_RxCan_GetSignalValue: operation=rp_CS_CanRx.RxCan_GetSignalValue
          OA_rp_CS_LinerInterpolation_Get_LinearInterpolateWord: operation=rp_CS_LinerInterpolation.Get_LinearInterpolateWord
          OA_rp_CS_LinerInterpolation_Get_LinearInterpolateByte: operation=rp_CS_LinerInterpolation.Get_LinearInterpolateByte
          OA_rp_CS_LinerInterpolation_Get_LinearInterpolateSByte: operation=rp_CS_LinerInterpolation.Get_LinearInterpolateSByte
          OA_rp_CS_LinerInterpolation_Get_LinearInterpolateSWord: operation=rp_CS_LinerInterpolation.Get_LinearInterpolateSWord
          OA_rp_CS_MemAbsGet_Get_BsShare_SwUpdReflash_Element: operation=rp_CS_MemAbsGet.Get_BsShare_SwUpdReflash_Element
          OA_rp_CS_MemAbsGet_Get_BsShare_SwUpdFotaMode_Element: operation=rp_CS_MemAbsGet.Get_BsShare_SwUpdFotaMode_Element
          OA_rp_CS_MemAbsGet_Get_BsShare_SwUpdFotaFinPrint_Element: operation=rp_CS_MemAbsGet.Get_BsShare_SwUpdFotaFinPrint_Element
          OA_rp_CS_MemAbsGet_Get_BsShare_SwUpdFotaStatus_Element: operation=rp_CS_MemAbsGet.Get_BsShare_SwUpdFotaStatus_Element
          OA_rp_CS_MemAbsGet_Get_BsShare_SwUpdFotadecrypt_Element: operation=rp_CS_MemAbsGet.Get_BsShare_SwUpdFotadecrypt_Element
          OA_rp_CS_MemAbsGet_Get_BsShare_EcuPartNumber_Element: operation=rp_CS_MemAbsGet.Get_BsShare_EcuPartNumber_Element
          OA_rp_CS_MemAbsGet_Get_BsShare_VisteonPartNumber: operation=rp_CS_MemAbsGet.Get_BsShare_VisteonPartNumber
          OA_rp_CS_MemAbsGet_Get_BsShare_VisteonPCBPartNumber: operation=rp_CS_MemAbsGet.Get_BsShare_VisteonPCBPartNumber
          OA_rp_CS_MemAbsGet_Get_BsShare_ProductSerialNumber: operation=rp_CS_MemAbsGet.Get_BsShare_ProductSerialNumber
          OA_rp_CS_MemAbsGet_Get_BsShare_PCBSerialNumber: operation=rp_CS_MemAbsGet.Get_BsShare_PCBSerialNumber
          OA_rp_CS_MemAbsGet_Get_BsShare_SMTManufacturingDate: operation=rp_CS_MemAbsGet.Get_BsShare_SMTManufacturingDate
          OA_rp_CS_MemAbsGet_Get_BsShare_AssemblyManufacturingDate: operation=rp_CS_MemAbsGet.Get_BsShare_AssemblyManufacturingDate
          OA_rp_CS_MemAbsGet_Get_BsShare_SMTPlantNumber: operation=rp_CS_MemAbsGet.Get_BsShare_SMTPlantNumber
          OA_rp_CS_MemAbsGet_Get_BsShare_AssemblyPlantNumber: operation=rp_CS_MemAbsGet.Get_BsShare_AssemblyPlantNumber
          OA_rp_CS_MemAbsGet_Get_BsShare_HWModification: operation=rp_CS_MemAbsGet.Get_BsShare_HWModification
          OA_rp_CS_MemAbsGet_Get_BsShare_VisMeet_Element: operation=rp_CS_MemAbsGet.Get_BsShare_VisMeet_Element
          OA_rp_CS_MemAbsGet_Get_BsShare_VisMeet_EOLEntry_Element: operation=rp_CS_MemAbsGet.Get_BsShare_VisMeet_EOLEntry_Element
          OA_rp_CS_MemAbsGet_Get_BsShare_VehicleConfig_Element: operation=rp_CS_MemAbsGet.Get_BsShare_VehicleConfig_Element
          OA_rp_CS_MemAbsGet_Get_BsConst_SpeedoGauge_Element: operation=rp_CS_MemAbsGet.Get_BsConst_SpeedoGauge_Element
          OA_rp_CS_MemAbsGet_Get_BsConst_TachoGauge_Element: operation=rp_CS_MemAbsGet.Get_BsConst_TachoGauge_Element
          OA_rp_CS_MemAbsGet_Get_BsConst_FuelGauge_Element: operation=rp_CS_MemAbsGet.Get_BsConst_FuelGauge_Element
          OA_rp_CS_MemAbsGet_Get_BsConst_TempGauge_Element: operation=rp_CS_MemAbsGet.Get_BsConst_TempGauge_Element
          OA_rp_CS_MemAbsGet_Get_BsConst_PowerGauge_Element: operation=rp_CS_MemAbsGet.Get_BsConst_PowerGauge_Element
          OA_rp_CS_MemAbsGet_Get_BsConst_OilGauge_Element: operation=rp_CS_MemAbsGet.Get_BsConst_OilGauge_Element
          OA_rp_CS_MemAbsGet_Get_BsConst_TripComputer_Element: operation=rp_CS_MemAbsGet.Get_BsConst_TripComputer_Element
          OA_rp_CS_MemAbsGet_Get_BsConst_Compensation_Line_Slope_m: operation=rp_CS_MemAbsGet.Get_BsConst_Compensation_Line_Slope_m
          OA_rp_CS_MemAbsGet_Get_BsConst_Compensation_Line_Shift_b: operation=rp_CS_MemAbsGet.Get_BsConst_Compensation_Line_Shift_b
          OA_rp_CS_MemAbsGet_Get_BsConst_Lookup_Curve_HotSpot_Coef_X: operation=rp_CS_MemAbsGet.Get_BsConst_Lookup_Curve_HotSpot_Coef_X
          OA_rp_CS_MemAbsGet_Get_BsConst_Lookup_Curve_HotSpot_Coef_Y: operation=rp_CS_MemAbsGet.Get_BsConst_Lookup_Curve_HotSpot_Coef_Y
          OA_rp_CS_MemAbsGet_Get_BsConst_Temp_Threshold_Hysteresis_Derating: operation=rp_CS_MemAbsGet.Get_BsConst_Temp_Threshold_Hysteresis_Derating
          OA_rp_CS_MemAbsGet_Get_BsConst_Derating_Backlight_Disable: operation=rp_CS_MemAbsGet.Get_BsConst_Derating_Backlight_Disable
          OA_rp_CS_MemAbsGet_Get_BsConst_Temperature_Sensor_Conv: operation=rp_CS_MemAbsGet.Get_BsConst_Temperature_Sensor_Conv
          OA_rp_CS_MemAbsGet_Get_BsConst_PCB_Temperature_Sensor_Conv: operation=rp_CS_MemAbsGet.Get_BsConst_PCB_Temperature_Sensor_Conv
          OA_rp_CS_MemAbsGet_Get_BsConst_Display_Illum_Max_Level: operation=rp_CS_MemAbsGet.Get_BsConst_Display_Illum_Max_Level
          OA_rp_CS_MemAbsGet_Get_BsConst_PWM_boost_bypass_duty: operation=rp_CS_MemAbsGet.Get_BsConst_PWM_boost_bypass_duty
          OA_rp_CS_MemAbsGet_Get_BsConst_BsConst_Illumination_ReservedByte: operation=rp_CS_MemAbsGet.Get_BsConst_BsConst_Illumination_ReservedByte
          OA_rp_CS_MemAbsGet_Get_BsConst_Compensation_Line_Slope_m_SafeCopy1: operation=rp_CS_MemAbsGet.Get_BsConst_Compensation_Line_Slope_m_SafeCopy1
          OA_rp_CS_MemAbsGet_Get_BsConst_Compensation_Line_Shift_b_SafeCopy1: operation=rp_CS_MemAbsGet.Get_BsConst_Compensation_Line_Shift_b_SafeCopy1
          OA_rp_CS_MemAbsGet_Get_BsConst_Lookup_Curve_HotSpot_Coef_X_SafeCopy1: operation=rp_CS_MemAbsGet.Get_BsConst_Lookup_Curve_HotSpot_Coef_X_SafeCopy1
          OA_rp_CS_MemAbsGet_Get_BsConst_Lookup_Curve_HotSpot_Coef_Y_SafeCopy1: operation=rp_CS_MemAbsGet.Get_BsConst_Lookup_Curve_HotSpot_Coef_Y_SafeCopy1
          OA_rp_CS_MemAbsGet_Get_BsConst_Temp_Threshold_Hysteresis_Derating_SafeCopy1: operation=rp_CS_MemAbsGet.Get_BsConst_Temp_Threshold_Hysteresis_Derating_SafeCopy1
          OA_rp_CS_MemAbsGet_Get_BsConst_Derating_Backlight_Disable_SafeCopy1: operation=rp_CS_MemAbsGet.Get_BsConst_Derating_Backlight_Disable_SafeCopy1
          OA_rp_CS_MemAbsGet_Get_BsConst_Temperature_Sensor_Conv_SafeCopy1: operation=rp_CS_MemAbsGet.Get_BsConst_Temperature_Sensor_Conv_SafeCopy1
          OA_rp_CS_MemAbsGet_Get_BsConst_PCB_Temperature_Sensor_Conv_SafeCopy1: operation=rp_CS_MemAbsGet.Get_BsConst_PCB_Temperature_Sensor_Conv_SafeCopy1
          OA_rp_CS_MemAbsGet_Get_BsConst_Display_Illum_Max_Level_SafeCopy1: operation=rp_CS_MemAbsGet.Get_BsConst_Display_Illum_Max_Level_SafeCopy1
          OA_rp_CS_MemAbsGet_Get_BsConst_PWM_boost_bypass_duty_SafeCopy1: operation=rp_CS_MemAbsGet.Get_BsConst_PWM_boost_bypass_duty_SafeCopy1
          OA_rp_CS_MemAbsGet_Get_BsConst_BsConst_Illumination_ReservedByte_SafeCopy1: operation=rp_CS_MemAbsGet.Get_BsConst_BsConst_Illumination_ReservedByte_SafeCopy1
          OA_rp_CS_MemAbsGet_Get_BsConst_Compensation_Line_Slope_m_SafeCopy2: operation=rp_CS_MemAbsGet.Get_BsConst_Compensation_Line_Slope_m_SafeCopy2
          OA_rp_CS_MemAbsGet_Get_BsConst_Compensation_Line_Shift_b_SafeCopy2: operation=rp_CS_MemAbsGet.Get_BsConst_Compensation_Line_Shift_b_SafeCopy2
          OA_rp_CS_MemAbsGet_Get_BsConst_Lookup_Curve_HotSpot_Coef_X_SafeCopy2: operation=rp_CS_MemAbsGet.Get_BsConst_Lookup_Curve_HotSpot_Coef_X_SafeCopy2
          OA_rp_CS_MemAbsGet_Get_BsConst_Lookup_Curve_HotSpot_Coef_Y_SafeCopy2: operation=rp_CS_MemAbsGet.Get_BsConst_Lookup_Curve_HotSpot_Coef_Y_SafeCopy2
          OA_rp_CS_MemAbsGet_Get_BsConst_Temp_Threshold_Hysteresis_Derating_SafeCopy2: operation=rp_CS_MemAbsGet.Get_BsConst_Temp_Threshold_Hysteresis_Derating_SafeCopy2
          OA_rp_CS_MemAbsGet_Get_BsConst_Derating_Backlight_Disable_SafeCopy2: operation=rp_CS_MemAbsGet.Get_BsConst_Derating_Backlight_Disable_SafeCopy2
          OA_rp_CS_MemAbsGet_Get_BsConst_Temperature_Sensor_Conv_SafeCopy2: operation=rp_CS_MemAbsGet.Get_BsConst_Temperature_Sensor_Conv_SafeCopy2
          OA_rp_CS_MemAbsGet_Get_BsConst_PCB_Temperature_Sensor_Conv_SafeCopy2: operation=rp_CS_MemAbsGet.Get_BsConst_PCB_Temperature_Sensor_Conv_SafeCopy2
          OA_rp_CS_MemAbsGet_Get_BsConst_Display_Illum_Max_Level_SafeCopy2: operation=rp_CS_MemAbsGet.Get_BsConst_Display_Illum_Max_Level_SafeCopy2
          OA_rp_CS_MemAbsGet_Get_BsConst_PWM_boost_bypass_duty_SafeCopy2: operation=rp_CS_MemAbsGet.Get_BsConst_PWM_boost_bypass_duty_SafeCopy2
          OA_rp_CS_MemAbsGet_Get_BsConst_BsConst_Illumination_ReservedByte_SafeCopy2: operation=rp_CS_MemAbsGet.Get_BsConst_BsConst_Illumination_ReservedByte_SafeCopy2
          OA_rp_CS_MemAbsGet_Get_BsConst_Audio_Element: operation=rp_CS_MemAbsGet.Get_BsConst_Audio_Element
          OA_rp_CS_MemAbsGet_Get_BsConst_Warning_Element: operation=rp_CS_MemAbsGet.Get_BsConst_Warning_Element
          OA_rp_CS_MemAbsGet_Get_BsConst_RealTimeClock_Element: operation=rp_CS_MemAbsGet.Get_BsConst_RealTimeClock_Element
          OA_rp_CS_MemAbsGet_Get_BsConst_Communication_Element: operation=rp_CS_MemAbsGet.Get_BsConst_Communication_Element
          OA_rp_CS_MemAbsGet_Get_BsConst_Power_Element: operation=rp_CS_MemAbsGet.Get_BsConst_Power_Element
          OA_rp_CS_MemAbsGet_Get_BsConst_ServiceReminder_Element: operation=rp_CS_MemAbsGet.Get_BsConst_ServiceReminder_Element
          OA_rp_CS_MemAbsGet_Get_BsConst_EngOffTimer_Element: operation=rp_CS_MemAbsGet.Get_BsConst_EngOffTimer_Element
          OA_rp_CS_MemAbsGet_Get_BsCys_Certicificate_Element: operation=rp_CS_MemAbsGet.Get_BsCys_Certicificate_Element
          OA_rp_CS_MemAbsGet_Get_RefCys_Certicificate_Element: operation=rp_CS_MemAbsGet.Get_RefCys_Certicificate_Element
          OA_rp_CS_MemAbsGet_Get_RefCys_Certicificate1_Element: operation=rp_CS_MemAbsGet.Get_RefCys_Certicificate1_Element
          OA_rp_CS_MemAbsGet_Get_BsRt_Odometer_Element: operation=rp_CS_MemAbsGet.Get_BsRt_Odometer_Element
          OA_rp_CS_MemAbsGet_Get_BsRt_SpeedoGauge_Element: operation=rp_CS_MemAbsGet.Get_BsRt_SpeedoGauge_Element
          OA_rp_CS_MemAbsGet_Get_BsRt_TachoGauge_Element: operation=rp_CS_MemAbsGet.Get_BsRt_TachoGauge_Element
          OA_rp_CS_MemAbsGet_Get_BsRt_FuelGauge_Element: operation=rp_CS_MemAbsGet.Get_BsRt_FuelGauge_Element
          OA_rp_CS_MemAbsGet_Get_BsRt_TempGauge_Element: operation=rp_CS_MemAbsGet.Get_BsRt_TempGauge_Element
          OA_rp_CS_MemAbsGet_Get_BsRt_PowerGauge_Element: operation=rp_CS_MemAbsGet.Get_BsRt_PowerGauge_Element
          OA_rp_CS_MemAbsGet_Get_BsRt_OilGauge_Element: operation=rp_CS_MemAbsGet.Get_BsRt_OilGauge_Element
          OA_rp_CS_MemAbsGet_Get_BsRt_TripComputer_Element: operation=rp_CS_MemAbsGet.Get_BsRt_TripComputer_Element
          OA_rp_CS_MemAbsGet_Get_BsRt_Warning_Element: operation=rp_CS_MemAbsGet.Get_BsRt_Warning_Element
          OA_rp_CS_MemAbsGet_Get_BsRt_RealTimeClock_Element: operation=rp_CS_MemAbsGet.Get_BsRt_RealTimeClock_Element
          OA_rp_CS_MemAbsGet_Get_BsRt_Personalization_Element: operation=rp_CS_MemAbsGet.Get_BsRt_Personalization_Element
          OA_rp_CS_MemAbsGet_Get_BsRt_Illumination_Element: operation=rp_CS_MemAbsGet.Get_BsRt_Illumination_Element
          OA_rp_CS_MemAbsGet_Get_BsRt_CusDlt_Element: operation=rp_CS_MemAbsGet.Get_BsRt_CusDlt_Element
          OA_rp_CS_MemAbsGet_Get_BsReten_Odometer_Element: operation=rp_CS_MemAbsGet.Get_BsReten_Odometer_Element
          OA_rp_CS_MemAbsGet_Get_BsReten_Gauges_Element: operation=rp_CS_MemAbsGet.Get_BsReten_Gauges_Element
          OA_rp_CS_MemAbsGet_Get_BsReten_Tripcomputer_Element: operation=rp_CS_MemAbsGet.Get_BsReten_Tripcomputer_Element
          OA_rp_CS_MemAbsGet_Get_BsReten_Illumination_Element: operation=rp_CS_MemAbsGet.Get_BsReten_Illumination_Element
          OA_rp_CS_MemAbsGet_Get_BsReten_Audio_Element: operation=rp_CS_MemAbsGet.Get_BsReten_Audio_Element
          OA_rp_CS_MemAbsGet_Get_BsReten_Warning_Element: operation=rp_CS_MemAbsGet.Get_BsReten_Warning_Element
          OA_rp_CS_MemAbsGet_Get_BsReten_RealTimeClock_Element: operation=rp_CS_MemAbsGet.Get_BsReten_RealTimeClock_Element
          OA_rp_CS_MemAbsGet_Get_BsReten_Communication_Element: operation=rp_CS_MemAbsGet.Get_BsReten_Communication_Element
          OA_rp_CS_MemAbsGet_Get_BsReten_Personalization_Element: operation=rp_CS_MemAbsGet.Get_BsReten_Personalization_Element
          OA_rp_CS_MemAbsGet_Get_BsReten_Power_Element: operation=rp_CS_MemAbsGet.Get_BsReten_Power_Element
          OA_rp_CS_MemAbsGet_Get_BsReten_Display_Element: operation=rp_CS_MemAbsGet.Get_BsReten_Display_Element
          OA_rp_CS_MemAbsGet_Get_BsDiag_ErrorRecord_Element: operation=rp_CS_MemAbsGet.Get_BsDiag_ErrorRecord_Element
          OA_rp_CS_MemAbsGet_Get_BsDiag_Dtc_Element: operation=rp_CS_MemAbsGet.Get_BsDiag_Dtc_Element
  12 x constant specification:
    Mdl_SpeedSP1_In_StatusValue0: value-spec=Mdl_SpeedSP1_In_StatusValue0:0
    Mdl_SpeedSpeed_Selection_TableValue0: value-spec=Mdl_SpeedSpeed_Selection_TableValue0:0
    Mdl_SpeedSpd_Target2_StatusValue0: value-spec=Mdl_SpeedSpd_Target2_StatusValue0:0
    Mdl_SpeedSpd_Target_StatusValue0: value-spec=Mdl_SpeedSpd_Target_StatusValue0:0
    Mdl_SpeedSpd_Trim2_StatusValue0: value-spec=Mdl_SpeedSpd_Trim2_StatusValue0:0
    Mdl_SpeedSpd_Trim_StatusValue0: value-spec=Mdl_SpeedSpd_Trim_StatusValue0:0
    Mdl_SpeedIgnitionSubstateValue0: value-spec=Mdl_SpeedIgnitionSubstateValue0:0
    Mdl_SpeedWSSCurrentClusterModeValue0: value-spec=Mdl_SpeedWSSCurrentClusterModeValue0:0
    Mdl_SpeedCountryCode_FuncValue0: value-spec=Mdl_SpeedCountryCode_FuncValue0:0
    Mdl_SpeedAppIdValue0: value-spec=Mdl_SpeedAppIdValue0:0
    Mdl_SpeedDiag_Digital_Speed_ValueValue0: value-spec=Mdl_SpeedDiag_Digital_Speed_ValueValue0:0
    Mdl_SpeedDisplayUnitValue0: value-spec=Mdl_SpeedDisplayUnitValue0:0
  swc implementation IMPL_Mdl_Speed: programming-language=C, behavior=IB_Mdl_Speed
    code-descriptors:
      code CodeDescriptor
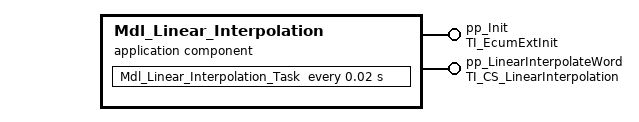
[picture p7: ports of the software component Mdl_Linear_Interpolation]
  application sw component type Mdl_Linear_Interpolation
    provide port pp_Init: server-com-spec{operation=TI_EcumExtInit/Init, queue-length=1}, provided-interface=TI_EcumExtInit
    provide port pp_LinearInterpolateWord: provided-interface=TI_CS_LinearInterpolation
      provided-com-specs:
        operation=Get_LinearInterpolateByte, queue-length=1
        operation=Get_LinearInterpolateSByte, queue-length=1
        operation=Get_LinearInterpolateSWord, queue-length=1
        operation=Get_LinearInterpolateWord, queue-length=1
    behavior IB_Mdl_Linear_Interpolation
      5 x operation invoked event:
        OIE_pp_LinearInterpolateWord_Mdl_Linear_Interpolation_Get_LinearInterpolateByteTrigByGet_LinearInterpolateByte: start-on-event=Mdl_Linear_Interpolation_Get_LinearInterpolateByte, operation=pp_LinearInterpolateWord.Get_LinearInterpolateByte
        OIE_pp_LinearInterpolateWord_Mdl_Linear_Interpolation_Get_LinearInterpolateSByteTrigByGet_LinearInterpolateSByte: start-on-event=Mdl_Linear_Interpolation_Get_LinearInterpolateSByte, operation=pp_LinearInterpolateWord.Get_LinearInterpolateSByte
        OIE_pp_LinearInterpolateWord_Mdl_Linear_Interpolation_Get_LinearInterpolateSWordTrigByGet_LinearInterpolateSWord: start-on-event=Mdl_Linear_Interpolation_Get_LinearInterpolateSWord, operation=pp_LinearInterpolateWord.Get_LinearInterpolateSWord
        OIE_pp_LinearInterpolateWord_Mdl_Linear_Interpolation_Get_LinearInterpolateWordTrigByGet_LinearInterpolateWord: start-on-event=Mdl_Linear_Interpolation_Get_LinearInterpolateWord, operation=pp_LinearInterpolateWord.Get_LinearInterpolateWord
        OIE_pp_Init_Mdl_Linear_Interpolation_InitTrigByInit: start-on-event=Mdl_Linear_Interpolation_Init, operation=pp_Init.Init
      timing event TEMdl_Linear_Interpolation_Task: start-on-event=Mdl_Linear_Interpolation_Task, period=0.02
      port-api-options:
        enable-take-address=false, indirect-api=false, port=Mdl_Linear_Interpolation/pp_Init
        enable-take-address=false, indirect-api=false, port=pp_LinearInterpolateWord
      6 x runnable, all with can-be-invoked-concurrently=true:
        Mdl_Linear_Interpolation_Get_LinearInterpolateByte
        Mdl_Linear_Interpolation_Get_LinearInterpolateSByte
        Mdl_Linear_Interpolation_Get_LinearInterpolateSWord
        Mdl_Linear_Interpolation_Get_LinearInterpolateWord
        Mdl_Linear_Interpolation_Init
        Mdl_Linear_Interpolation_Task
  swc implementation IMPL_Mdl_Linear_Interpolation: programming-language=C, behavior=IB_Mdl_Linear_Interpolation
    code-descriptors:
      code CodeDescriptor
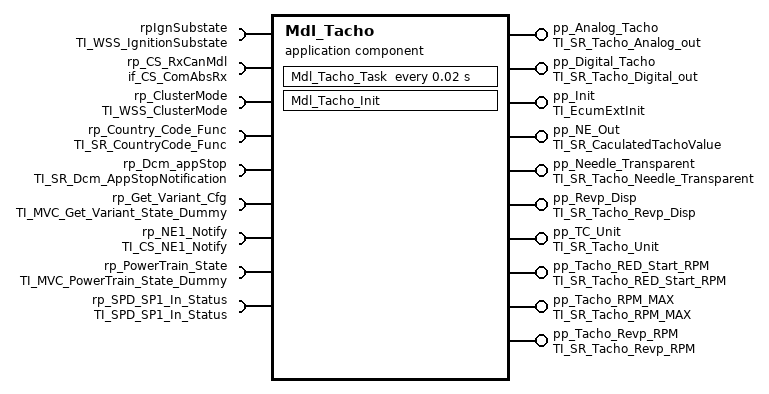
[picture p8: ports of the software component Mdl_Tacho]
  application sw component type Mdl_Tacho
    10 x provide port:
      pp_Analog_Tacho: nonqueued-sender-com-spec{data-element=Analog_Tacho, init-value=constant-reference=Mdl_TachoAnalog_TachoValue0}, provided-interface=TI_SR_Tacho_Analog_out
      pp_Digital_Tacho: nonqueued-sender-com-spec{data-element=Digital_Tacho, init-value=constant-reference=Mdl_TachoDigital_TachoValue0}, provided-interface=TI_SR_Tacho_Digital_out
      pp_Init: server-com-spec{operation=TI_EcumExtInit/Init, queue-length=1}, provided-interface=TI_EcumExtInit
      pp_NE_Out: nonqueued-sender-com-spec{data-element=CalTachoValue, init-value=constant-reference=Mdl_TachoCalTachoValueValue0}, provided-interface=TI_SR_CaculatedTachoValue
      pp_Needle_Transparent: nonqueued-sender-com-spec{data-element=Needle_TR, init-value=constant-reference=Mdl_TachoNeedle_TRValue0}, provided-interface=TI_SR_Tacho_Needle_Transparent
      pp_Revp_Disp: nonqueued-sender-com-spec{data-element=REVP_DISP, uses-end-to-end-protection=0, init-value=constant-reference=Mdl_TachoREVP_DISPValue0}, provided-interface=TI_SR_Tacho_Revp_Disp
      pp_TC_Unit: nonqueued-sender-com-spec{data-element=Digital_TachoUnit, uses-end-to-end-protection=0, init-value=constant-reference=Mdl_TachoDigital_TachoUnitValue0}, provided-interface=TI_SR_Tacho_Unit
      pp_Tacho_RED_Start_RPM: nonqueued-sender-com-spec{data-element=RED_Start_RPM, init-value=constant-reference=Mdl_TachoRED_Start_RPMValue0}, provided-interface=TI_SR_Tacho_RED_Start_RPM
      pp_Tacho_RPM_MAX: nonqueued-sender-com-spec{data-element=REVP_RPM_MAX, init-value=constant-reference=Mdl_TachoREVP_RPM_MAXValue0}, provided-interface=TI_SR_Tacho_RPM_MAX
      pp_Tacho_Revp_RPM: nonqueued-sender-com-spec{data-element=REVP_RPM, init-value=constant-reference=Mdl_TachoREVP_RPMValue0}, provided-interface=TI_SR_Tacho_Revp_RPM
    9 x require port:
      rpIgnSubstate: nonqueued-receiver-com-spec{data-element=IgnitionSubstate, init-value=constant-reference=Mdl_TachoIgnitionSubstateValue0}, required-interface=TI_WSS_IgnitionSubstate
      rp_CS_RxCanMdl: required-interface=if_CS_ComAbsRx
      rp_ClusterMode: nonqueued-receiver-com-spec{data-element=WSSCurrentClusterMode, init-value=constant-reference=Mdl_TachoWSSCurrentClusterModeValue0}, required-interface=TI_WSS_ClusterMode
      rp_Country_Code_Func: nonqueued-receiver-com-spec{data-element=CountryCode_Func, init-value=constant-reference=Mdl_TachoCountryCode_FuncValue0}, required-interface=TI_SR_CountryCode_Func
      rp_Dcm_appStop: nonqueued-receiver-com-spec{data-element=AppId, init-value=constant-reference=Mdl_TachoAppIdValue0}, required-interface=TI_SR_Dcm_AppStopNotification
      rp_Get_Variant_Cfg: required-interface=TI_MVC_Get_Variant_State_Dummy
      rp_NE1_Notify: required-interface=TI_CS_NE1_Notify
      rp_PowerTrain_State: nonqueued-receiver-com-spec{data-element=PowerTrain_Flag, init-value=constant-reference=Mdl_TachoPowerTrain_FlagValue0}, required-interface=TI_MVC_PowerTrain_State_Dummy
      rp_SPD_SP1_In_Status: nonqueued-receiver-com-spec{data-element=SP1_In_Status, init-value=constant-reference=Mdl_TachoSP1_In_StatusValue0}, required-interface=TI_SPD_SP1_In_Status
    behavior IB_Mdl_Tacho
      operation invoked event OIE_pp_Init_Mdl_Tacho_InitTrigByInit: start-on-event=Mdl_Tacho_Init, operation=pp_Init.Init
      timing event TEMdl_Tacho_Task: start-on-event=Mdl_Tacho_Task, period=0.02
      port-api-options:
        enable-take-address=false, indirect-api=false, port=pp_Analog_Tacho
        enable-take-address=false, indirect-api=false, port=pp_Digital_Tacho
        enable-take-address=false, indirect-api=false, port=Mdl_Tacho/pp_Init
        enable-take-address=false, indirect-api=false, port=pp_NE_Out
        enable-take-address=false, indirect-api=false, port=pp_Needle_Transparent
        enable-take-address=false, indirect-api=false, port=pp_Revp_Disp
        enable-take-address=false, indirect-api=false, port=pp_TC_Unit
        enable-take-address=false, indirect-api=false, port=pp_Tacho_RED_Start_RPM
        enable-take-address=false, indirect-api=false, port=pp_Tacho_RPM_MAX
        enable-take-address=false, indirect-api=false, port=pp_Tacho_Revp_RPM
        enable-take-address=false, indirect-api=false, port=Mdl_Tacho/rpIgnSubstate
        enable-take-address=false, indirect-api=false, port=Mdl_Tacho/rp_CS_RxCanMdl
        enable-take-address=false, indirect-api=false, port=Mdl_Tacho/rp_ClusterMode
        enable-take-address=false, indirect-api=false, port=rp_Country_Code_Func
        enable-take-address=false, indirect-api=false, port=Mdl_Tacho/rp_Dcm_appStop
        enable-take-address=false, indirect-api=false, port=Mdl_Tacho/rp_Get_Variant_Cfg
        enable-take-address=false, indirect-api=false, port=rp_NE1_Notify
        enable-take-address=false, indirect-api=false, port=Mdl_Tacho/rp_PowerTrain_State
        enable-take-address=false, indirect-api=false, port=Mdl_Tacho/rp_SPD_SP1_In_Status
      runnable Mdl_Tacho_Init: can-be-invoked-concurrently=true
      runnable Mdl_Tacho_Task: can-be-invoked-concurrently=true
        data-receive-point-by-arguments:
          6 x access:
            DRA_rpIgnSubstate_IgnitionSubstate: accessed-variable=rpIgnSubstate.IgnitionSubstate
            DRA_rp_ClusterMode_WSSCurrentClusterMode: accessed-variable=rp_ClusterMode.WSSCurrentClusterMode
            DRA_rp_Country_Code_Func_CountryCode_Func: accessed-variable=rp_Country_Code_Func.CountryCode_Func
            DRA_rp_Dcm_appStop_AppId: accessed-variable=rp_Dcm_appStop.AppId
            DRA_rp_PowerTrain_State_PowerTrain_Flag: accessed-variable=rp_PowerTrain_State.PowerTrain_Flag
            DRA_rp_SPD_SP1_In_Status_SP1_In_Status: accessed-variable=rp_SPD_SP1_In_Status.SP1_In_Status
        data-send-points:
          9 x access:
            DWA_pp_Analog_Tacho_Analog_Tacho: accessed-variable=pp_Analog_Tacho.Analog_Tacho
            DWA_pp_Digital_Tacho_Digital_Tacho: accessed-variable=pp_Digital_Tacho.Digital_Tacho
            DWA_pp_NE_Out_CalTachoValue: accessed-variable=pp_NE_Out.CalTachoValue
            DWA_pp_Needle_Transparent_Needle_TR: accessed-variable=pp_Needle_Transparent.Needle_TR
            DWA_pp_Revp_Disp_REVP_DISP: accessed-variable=pp_Revp_Disp.REVP_DISP
            DWA_pp_TC_Unit_Digital_TachoUnit: accessed-variable=pp_TC_Unit.Digital_TachoUnit
            DWA_pp_Tacho_RED_Start_RPM_RED_Start_RPM: accessed-variable=pp_Tacho_RED_Start_RPM.RED_Start_RPM
            DWA_pp_Tacho_RPM_MAX_REVP_RPM_MAX: accessed-variable=pp_Tacho_RPM_MAX.REVP_RPM_MAX
            DWA_pp_Tacho_Revp_RPM_REVP_RPM: accessed-variable=pp_Tacho_Revp_RPM.REVP_RPM
        11 x sync call, all with timeout=0.0:
          OA_rp_CS_RxCanMdl_RxCan_GetSignalValueU8Arr: operation=rp_CS_RxCanMdl.RxCan_GetSignalValueU8Arr
          OA_rp_CS_RxCanMdl_RxCan_SetSignalInitValue: operation=rp_CS_RxCanMdl.RxCan_SetSignalInitValue
          OA_rp_CS_RxCanMdl_RxCan_SetSignalInitValueU8Arr: operation=rp_CS_RxCanMdl.RxCan_SetSignalInitValueU8Arr
          OA_rp_CS_RxCanMdl_RxCan_SignalInvalidProcessingControl: operation=rp_CS_RxCanMdl.RxCan_SignalInvalidProcessingControl
          OA_rp_CS_RxCanMdl_RxCan_SignalMissingProcessingControl: operation=rp_CS_RxCanMdl.RxCan_SignalMissingProcessingControl
          OA_rp_CS_RxCanMdl_RxCan_SignalNRProcessingControl: operation=rp_CS_RxCanMdl.RxCan_SignalNRProcessingControl
          OA_rp_CS_RxCanMdl_RxCan_SignalGetJustRcvdStatus: operation=rp_CS_RxCanMdl.RxCan_SignalGetJustRcvdStatus
          OA_rp_CS_RxCanMdl_RxCan_SignalClearJustRcvdStatus: operation=rp_CS_RxCanMdl.RxCan_SignalClearJustRcvdStatus
          OA_rp_CS_RxCanMdl_RxCan_GetSignalValue: operation=rp_CS_RxCanMdl.RxCan_GetSignalValue
          OA_rp_Get_Variant_Cfg_Get_Variant_Config_State: operation=rp_Get_Variant_Cfg.Get_Variant_Config_State
          OA_rp_NE1_Notify_NE1_Recieve_Notify_Value: operation=rp_NE1_Notify.NE1_Recieve_Notify_Value
  15 x constant specification:
    Mdl_TachoAnalog_TachoValue0: value-spec=Mdl_TachoAnalog_TachoValue0:0
    Mdl_TachoDigital_TachoValue0: value-spec=Mdl_TachoDigital_TachoValue0:0
    Mdl_TachoCalTachoValueValue0: value-spec=Mdl_TachoCalTachoValueValue0:0
    Mdl_TachoNeedle_TRValue0: value-spec=Mdl_TachoNeedle_TRValue0:0
    Mdl_TachoREVP_DISPValue0: value-spec=Mdl_TachoREVP_DISPValue0:false
    Mdl_TachoDigital_TachoUnitValue0: value-spec=Mdl_TachoDigital_TachoUnitValue0:false
    Mdl_TachoRED_Start_RPMValue0: value-spec=Mdl_TachoRED_Start_RPMValue0:0
    Mdl_TachoREVP_RPM_MAXValue0: value-spec=Mdl_TachoREVP_RPM_MAXValue0:0
    Mdl_TachoREVP_RPMValue0: value-spec=Mdl_TachoREVP_RPMValue0:0
    Mdl_TachoIgnitionSubstateValue0: value-spec=Mdl_TachoIgnitionSubstateValue0:0
    Mdl_TachoWSSCurrentClusterModeValue0: value-spec=Mdl_TachoWSSCurrentClusterModeValue0:0
    Mdl_TachoCountryCode_FuncValue0: value-spec=Mdl_TachoCountryCode_FuncValue0:0
    Mdl_TachoAppIdValue0: value-spec=Mdl_TachoAppIdValue0:0
    Mdl_TachoPowerTrain_FlagValue0: value-spec=Mdl_TachoPowerTrain_FlagValue0:0
    Mdl_TachoSP1_In_StatusValue0: value-spec=Mdl_TachoSP1_In_StatusValue0:0
  swc implementation IMPL_Mdl_Tacho: programming-language=C, behavior=IB_Mdl_Tacho
    code-descriptors:
      code CodeDescriptor
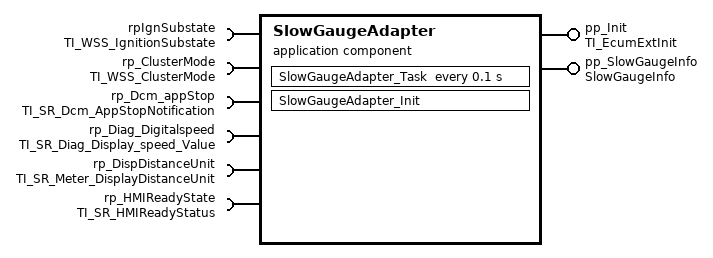
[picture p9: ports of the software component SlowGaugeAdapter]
  application sw component type SlowGaugeAdapter
    provide port pp_Init: server-com-spec{operation=TI_EcumExtInit/Init, queue-length=1}, provided-interface=TI_EcumExtInit
    provide port pp_SlowGaugeInfo: nonqueued-sender-com-spec{data-element=SlowGaugeInfoData, init-value=constant-reference=SlowGaugeAdapterSlowGaugeInfoDataValue0}, provided-interface=SlowGaugeInfo
    6 x require port:
      rpIgnSubstate: nonqueued-receiver-com-spec{data-element=IgnitionSubstate, init-value=constant-reference=SlowGaugeAdapterIgnitionSubstateValue0}, required-interface=TI_WSS_IgnitionSubstate
      rp_ClusterMode: nonqueued-receiver-com-spec{data-element=WSSCurrentClusterMode, init-value=constant-reference=SlowGaugeAdapterWSSCurrentClusterModeValue0}, required-interface=TI_WSS_ClusterMode
      rp_Dcm_appStop: nonqueued-receiver-com-spec{data-element=AppId, init-value=constant-reference=SlowGaugeAdapterAppIdValue0}, required-interface=TI_SR_Dcm_AppStopNotification
      rp_Diag_Digitalspeed: nonqueued-receiver-com-spec{data-element=Diag_Digital_Speed_Value, init-value=constant-reference=SlowGaugeAdapterDiag_Digital_Speed_ValueValue0}, required-interface=TI_SR_Diag_Display_speed_Value
      rp_DispDistanceUnit: nonqueued-receiver-com-spec{data-element=DisplayUnit, init-value=constant-reference=SlowGaugeAdapterDisplayUnitValue0}, required-interface=TI_SR_Meter_DisplayDistanceUnit
      rp_HMIReadyState: nonqueued-receiver-com-spec{data-element=HMI_ReadyStatus, init-value=constant-reference=SlowGaugeAdapterHMI_ReadyStatusValue0}, required-interface=TI_SR_HMIReadyStatus
    behavior IB_SlowGaugeAdapter
      operation invoked event OIE_pp_Init_SlowGaugeAdapter_InitTrigByInit: start-on-event=SlowGaugeAdapter_Init, operation=pp_Init.Init
      timing event TESlowGaugeAdapter_Task: start-on-event=SlowGaugeAdapter_Task, period=0.1
      port-api-options:
        enable-take-address=false, indirect-api=false, port=SlowGaugeAdapter/pp_Init
        enable-take-address=false, indirect-api=false, port=pp_SlowGaugeInfo
        enable-take-address=false, indirect-api=false, port=SlowGaugeAdapter/rpIgnSubstate
        enable-take-address=false, indirect-api=false, port=SlowGaugeAdapter/rp_ClusterMode
        enable-take-address=false, indirect-api=false, port=SlowGaugeAdapter/rp_Dcm_appStop
        enable-take-address=false, indirect-api=false, port=SlowGaugeAdapter/rp_Diag_Digitalspeed
        enable-take-address=false, indirect-api=false, port=SlowGaugeAdapter/rp_DispDistanceUnit
        enable-take-address=false, indirect-api=false, port=SlowGaugeAdapter/rp_HMIReadyState
      runnable SlowGaugeAdapter_Init: can-be-invoked-concurrently=true
      runnable SlowGaugeAdapter_Task: can-be-invoked-concurrently=true
        data-receive-point-by-arguments:
          6 x access:
            DRA_rpIgnSubstate_IgnitionSubstate: accessed-variable=rpIgnSubstate.IgnitionSubstate
            DRA_rp_ClusterMode_WSSCurrentClusterMode: accessed-variable=rp_ClusterMode.WSSCurrentClusterMode
            DRA_rp_Dcm_appStop_AppId: accessed-variable=rp_Dcm_appStop.AppId
            DRA_rp_Diag_Digitalspeed_Diag_Digital_Speed_Value: accessed-variable=rp_Diag_Digitalspeed.Diag_Digital_Speed_Value
            DRA_rp_DispDistanceUnit_DisplayUnit: accessed-variable=rp_DispDistanceUnit.DisplayUnit
            DRA_rp_HMIReadyState_HMI_ReadyStatus: accessed-variable=rp_HMIReadyState.HMI_ReadyStatus
        data-send-points:
          access DWA_pp_SlowGaugeInfo_SlowGaugeInfoData: accessed-variable=pp_SlowGaugeInfo.SlowGaugeInfoData
  7 x constant specification:
    SlowGaugeAdapterSlowGaugeInfoDataValue0: value-spec={short-label=SlowGaugeAdapterSlowGaugeInfoDataValue0, fields={short-label=SlowGaugeAdapterSlowGaugeInfoDataValue_0, fields=[SlowGaugeAdaptergaugeInfoValue_0:0, SlowGaugeAdaptergaugeInfoValue_1:0, SlowGaugeAdaptergaugeInfoValue_2:0, SlowGaugeAdaptergaugeInfoValue_3:0, SlowGaugeAdaptergaugeInfoValue_4:0]}}
    SlowGaugeAdapterIgnitionSubstateValue0: value-spec=SlowGaugeAdapterIgnitionSubstateValue0:0
    SlowGaugeAdapterWSSCurrentClusterModeValue0: value-spec=SlowGaugeAdapterWSSCurrentClusterModeValue0:0
    SlowGaugeAdapterAppIdValue0: value-spec=SlowGaugeAdapterAppIdValue0:0
    SlowGaugeAdapterDiag_Digital_Speed_ValueValue0: value-spec=SlowGaugeAdapterDiag_Digital_Speed_ValueValue0:0
    SlowGaugeAdapterDisplayUnitValue0: value-spec=SlowGaugeAdapterDisplayUnitValue0:0
    SlowGaugeAdapterHMI_ReadyStatusValue0: value-spec=SlowGaugeAdapterHMI_ReadyStatusValue0:0
  swc implementation IMPL_SlowGaugeAdapter: programming-language=C, behavior=IB_SlowGaugeAdapter
    code-descriptors:
      code CodeDescriptor
  application sw component type CUpdateCdd
    9 x provide port:
      pp_CS_UpdateCdd_GenericDIDRequestHandler: server-com-spec{operation=UpdateCdd_GenericDIDRequestHandler, queue-length=1}, provided-interface=TI_UpdateCdd_GenericDIDRequestHandler
      pp_CS_UpdateCdd_GenericDownloadRequestHandler: server-com-spec{operation=UpdateCdd_GenericRequestDownloadHandler, queue-length=1}, provided-interface=TI_UpdateCdd_GenericRequestDownloadHandler
      pp_CS_UpdateCdd_GenericProgSessionRequest: server-com-spec{operation=UpdateCdd_GenericProgSessionRequest, queue-length=1}, provided-interface=TI_UpdateCdd_GenericProgSessionRequest
      pp_CS_UpdateCdd_GenericRIDRequestHandler: server-com-spec{operation=UpdateCdd_GenericRIDRequestHandler, queue-length=1}, provided-interface=TI_UpdateCdd_GenericRIDRequestHandler
      pp_CS_UpdateCdd_GenericTransferDataHandler: server-com-spec{operation=UpdateCdd_GenericTransferDataHandler, queue-length=1}, provided-interface=TI_UpdateCdd_GenericTransferDataHandler
      pp_CS_UpdateCdd_GenericTransferExitHandler: server-com-spec{operation=UpdateCdd_GenericTransferExitHandler, queue-length=1}, provided-interface=TI_UpdateCdd_GenericTransferExitHandler
      pp_CmpLibCmd_CUpdateCdd: server-com-spec{operation=Impl_OnCommand, queue-length=1}, provided-interface=if_CS_ModeOnCommand
      pp_SR_UpdateLongServiceRequest: queued-sender-com-spec=UpdateLongServiceReqData, provided-interface=UpdateLongServiceReq
      pp_SR_UpdateShortServiceRequest: queued-sender-com-spec=UpdateShortServiceReqData, provided-interface=UpdateShortServiceReq
    require port rp_SR_UpdateShortServiceResponse: queued-receiver-com-spec{data-element=UpdateShortServiceRespData, queue-length=2}, required-interface=UpdateShortServiceResp
    behavior IB_CUpdateCdd
      timing event TECUpdateCdd_Impl_MainFunction: start-on-event=CUpdateCdd_Impl_MainFunction, period=0.01
      operation invoked event OIE_pp_CmpLibCmd_CUpdateCdd_CUpdateCdd_Impl_OnCommandTrigByImpl_OnCommand: start-on-event=CUpdateCdd_Impl_OnCommand, operation=pp_CmpLibCmd_CUpdateCdd.Impl_OnCommand
      data received event DRECUpdateCdd_OnDre_UpdateResponseTrigByUpdateShortServiceRespData: start-on-event=CUpdateCdd_OnDre_UpdateResponse, data=rp_SR_UpdateShortServiceResponse.UpdateShortServiceRespData
      6 x operation invoked event:
        OperationInvokeEvent_105: start-on-event=CUpdateCdd_UpdateCdd_GenericDIDRequestHandler, operation=pp_CS_UpdateCdd_GenericDIDRequestHandler.UpdateCdd_GenericDIDRequestHandler
        OperationInvokeEvent_106: start-on-event=CUpdateCdd_UpdateCdd_GenericProgSessionRequest, operation=pp_CS_UpdateCdd_GenericProgSessionRequest.UpdateCdd_GenericProgSessionRequest
        OperationInvokeEvent_107: start-on-event=CUpdateCdd_UpdateCdd_GenericRIDRequestHandler, operation=pp_CS_UpdateCdd_GenericRIDRequestHandler.UpdateCdd_GenericRIDRequestHandler
        OperationInvokeEvent_108: start-on-event=CUpdateCdd_UpdateCdd_GenericRequestDownloadHandler, operation=pp_CS_UpdateCdd_GenericDownloadRequestHandler.UpdateCdd_GenericRequestDownloadHandler
        OperationInvokeEvent_109: start-on-event=CUpdateCdd_UpdateCdd_GenericTransferDataHandler, operation=pp_CS_UpdateCdd_GenericTransferDataHandler.UpdateCdd_GenericTransferDataHandler
        OperationInvokeEvent_110: start-on-event=CUpdateCdd_UpdateCdd_GenericTransferExitHandler, operation=pp_CS_UpdateCdd_GenericTransferExitHandler.UpdateCdd_GenericTransferExitHandler
      port-api-options:
        enable-take-address=false, indirect-api=false, port=pp_CS_UpdateCdd_GenericDIDRequestHandler
        enable-take-address=false, indirect-api=false, port=pp_CS_UpdateCdd_GenericDownloadRequestHandler
        enable-take-address=false, indirect-api=false, port=pp_CS_UpdateCdd_GenericProgSessionRequest
        enable-take-address=false, indirect-api=false, port=pp_CS_UpdateCdd_GenericRIDRequestHandler
        enable-take-address=false, indirect-api=false, port=pp_CS_UpdateCdd_GenericTransferDataHandler
        enable-take-address=false, indirect-api=false, port=pp_CS_UpdateCdd_GenericTransferExitHandler
        enable-take-address=false, indirect-api=false, port=pp_CmpLibCmd_CUpdateCdd
        enable-take-address=false, indirect-api=false, port=pp_SR_UpdateLongServiceRequest
        enable-take-address=false, indirect-api=false, port=pp_SR_UpdateShortServiceRequest
        enable-take-address=false, indirect-api=false, port=rp_SR_UpdateShortServiceResponse
      9 x runnable, all with can-be-invoked-concurrently=true:
        CUpdateCdd_Impl_MainFunction
          data-receive-point-by-arguments:
            access DRP_rp_SR_UpdateShortServiceResponse_UpdateShortServiceRespData: accessed-variable=rp_SR_UpdateShortServiceResponse.UpdateShortServiceRespData
          data-send-points:
            access DSP_pp_SR_UpdateLongServiceRequest_UpdateLongServiceReqData: accessed-variable=pp_SR_UpdateLongServiceRequest.UpdateLongServiceReqData
            access DSP_pp_SR_UpdateShortServiceRequest_UpdateShortServiceReqData: accessed-variable=pp_SR_UpdateShortServiceRequest.UpdateShortServiceReqData
        CUpdateCdd_Impl_OnCommand
          data-receive-point-by-arguments:
            access DRP_rp_SR_UpdateShortServiceResponse_UpdateShortServiceRespData: accessed-variable=rp_SR_UpdateShortServiceResponse.UpdateShortServiceRespData
          data-send-points:
            access DSP_pp_SR_UpdateLongServiceRequest_UpdateLongServiceReqData: accessed-variable=pp_SR_UpdateLongServiceRequest.UpdateLongServiceReqData
            access DSP_pp_SR_UpdateShortServiceRequest_UpdateShortServiceReqData: accessed-variable=pp_SR_UpdateShortServiceRequest.UpdateShortServiceReqData
        CUpdateCdd_OnDre_UpdateResponse
          data-receive-point-by-arguments:
            access DRP_rp_SR_UpdateShortServiceResponse_UpdateShortServiceRespData: accessed-variable=rp_SR_UpdateShortServiceResponse.UpdateShortServiceRespData
          data-send-points:
            access DSP_pp_SR_UpdateLongServiceRequest_UpdateLongServiceReqData: accessed-variable=pp_SR_UpdateLongServiceRequest.UpdateLongServiceReqData
            access DSP_pp_SR_UpdateShortServiceRequest_UpdateShortServiceReqData: accessed-variable=pp_SR_UpdateShortServiceRequest.UpdateShortServiceReqData
        CUpdateCdd_UpdateCdd_GenericDIDRequestHandler
          data-receive-point-by-arguments:
            access DRP_rp_SR_UpdateShortServiceResponse_UpdateShortServiceRespData: accessed-variable=rp_SR_UpdateShortServiceResponse.UpdateShortServiceRespData
          data-send-points:
            access DSP_pp_SR_UpdateLongServiceRequest_UpdateLongServiceReqData: accessed-variable=pp_SR_UpdateLongServiceRequest.UpdateLongServiceReqData
            access DSP_pp_SR_UpdateShortServiceRequest_UpdateShortServiceReqData: accessed-variable=pp_SR_UpdateShortServiceRequest.UpdateShortServiceReqData
        CUpdateCdd_UpdateCdd_GenericProgSessionRequest
          data-receive-point-by-arguments:
            access DRP_rp_SR_UpdateShortServiceResponse_UpdateShortServiceRespData: accessed-variable=rp_SR_UpdateShortServiceResponse.UpdateShortServiceRespData
          data-send-points:
            access DSP_pp_SR_UpdateLongServiceRequest_UpdateLongServiceReqData: accessed-variable=pp_SR_UpdateLongServiceRequest.UpdateLongServiceReqData
            access DSP_pp_SR_UpdateShortServiceRequest_UpdateShortServiceReqData: accessed-variable=pp_SR_UpdateShortServiceRequest.UpdateShortServiceReqData
        CUpdateCdd_UpdateCdd_GenericRIDRequestHandler
          data-receive-point-by-arguments:
            access DRP_rp_SR_UpdateShortServiceResponse_UpdateShortServiceRespData: accessed-variable=rp_SR_UpdateShortServiceResponse.UpdateShortServiceRespData
          data-send-points:
            access DSP_pp_SR_UpdateLongServiceRequest_UpdateLongServiceReqData: accessed-variable=pp_SR_UpdateLongServiceRequest.UpdateLongServiceReqData
            access DSP_pp_SR_UpdateShortServiceRequest_UpdateShortServiceReqData: accessed-variable=pp_SR_UpdateShortServiceRequest.UpdateShortServiceReqData
        CUpdateCdd_UpdateCdd_GenericRequestDownloadHandler
          data-receive-point-by-arguments:
            access DRP_rp_SR_UpdateShortServiceResponse_UpdateShortServiceRespData: accessed-variable=rp_SR_UpdateShortServiceResponse.UpdateShortServiceRespData
          data-send-points:
            access DSP_pp_SR_UpdateLongServiceRequest_UpdateLongServiceReqData: accessed-variable=pp_SR_UpdateLongServiceRequest.UpdateLongServiceReqData
            access DSP_pp_SR_UpdateShortServiceRequest_UpdateShortServiceReqData: accessed-variable=pp_SR_UpdateShortServiceRequest.UpdateShortServiceReqData
        CUpdateCdd_UpdateCdd_GenericTransferDataHandler
          data-receive-point-by-arguments:
            access DRP_rp_SR_UpdateShortServiceResponse_UpdateShortServiceRespData: accessed-variable=rp_SR_UpdateShortServiceResponse.UpdateShortServiceRespData
          data-send-points:
            access DSP_pp_SR_UpdateLongServiceRequest_UpdateLongServiceReqData: accessed-variable=pp_SR_UpdateLongServiceRequest.UpdateLongServiceReqData
            access DSP_pp_SR_UpdateShortServiceRequest_UpdateShortServiceReqData: accessed-variable=pp_SR_UpdateShortServiceRequest.UpdateShortServiceReqData
        CUpdateCdd_UpdateCdd_GenericTransferExitHandler
          data-receive-point-by-arguments:
            access DRP_rp_SR_UpdateShortServiceResponse_UpdateShortServiceRespData: accessed-variable=rp_SR_UpdateShortServiceResponse.UpdateShortServiceRespData
          data-send-points:
            access DSP_pp_SR_UpdateLongServiceRequest_UpdateLongServiceReqData: accessed-variable=pp_SR_UpdateLongServiceRequest.UpdateLongServiceReqData
            access DSP_pp_SR_UpdateShortServiceRequest_UpdateShortServiceReqData: accessed-variable=pp_SR_UpdateShortServiceRequest.UpdateShortServiceReqData
  swc implementation IMPL_CUpdateCdd: programming-language=C, behavior=IB_CUpdateCdd
    code-descriptors:
      code CodeDescriptor
  application sw component type DltExt
    6 x provide port:
      pSR_DLTControlMessageReponse: nonqueued-sender-com-spec{data-element=DLTControlMessageReponseData, init-value=constant-reference=DltExtDLTControlMessageReponseDataValue0}, provided-interface=DLTControlMessageReponse
      pSR_DLTMessageReadRequest: nonqueued-sender-com-spec{data-element=DLTMessageReadRequestData, init-value=constant-reference=DltExtDLTMessageReadRequestDataValue0}, provided-interface=DLTMessageReadRequest
      ppCS_DltExt_SendLogMessage: server-com-spec{operation=If_CS_DltExt_SendLogMessage/SendLogMessage, queue-length=1}, provided-interface=If_CS_DltExt_SendLogMessage
      ppCS_SetCounterToDefault: server-com-spec{operation=SetCounterToDefault, queue-length=1}, provided-interface=If_CS_SetCounterToDefault
      ppCS_SetLogsToDefault: server-com-spec{operation=SetLogsToDefault, queue-length=1}, provided-interface=If_CS_SetLogsToDefault
      ppCs_DltExt_GetResetInfo: server-com-spec{operation=GetResetInfo, queue-length=1}, provided-interface=if_CS_DltExt_GetResetInfo
    5 x require port:
      rSR_DLTControlMessageRequest: nonqueued-receiver-com-spec{data-element=DLTControlMessageRequestData, init-value=constant-reference=DltExtDLTControlMessageRequestDataValue0}, required-interface=DLTControlMessageRequest
      rSR_DLTMessageReadAck: nonqueued-receiver-com-spec{data-element=DLTMessageReadAckData, init-value=constant-reference=DltExtDLTMessageReadAckDataValue0}, required-interface=DLTMessageReadAck
      rp_CS_MemAbsGet: required-interface=if_CS_MemAbsGet
      rp_CS_MemAbsSet: required-interface=if_CS_MemAbsSet
      rp_CS_MemAbs_NvMWriteStatus: required-interface=if_CS_MemAbs_NvMWriteStatus
    behavior IB_DltExt
      operation invoked event OIE_ppCs_DltExt_GetResetInfo_DltExt_GetResetInfoTrigByGetResetInfo: start-on-event=DltExt_GetResetInfo, operation=ppCs_DltExt_GetResetInfo.GetResetInfo
      timing event TEDltExt_MainFunction: start-on-event=DltExt_MainFunction, period=0.1
      operation invoked event OIE_ppCS_DltExt_SendLogMessage_DltExt_SendLogMessageTrigBySendLogMessage: start-on-event=DltExt_SendLogMessage, operation=ppCS_DltExt_SendLogMessage.SendLogMessage
      operation invoked event OIE_ppCS_SetCounterToDefault_DltExt_SetCounterToDefaultTrigBySetCounterToDefault: start-on-event=DltExt_SetCounterToDefault, operation=ppCS_SetCounterToDefault.SetCounterToDefault
      operation invoked event OIE_ppCS_SetLogsToDefault_DltExt_SetLogsToDefaultTrigBySetLogsToDefault: start-on-event=DltExt_SetLogsToDefault, operation=ppCS_SetLogsToDefault.SetLogsToDefault
      port-api-options:
        enable-take-address=false, indirect-api=false, port=pSR_DLTControlMessageReponse
        enable-take-address=false, indirect-api=false, port=pSR_DLTMessageReadRequest
        enable-take-address=false, indirect-api=false, port=ppCS_DltExt_SendLogMessage
        enable-take-address=false, indirect-api=false, port=ppCS_SetCounterToDefault
        enable-take-address=false, indirect-api=false, port=ppCS_SetLogsToDefault
        enable-take-address=false, indirect-api=false, port=ppCs_DltExt_GetResetInfo
        enable-take-address=false, indirect-api=false, port=rSR_DLTControlMessageRequest
        enable-take-address=false, indirect-api=false, port=rSR_DLTMessageReadAck
        enable-take-address=false, indirect-api=false, port=DltExt/rp_CS_MemAbsGet
        enable-take-address=false, indirect-api=false, port=DltExt/rp_CS_MemAbsSet
        enable-take-address=false, indirect-api=false, port=DltExt/rp_CS_MemAbs_NvMWriteStatus
      5 x runnable, all with can-be-invoked-concurrently=true:
        DltExt_GetResetInfo
        DltExt_MainFunction
          data-receive-point-by-arguments:
            access DRA_rSR_DLTControlMessageRequest_DLTControlMessageRequestData: accessed-variable=rSR_DLTControlMessageRequest.DLTControlMessageRequestData
            access DRA_rSR_DLTMessageReadAck_DLTMessageReadAckData: accessed-variable=rSR_DLTMessageReadAck.DLTMessageReadAckData
          data-send-points:
            access DWA_pSR_DLTControlMessageReponse_DLTControlMessageReponseData: accessed-variable=pSR_DLTControlMessageReponse.DLTControlMessageReponseData
            access DWA_pSR_DLTMessageReadRequest_DLTMessageReadRequestData: accessed-variable=pSR_DLTMessageReadRequest.DLTMessageReadRequestData
          189 x sync call, all with timeout=0.0:
            OA_rp_CS_MemAbsGet_Get_BsShare_SwUpdReflash_Element: operation=rp_CS_MemAbsGet.Get_BsShare_SwUpdReflash_Element
            OA_rp_CS_MemAbsGet_Get_BsShare_SwUpdFotaMode_Element: operation=rp_CS_MemAbsGet.Get_BsShare_SwUpdFotaMode_Element
            OA_rp_CS_MemAbsGet_Get_BsShare_SwUpdFotaFinPrint_Element: operation=rp_CS_MemAbsGet.Get_BsShare_SwUpdFotaFinPrint_Element
            OA_rp_CS_MemAbsGet_Get_BsShare_SwUpdFotaStatus_Element: operation=rp_CS_MemAbsGet.Get_BsShare_SwUpdFotaStatus_Element
            OA_rp_CS_MemAbsGet_Get_BsShare_SwUpdFotadecrypt_Element: operation=rp_CS_MemAbsGet.Get_BsShare_SwUpdFotadecrypt_Element
            OA_rp_CS_MemAbsGet_Get_BsShare_EcuPartNumber_Element: operation=rp_CS_MemAbsGet.Get_BsShare_EcuPartNumber_Element
            OA_rp_CS_MemAbsGet_Get_BsShare_VisteonPartNumber: operation=rp_CS_MemAbsGet.Get_BsShare_VisteonPartNumber
            OA_rp_CS_MemAbsGet_Get_BsShare_VisteonPCBPartNumber: operation=rp_CS_MemAbsGet.Get_BsShare_VisteonPCBPartNumber
            OA_rp_CS_MemAbsGet_Get_BsShare_ProductSerialNumber: operation=rp_CS_MemAbsGet.Get_BsShare_ProductSerialNumber
            OA_rp_CS_MemAbsGet_Get_BsShare_PCBSerialNumber: operation=rp_CS_MemAbsGet.Get_BsShare_PCBSerialNumber
            OA_rp_CS_MemAbsGet_Get_BsShare_SMTManufacturingDate: operation=rp_CS_MemAbsGet.Get_BsShare_SMTManufacturingDate
            OA_rp_CS_MemAbsGet_Get_BsShare_AssemblyManufacturingDate: operation=rp_CS_MemAbsGet.Get_BsShare_AssemblyManufacturingDate
            OA_rp_CS_MemAbsGet_Get_BsShare_SMTPlantNumber: operation=rp_CS_MemAbsGet.Get_BsShare_SMTPlantNumber
            OA_rp_CS_MemAbsGet_Get_BsShare_AssemblyPlantNumber: operation=rp_CS_MemAbsGet.Get_BsShare_AssemblyPlantNumber
            OA_rp_CS_MemAbsGet_Get_BsShare_HWModification: operation=rp_CS_MemAbsGet.Get_BsShare_HWModification
            OA_rp_CS_MemAbsGet_Get_BsShare_VisMeet_Element: operation=rp_CS_MemAbsGet.Get_BsShare_VisMeet_Element
            OA_rp_CS_MemAbsGet_Get_BsShare_VisMeet_EOLEntry_Element: operation=rp_CS_MemAbsGet.Get_BsShare_VisMeet_EOLEntry_Element
            OA_rp_CS_MemAbsGet_Get_BsShare_VehicleConfig_Element: operation=rp_CS_MemAbsGet.Get_BsShare_VehicleConfig_Element
            OA_rp_CS_MemAbsGet_Get_BsConst_SpeedoGauge_Element: operation=rp_CS_MemAbsGet.Get_BsConst_SpeedoGauge_Element
            OA_rp_CS_MemAbsGet_Get_BsConst_TachoGauge_Element: operation=rp_CS_MemAbsGet.Get_BsConst_TachoGauge_Element
            OA_rp_CS_MemAbsGet_Get_BsConst_FuelGauge_Element: operation=rp_CS_MemAbsGet.Get_BsConst_FuelGauge_Element
            OA_rp_CS_MemAbsGet_Get_BsConst_TempGauge_Element: operation=rp_CS_MemAbsGet.Get_BsConst_TempGauge_Element
            OA_rp_CS_MemAbsGet_Get_BsConst_PowerGauge_Element: operation=rp_CS_MemAbsGet.Get_BsConst_PowerGauge_Element
            OA_rp_CS_MemAbsGet_Get_BsConst_OilGauge_Element: operation=rp_CS_MemAbsGet.Get_BsConst_OilGauge_Element
            OA_rp_CS_MemAbsGet_Get_BsConst_TripComputer_Element: operation=rp_CS_MemAbsGet.Get_BsConst_TripComputer_Element
            OA_rp_CS_MemAbsGet_Get_BsConst_Compensation_Line_Slope_m: operation=rp_CS_MemAbsGet.Get_BsConst_Compensation_Line_Slope_m
            OA_rp_CS_MemAbsGet_Get_BsConst_Compensation_Line_Shift_b: operation=rp_CS_MemAbsGet.Get_BsConst_Compensation_Line_Shift_b
            OA_rp_CS_MemAbsGet_Get_BsConst_Lookup_Curve_HotSpot_Coef_X: operation=rp_CS_MemAbsGet.Get_BsConst_Lookup_Curve_HotSpot_Coef_X
            OA_rp_CS_MemAbsGet_Get_BsConst_Lookup_Curve_HotSpot_Coef_Y: operation=rp_CS_MemAbsGet.Get_BsConst_Lookup_Curve_HotSpot_Coef_Y
            OA_rp_CS_MemAbsGet_Get_BsConst_Temp_Threshold_Hysteresis_Derating: operation=rp_CS_MemAbsGet.Get_BsConst_Temp_Threshold_Hysteresis_Derating
            OA_rp_CS_MemAbsGet_Get_BsConst_Derating_Backlight_Disable: operation=rp_CS_MemAbsGet.Get_BsConst_Derating_Backlight_Disable
            OA_rp_CS_MemAbsGet_Get_BsConst_Temperature_Sensor_Conv: operation=rp_CS_MemAbsGet.Get_BsConst_Temperature_Sensor_Conv
            OA_rp_CS_MemAbsGet_Get_BsConst_PCB_Temperature_Sensor_Conv: operation=rp_CS_MemAbsGet.Get_BsConst_PCB_Temperature_Sensor_Conv
            OA_rp_CS_MemAbsGet_Get_BsConst_Display_Illum_Max_Level: operation=rp_CS_MemAbsGet.Get_BsConst_Display_Illum_Max_Level
            OA_rp_CS_MemAbsGet_Get_BsConst_PWM_boost_bypass_duty: operation=rp_CS_MemAbsGet.Get_BsConst_PWM_boost_bypass_duty
            OA_rp_CS_MemAbsGet_Get_BsConst_BsConst_Illumination_ReservedByte: operation=rp_CS_MemAbsGet.Get_BsConst_BsConst_Illumination_ReservedByte
            OA_rp_CS_MemAbsGet_Get_BsConst_Compensation_Line_Slope_m_SafeCopy1: operation=rp_CS_MemAbsGet.Get_BsConst_Compensation_Line_Slope_m_SafeCopy1
            OA_rp_CS_MemAbsGet_Get_BsConst_Compensation_Line_Shift_b_SafeCopy1: operation=rp_CS_MemAbsGet.Get_BsConst_Compensation_Line_Shift_b_SafeCopy1
            OA_rp_CS_MemAbsGet_Get_BsConst_Lookup_Curve_HotSpot_Coef_X_SafeCopy1: operation=rp_CS_MemAbsGet.Get_BsConst_Lookup_Curve_HotSpot_Coef_X_SafeCopy1
            OA_rp_CS_MemAbsGet_Get_BsConst_Lookup_Curve_HotSpot_Coef_Y_SafeCopy1: operation=rp_CS_MemAbsGet.Get_BsConst_Lookup_Curve_HotSpot_Coef_Y_SafeCopy1
            OA_rp_CS_MemAbsGet_Get_BsConst_Temp_Threshold_Hysteresis_Derating_SafeCopy1: operation=rp_CS_MemAbsGet.Get_BsConst_Temp_Threshold_Hysteresis_Derating_SafeCopy1
            OA_rp_CS_MemAbsGet_Get_BsConst_Derating_Backlight_Disable_SafeCopy1: operation=rp_CS_MemAbsGet.Get_BsConst_Derating_Backlight_Disable_SafeCopy1
            OA_rp_CS_MemAbsGet_Get_BsConst_Temperature_Sensor_Conv_SafeCopy1: operation=rp_CS_MemAbsGet.Get_BsConst_Temperature_Sensor_Conv_SafeCopy1
            OA_rp_CS_MemAbsGet_Get_BsConst_PCB_Temperature_Sensor_Conv_SafeCopy1: operation=rp_CS_MemAbsGet.Get_BsConst_PCB_Temperature_Sensor_Conv_SafeCopy1
            OA_rp_CS_MemAbsGet_Get_BsConst_Display_Illum_Max_Level_SafeCopy1: operation=rp_CS_MemAbsGet.Get_BsConst_Display_Illum_Max_Level_SafeCopy1
            OA_rp_CS_MemAbsGet_Get_BsConst_PWM_boost_bypass_duty_SafeCopy1: operation=rp_CS_MemAbsGet.Get_BsConst_PWM_boost_bypass_duty_SafeCopy1
            OA_rp_CS_MemAbsGet_Get_BsConst_BsConst_Illumination_ReservedByte_SafeCopy1: operation=rp_CS_MemAbsGet.Get_BsConst_BsConst_Illumination_ReservedByte_SafeCopy1
            OA_rp_CS_MemAbsGet_Get_BsConst_Compensation_Line_Slope_m_SafeCopy2: operation=rp_CS_MemAbsGet.Get_BsConst_Compensation_Line_Slope_m_SafeCopy2
            OA_rp_CS_MemAbsGet_Get_BsConst_Compensation_Line_Shift_b_SafeCopy2: operation=rp_CS_MemAbsGet.Get_BsConst_Compensation_Line_Shift_b_SafeCopy2
            OA_rp_CS_MemAbsGet_Get_BsConst_Lookup_Curve_HotSpot_Coef_X_SafeCopy2: operation=rp_CS_MemAbsGet.Get_BsConst_Lookup_Curve_HotSpot_Coef_X_SafeCopy2
            OA_rp_CS_MemAbsGet_Get_BsConst_Lookup_Curve_HotSpot_Coef_Y_SafeCopy2: operation=rp_CS_MemAbsGet.Get_BsConst_Lookup_Curve_HotSpot_Coef_Y_SafeCopy2
            OA_rp_CS_MemAbsGet_Get_BsConst_Temp_Threshold_Hysteresis_Derating_SafeCopy2: operation=rp_CS_MemAbsGet.Get_BsConst_Temp_Threshold_Hysteresis_Derating_SafeCopy2
            OA_rp_CS_MemAbsGet_Get_BsConst_Derating_Backlight_Disable_SafeCopy2: operation=rp_CS_MemAbsGet.Get_BsConst_Derating_Backlight_Disable_SafeCopy2
            OA_rp_CS_MemAbsGet_Get_BsConst_Temperature_Sensor_Conv_SafeCopy2: operation=rp_CS_MemAbsGet.Get_BsConst_Temperature_Sensor_Conv_SafeCopy2
            OA_rp_CS_MemAbsGet_Get_BsConst_PCB_Temperature_Sensor_Conv_SafeCopy2: operation=rp_CS_MemAbsGet.Get_BsConst_PCB_Temperature_Sensor_Conv_SafeCopy2
            OA_rp_CS_MemAbsGet_Get_BsConst_Display_Illum_Max_Level_SafeCopy2: operation=rp_CS_MemAbsGet.Get_BsConst_Display_Illum_Max_Level_SafeCopy2
            OA_rp_CS_MemAbsGet_Get_BsConst_PWM_boost_bypass_duty_SafeCopy2: operation=rp_CS_MemAbsGet.Get_BsConst_PWM_boost_bypass_duty_SafeCopy2
            OA_rp_CS_MemAbsGet_Get_BsConst_BsConst_Illumination_ReservedByte_SafeCopy2: operation=rp_CS_MemAbsGet.Get_BsConst_BsConst_Illumination_ReservedByte_SafeCopy2
            OA_rp_CS_MemAbsGet_Get_BsConst_Audio_Element: operation=rp_CS_MemAbsGet.Get_BsConst_Audio_Element
            OA_rp_CS_MemAbsGet_Get_BsConst_Warning_Element: operation=rp_CS_MemAbsGet.Get_BsConst_Warning_Element
            OA_rp_CS_MemAbsGet_Get_BsConst_RealTimeClock_Element: operation=rp_CS_MemAbsGet.Get_BsConst_RealTimeClock_Element
            OA_rp_CS_MemAbsGet_Get_BsConst_Communication_Element: operation=rp_CS_MemAbsGet.Get_BsConst_Communication_Element
            OA_rp_CS_MemAbsGet_Get_BsConst_Power_Element: operation=rp_CS_MemAbsGet.Get_BsConst_Power_Element
            OA_rp_CS_MemAbsGet_Get_BsConst_ServiceReminder_Element: operation=rp_CS_MemAbsGet.Get_BsConst_ServiceReminder_Element
            OA_rp_CS_MemAbsGet_Get_BsConst_EngOffTimer_Element: operation=rp_CS_MemAbsGet.Get_BsConst_EngOffTimer_Element
            OA_rp_CS_MemAbsGet_Get_BsCys_Certicificate_Element: operation=rp_CS_MemAbsGet.Get_BsCys_Certicificate_Element
            OA_rp_CS_MemAbsGet_Get_RefCys_Certicificate_Element: operation=rp_CS_MemAbsGet.Get_RefCys_Certicificate_Element
            OA_rp_CS_MemAbsGet_Get_RefCys_Certicificate1_Element: operation=rp_CS_MemAbsGet.Get_RefCys_Certicificate1_Element
            OA_rp_CS_MemAbsGet_Get_BsRt_Odometer_Element: operation=rp_CS_MemAbsGet.Get_BsRt_Odometer_Element
            OA_rp_CS_MemAbsGet_Get_BsRt_SpeedoGauge_Element: operation=rp_CS_MemAbsGet.Get_BsRt_SpeedoGauge_Element
            OA_rp_CS_MemAbsGet_Get_BsRt_TachoGauge_Element: operation=rp_CS_MemAbsGet.Get_BsRt_TachoGauge_Element
            OA_rp_CS_MemAbsGet_Get_BsRt_FuelGauge_Element: operation=rp_CS_MemAbsGet.Get_BsRt_FuelGauge_Element
            OA_rp_CS_MemAbsGet_Get_BsRt_TempGauge_Element: operation=rp_CS_MemAbsGet.Get_BsRt_TempGauge_Element
            OA_rp_CS_MemAbsGet_Get_BsRt_PowerGauge_Element: operation=rp_CS_MemAbsGet.Get_BsRt_PowerGauge_Element
            OA_rp_CS_MemAbsGet_Get_BsRt_OilGauge_Element: operation=rp_CS_MemAbsGet.Get_BsRt_OilGauge_Element
            OA_rp_CS_MemAbsGet_Get_BsRt_TripComputer_Element: operation=rp_CS_MemAbsGet.Get_BsRt_TripComputer_Element
            OA_rp_CS_MemAbsGet_Get_BsRt_Warning_Element: operation=rp_CS_MemAbsGet.Get_BsRt_Warning_Element
            OA_rp_CS_MemAbsGet_Get_BsRt_RealTimeClock_Element: operation=rp_CS_MemAbsGet.Get_BsRt_RealTimeClock_Element
            OA_rp_CS_MemAbsGet_Get_BsRt_Personalization_Element: operation=rp_CS_MemAbsGet.Get_BsRt_Personalization_Element
            OA_rp_CS_MemAbsGet_Get_BsRt_Illumination_Element: operation=rp_CS_MemAbsGet.Get_BsRt_Illumination_Element
            OA_rp_CS_MemAbsGet_Get_BsRt_CusDlt_Element: operation=rp_CS_MemAbsGet.Get_BsRt_CusDlt_Element
            OA_rp_CS_MemAbsGet_Get_BsReten_Odometer_Element: operation=rp_CS_MemAbsGet.Get_BsReten_Odometer_Element
            OA_rp_CS_MemAbsGet_Get_BsReten_Gauges_Element: operation=rp_CS_MemAbsGet.Get_BsReten_Gauges_Element
            OA_rp_CS_MemAbsGet_Get_BsReten_Tripcomputer_Element: operation=rp_CS_MemAbsGet.Get_BsReten_Tripcomputer_Element
            OA_rp_CS_MemAbsGet_Get_BsReten_Illumination_Element: operation=rp_CS_MemAbsGet.Get_BsReten_Illumination_Element
            OA_rp_CS_MemAbsGet_Get_BsReten_Audio_Element: operation=rp_CS_MemAbsGet.Get_BsReten_Audio_Element
            OA_rp_CS_MemAbsGet_Get_BsReten_Warning_Element: operation=rp_CS_MemAbsGet.Get_BsReten_Warning_Element
            OA_rp_CS_MemAbsGet_Get_BsReten_RealTimeClock_Element: operation=rp_CS_MemAbsGet.Get_BsReten_RealTimeClock_Element
            OA_rp_CS_MemAbsGet_Get_BsReten_Communication_Element: operation=rp_CS_MemAbsGet.Get_BsReten_Communication_Element
            OA_rp_CS_MemAbsGet_Get_BsReten_Personalization_Element: operation=rp_CS_MemAbsGet.Get_BsReten_Personalization_Element
            OA_rp_CS_MemAbsGet_Get_BsReten_Power_Element: operation=rp_CS_MemAbsGet.Get_BsReten_Power_Element
            OA_rp_CS_MemAbsGet_Get_BsReten_Display_Element: operation=rp_CS_MemAbsGet.Get_BsReten_Display_Element
            OA_rp_CS_MemAbsGet_Get_BsDiag_ErrorRecord_Element: operation=rp_CS_MemAbsGet.Get_BsDiag_ErrorRecord_Element
            OA_rp_CS_MemAbsGet_Get_BsDiag_Dtc_Element: operation=rp_CS_MemAbsGet.Get_BsDiag_Dtc_Element
            OA_rp_CS_MemAbsSet_Set_BsShare_SwUpdReflash_Element: operation=rp_CS_MemAbsSet.Set_BsShare_SwUpdReflash_Element
            OA_rp_CS_MemAbsSet_Set_BsShare_SwUpdFotaMode_Element: operation=rp_CS_MemAbsSet.Set_BsShare_SwUpdFotaMode_Element
            OA_rp_CS_MemAbsSet_Set_BsShare_SwUpdFotaFinPrint_Element: operation=rp_CS_MemAbsSet.Set_BsShare_SwUpdFotaFinPrint_Element
            OA_rp_CS_MemAbsSet_Set_BsShare_SwUpdFotaStatus_Element: operation=rp_CS_MemAbsSet.Set_BsShare_SwUpdFotaStatus_Element
            OA_rp_CS_MemAbsSet_Set_BsShare_SwUpdFotadecrypt_Element: operation=rp_CS_MemAbsSet.Set_BsShare_SwUpdFotadecrypt_Element
            OA_rp_CS_MemAbsSet_Set_BsShare_EcuPartNumber_Element: operation=rp_CS_MemAbsSet.Set_BsShare_EcuPartNumber_Element
            OA_rp_CS_MemAbsSet_Set_BsShare_VisteonPartNumber: operation=rp_CS_MemAbsSet.Set_BsShare_VisteonPartNumber
            OA_rp_CS_MemAbsSet_Set_BsShare_VisteonPCBPartNumber: operation=rp_CS_MemAbsSet.Set_BsShare_VisteonPCBPartNumber
            OA_rp_CS_MemAbsSet_Set_BsShare_ProductSerialNumber: operation=rp_CS_MemAbsSet.Set_BsShare_ProductSerialNumber
            OA_rp_CS_MemAbsSet_Set_BsShare_PCBSerialNumber: operation=rp_CS_MemAbsSet.Set_BsShare_PCBSerialNumber
            OA_rp_CS_MemAbsSet_Set_BsShare_SMTManufacturingDate: operation=rp_CS_MemAbsSet.Set_BsShare_SMTManufacturingDate
            OA_rp_CS_MemAbsSet_Set_BsShare_AssemblyManufacturingDate: operation=rp_CS_MemAbsSet.Set_BsShare_AssemblyManufacturingDate
            OA_rp_CS_MemAbsSet_Set_BsShare_SMTPlantNumber: operation=rp_CS_MemAbsSet.Set_BsShare_SMTPlantNumber
            OA_rp_CS_MemAbsSet_Set_BsShare_AssemblyPlantNumber: operation=rp_CS_MemAbsSet.Set_BsShare_AssemblyPlantNumber
            OA_rp_CS_MemAbsSet_Set_BsShare_HWModification: operation=rp_CS_MemAbsSet.Set_BsShare_HWModification
            OA_rp_CS_MemAbsSet_Set_BsShare_VisMeet_Element: operation=rp_CS_MemAbsSet.Set_BsShare_VisMeet_Element
            OA_rp_CS_MemAbsSet_Set_BsShare_VisMeet_EOLEntry_Element: operation=rp_CS_MemAbsSet.Set_BsShare_VisMeet_EOLEntry_Element
            OA_rp_CS_MemAbsSet_Set_BsShare_VehicleConfig_Element: operation=rp_CS_MemAbsSet.Set_BsShare_VehicleConfig_Element
            OA_rp_CS_MemAbsSet_Set_BsConst_SpeedoGauge_Element: operation=rp_CS_MemAbsSet.Set_BsConst_SpeedoGauge_Element
            OA_rp_CS_MemAbsSet_Set_BsConst_TachoGauge_Element: operation=rp_CS_MemAbsSet.Set_BsConst_TachoGauge_Element
            OA_rp_CS_MemAbsSet_Set_BsConst_FuelGauge_Element: operation=rp_CS_MemAbsSet.Set_BsConst_FuelGauge_Element
            OA_rp_CS_MemAbsSet_Set_BsConst_TempGauge_Element: operation=rp_CS_MemAbsSet.Set_BsConst_TempGauge_Element
            OA_rp_CS_MemAbsSet_Set_BsConst_PowerGauge_Element: operation=rp_CS_MemAbsSet.Set_BsConst_PowerGauge_Element
            OA_rp_CS_MemAbsSet_Set_BsConst_OilGauge_Element: operation=rp_CS_MemAbsSet.Set_BsConst_OilGauge_Element
            OA_rp_CS_MemAbsSet_Set_BsConst_TripComputer_Element: operation=rp_CS_MemAbsSet.Set_BsConst_TripComputer_Element
            OA_rp_CS_MemAbsSet_Set_BsConst_Compensation_Line_Slope_m: operation=rp_CS_MemAbsSet.Set_BsConst_Compensation_Line_Slope_m
            OA_rp_CS_MemAbsSet_Set_BsConst_Compensation_Line_Shift_b: operation=rp_CS_MemAbsSet.Set_BsConst_Compensation_Line_Shift_b
            OA_rp_CS_MemAbsSet_Set_BsConst_Lookup_Curve_HotSpot_Coef_X: operation=rp_CS_MemAbsSet.Set_BsConst_Lookup_Curve_HotSpot_Coef_X
            OA_rp_CS_MemAbsSet_Set_BsConst_Lookup_Curve_HotSpot_Coef_Y: operation=rp_CS_MemAbsSet.Set_BsConst_Lookup_Curve_HotSpot_Coef_Y
            OA_rp_CS_MemAbsSet_Set_BsConst_Temp_Threshold_Hysteresis_Derating: operation=rp_CS_MemAbsSet.Set_BsConst_Temp_Threshold_Hysteresis_Derating
            OA_rp_CS_MemAbsSet_Set_BsConst_Derating_Backlight_Disable: operation=rp_CS_MemAbsSet.Set_BsConst_Derating_Backlight_Disable
            OA_rp_CS_MemAbsSet_Set_BsConst_Temperature_Sensor_Conv: operation=rp_CS_MemAbsSet.Set_BsConst_Temperature_Sensor_Conv
            OA_rp_CS_MemAbsSet_Set_BsConst_PCB_Temperature_Sensor_Conv: operation=rp_CS_MemAbsSet.Set_BsConst_PCB_Temperature_Sensor_Conv
            OA_rp_CS_MemAbsSet_Set_BsConst_Display_Illum_Max_Level: operation=rp_CS_MemAbsSet.Set_BsConst_Display_Illum_Max_Level
            OA_rp_CS_MemAbsSet_Set_BsConst_PWM_boost_bypass_duty: operation=rp_CS_MemAbsSet.Set_BsConst_PWM_boost_bypass_duty
            OA_rp_CS_MemAbsSet_Set_BsConst_BsConst_Illumination_ReservedByte: operation=rp_CS_MemAbsSet.Set_BsConst_BsConst_Illumination_ReservedByte
            OA_rp_CS_MemAbsSet_Set_BsConst_Compensation_Line_Slope_m_SafeCopy1: operation=rp_CS_MemAbsSet.Set_BsConst_Compensation_Line_Slope_m_SafeCopy1
            OA_rp_CS_MemAbsSet_Set_BsConst_Compensation_Line_Shift_b_SafeCopy1: operation=rp_CS_MemAbsSet.Set_BsConst_Compensation_Line_Shift_b_SafeCopy1
            OA_rp_CS_MemAbsSet_Set_BsConst_Lookup_Curve_HotSpot_Coef_X_SafeCopy1: operation=rp_CS_MemAbsSet.Set_BsConst_Lookup_Curve_HotSpot_Coef_X_SafeCopy1
            OA_rp_CS_MemAbsSet_Set_BsConst_Lookup_Curve_HotSpot_Coef_Y_SafeCopy1: operation=rp_CS_MemAbsSet.Set_BsConst_Lookup_Curve_HotSpot_Coef_Y_SafeCopy1
            OA_rp_CS_MemAbsSet_Set_BsConst_Temp_Threshold_Hysteresis_Derating_SafeCopy1: operation=rp_CS_MemAbsSet.Set_BsConst_Temp_Threshold_Hysteresis_Derating_SafeCopy1
            OA_rp_CS_MemAbsSet_Set_BsConst_Derating_Backlight_Disable_SafeCopy1: operation=rp_CS_MemAbsSet.Set_BsConst_Derating_Backlight_Disable_SafeCopy1
            OA_rp_CS_MemAbsSet_Set_BsConst_Temperature_Sensor_Conv_SafeCopy1: operation=rp_CS_MemAbsSet.Set_BsConst_Temperature_Sensor_Conv_SafeCopy1
            OA_rp_CS_MemAbsSet_Set_BsConst_PCB_Temperature_Sensor_Conv_SafeCopy1: operation=rp_CS_MemAbsSet.Set_BsConst_PCB_Temperature_Sensor_Conv_SafeCopy1
            OA_rp_CS_MemAbsSet_Set_BsConst_Display_Illum_Max_Level_SafeCopy1: operation=rp_CS_MemAbsSet.Set_BsConst_Display_Illum_Max_Level_SafeCopy1
            OA_rp_CS_MemAbsSet_Set_BsConst_PWM_boost_bypass_duty_SafeCopy1: operation=rp_CS_MemAbsSet.Set_BsConst_PWM_boost_bypass_duty_SafeCopy1
            OA_rp_CS_MemAbsSet_Set_BsConst_BsConst_Illumination_ReservedByte_SafeCopy1: operation=rp_CS_MemAbsSet.Set_BsConst_BsConst_Illumination_ReservedByte_SafeCopy1
            OA_rp_CS_MemAbsSet_Set_BsConst_Compensation_Line_Slope_m_SafeCopy2: operation=rp_CS_MemAbsSet.Set_BsConst_Compensation_Line_Slope_m_SafeCopy2
            OA_rp_CS_MemAbsSet_Set_BsConst_Compensation_Line_Shift_b_SafeCopy2: operation=rp_CS_MemAbsSet.Set_BsConst_Compensation_Line_Shift_b_SafeCopy2
            OA_rp_CS_MemAbsSet_Set_BsConst_Lookup_Curve_HotSpot_Coef_X_SafeCopy2: operation=rp_CS_MemAbsSet.Set_BsConst_Lookup_Curve_HotSpot_Coef_X_SafeCopy2
            OA_rp_CS_MemAbsSet_Set_BsConst_Lookup_Curve_HotSpot_Coef_Y_SafeCopy2: operation=rp_CS_MemAbsSet.Set_BsConst_Lookup_Curve_HotSpot_Coef_Y_SafeCopy2
            OA_rp_CS_MemAbsSet_Set_BsConst_Temp_Threshold_Hysteresis_Derating_SafeCopy2: operation=rp_CS_MemAbsSet.Set_BsConst_Temp_Threshold_Hysteresis_Derating_SafeCopy2
            OA_rp_CS_MemAbsSet_Set_BsConst_Derating_Backlight_Disable_SafeCopy2: operation=rp_CS_MemAbsSet.Set_BsConst_Derating_Backlight_Disable_SafeCopy2
            OA_rp_CS_MemAbsSet_Set_BsConst_Temperature_Sensor_Conv_SafeCopy2: operation=rp_CS_MemAbsSet.Set_BsConst_Temperature_Sensor_Conv_SafeCopy2
            OA_rp_CS_MemAbsSet_Set_BsConst_PCB_Temperature_Sensor_Conv_SafeCopy2: operation=rp_CS_MemAbsSet.Set_BsConst_PCB_Temperature_Sensor_Conv_SafeCopy2
            OA_rp_CS_MemAbsSet_Set_BsConst_Display_Illum_Max_Level_SafeCopy2: operation=rp_CS_MemAbsSet.Set_BsConst_Display_Illum_Max_Level_SafeCopy2
            OA_rp_CS_MemAbsSet_Set_BsConst_PWM_boost_bypass_duty_SafeCopy2: operation=rp_CS_MemAbsSet.Set_BsConst_PWM_boost_bypass_duty_SafeCopy2
            OA_rp_CS_MemAbsSet_Set_BsConst_BsConst_Illumination_ReservedByte_SafeCopy2: operation=rp_CS_MemAbsSet.Set_BsConst_BsConst_Illumination_ReservedByte_SafeCopy2
            OA_rp_CS_MemAbsSet_Set_BsConst_Audio_Element: operation=rp_CS_MemAbsSet.Set_BsConst_Audio_Element
            OA_rp_CS_MemAbsSet_Set_BsConst_Warning_Element: operation=rp_CS_MemAbsSet.Set_BsConst_Warning_Element
            OA_rp_CS_MemAbsSet_Set_BsConst_RealTimeClock_Element: operation=rp_CS_MemAbsSet.Set_BsConst_RealTimeClock_Element
            OA_rp_CS_MemAbsSet_Set_BsConst_Communication_Element: operation=rp_CS_MemAbsSet.Set_BsConst_Communication_Element
            OA_rp_CS_MemAbsSet_Set_BsConst_Power_Element: operation=rp_CS_MemAbsSet.Set_BsConst_Power_Element
            OA_rp_CS_MemAbsSet_Set_BsConst_ServiceReminder_Element: operation=rp_CS_MemAbsSet.Set_BsConst_ServiceReminder_Element
            OA_rp_CS_MemAbsSet_Set_BsConst_EngOffTimer_Element: operation=rp_CS_MemAbsSet.Set_BsConst_EngOffTimer_Element
            OA_rp_CS_MemAbsSet_Set_BsCys_Certicificate_Element: operation=rp_CS_MemAbsSet.Set_BsCys_Certicificate_Element
            OA_rp_CS_MemAbsSet_Set_RefCys_Certicificate_Element: operation=rp_CS_MemAbsSet.Set_RefCys_Certicificate_Element
            OA_rp_CS_MemAbsSet_Set_RefCys_Certicificate1_Element: operation=rp_CS_MemAbsSet.Set_RefCys_Certicificate1_Element
            OA_rp_CS_MemAbsSet_Set_BsRt_Odometer_Element: operation=rp_CS_MemAbsSet.Set_BsRt_Odometer_Element
            OA_rp_CS_MemAbsSet_Set_BsRt_SpeedoGauge_Element: operation=rp_CS_MemAbsSet.Set_BsRt_SpeedoGauge_Element
            OA_rp_CS_MemAbsSet_Set_BsRt_TachoGauge_Element: operation=rp_CS_MemAbsSet.Set_BsRt_TachoGauge_Element
            OA_rp_CS_MemAbsSet_Set_BsRt_FuelGauge_Element: operation=rp_CS_MemAbsSet.Set_BsRt_FuelGauge_Element
            OA_rp_CS_MemAbsSet_Set_BsRt_TempGauge_Element: operation=rp_CS_MemAbsSet.Set_BsRt_TempGauge_Element
            OA_rp_CS_MemAbsSet_Set_BsRt_PowerGauge_Element: operation=rp_CS_MemAbsSet.Set_BsRt_PowerGauge_Element
            OA_rp_CS_MemAbsSet_Set_BsRt_OilGauge_Element: operation=rp_CS_MemAbsSet.Set_BsRt_OilGauge_Element
            OA_rp_CS_MemAbsSet_Set_BsRt_TripComputer_Element: operation=rp_CS_MemAbsSet.Set_BsRt_TripComputer_Element
            OA_rp_CS_MemAbsSet_Set_BsRt_Warning_Element: operation=rp_CS_MemAbsSet.Set_BsRt_Warning_Element
            OA_rp_CS_MemAbsSet_Set_BsRt_RealTimeClock_Element: operation=rp_CS_MemAbsSet.Set_BsRt_RealTimeClock_Element
            OA_rp_CS_MemAbsSet_Set_BsRt_Personalization_Element: operation=rp_CS_MemAbsSet.Set_BsRt_Personalization_Element
            OA_rp_CS_MemAbsSet_Set_BsRt_Illumination_Element: operation=rp_CS_MemAbsSet.Set_BsRt_Illumination_Element
            OA_rp_CS_MemAbsSet_Set_BsRt_CusDlt_Element: operation=rp_CS_MemAbsSet.Set_BsRt_CusDlt_Element
            OA_rp_CS_MemAbsSet_Set_BsReten_Odometer_Element: operation=rp_CS_MemAbsSet.Set_BsReten_Odometer_Element
            OA_rp_CS_MemAbsSet_Set_BsReten_Gauges_Element: operation=rp_CS_MemAbsSet.Set_BsReten_Gauges_Element
            OA_rp_CS_MemAbsSet_Set_BsReten_Tripcomputer_Element: operation=rp_CS_MemAbsSet.Set_BsReten_Tripcomputer_Element
            OA_rp_CS_MemAbsSet_Set_BsReten_Illumination_Element: operation=rp_CS_MemAbsSet.Set_BsReten_Illumination_Element
            OA_rp_CS_MemAbsSet_Set_BsReten_Audio_Element: operation=rp_CS_MemAbsSet.Set_BsReten_Audio_Element
            OA_rp_CS_MemAbsSet_Set_BsReten_Warning_Element: operation=rp_CS_MemAbsSet.Set_BsReten_Warning_Element
            OA_rp_CS_MemAbsSet_Set_BsReten_RealTimeClock_Element: operation=rp_CS_MemAbsSet.Set_BsReten_RealTimeClock_Element
            OA_rp_CS_MemAbsSet_Set_BsReten_Communication_Element: operation=rp_CS_MemAbsSet.Set_BsReten_Communication_Element
            OA_rp_CS_MemAbsSet_Set_BsReten_Personalization_Element: operation=rp_CS_MemAbsSet.Set_BsReten_Personalization_Element
            OA_rp_CS_MemAbsSet_Set_BsReten_Power_Element: operation=rp_CS_MemAbsSet.Set_BsReten_Power_Element
            OA_rp_CS_MemAbsSet_Set_BsReten_Display_Element: operation=rp_CS_MemAbsSet.Set_BsReten_Display_Element
            OA_rp_CS_MemAbsSet_Set_BsDiag_ErrorRecord_Element: operation=rp_CS_MemAbsSet.Set_BsDiag_ErrorRecord_Element
            OA_rp_CS_MemAbsSet_Set_BsDiag_Dtc_Element: operation=rp_CS_MemAbsSet.Set_BsDiag_Dtc_Element
            OA_rp_CS_MemAbs_NvMWriteStatus_NvmWriteStatus: operation=rp_CS_MemAbs_NvMWriteStatus.NvmWriteStatus
        DltExt_SendLogMessage
        DltExt_SetCounterToDefault
        DltExt_SetLogsToDefault
  4 x constant specification:
    DltExtDLTControlMessageReponseDataValue0: value-spec={short-label=DltExtDLTControlMessageReponseDataValue0, fields=DltExtDLTControlMessageReponseDataValue_0:0}
    DltExtDLTMessageReadRequestDataValue0: value-spec={short-label=DltExtDLTMessageReadRequestDataValue0, fields=DltExtDLTMessageReadRequestDataValue_0:0}
    DltExtDLTControlMessageRequestDataValue0: value-spec={short-label=DltExtDLTControlMessageRequestDataValue0, fields=DltExtDLTControlMessageRequestDataValue_0:0}
    DltExtDLTMessageReadAckDataValue0: value-spec={short-label=DltExtDLTMessageReadAckDataValue0, fields=DltExtDLTMessageReadAckDataValue_0:0}
  swc implementation IMPL_DltExt: programming-language=C, behavior=IB_DltExt
    code-descriptors:
      code CodeDescriptor
  application sw component type Mdl_wAirbag
    provide port pp_Init: server-com-spec{operation=TI_EcumExtInit/Init, queue-length=1}, provided-interface=TI_EcumExtInit
    5 x require port:
      rpIgnSubstate: nonqueued-receiver-com-spec{data-element=IgnitionSubstate, init-value=constant-reference=Mdl_wAirbagIgnitionSubstateValue0}, required-interface=TI_WSS_IgnitionSubstate
      rpUpdateAirbagWarning: required-interface=TI_Ctrl_Warning_UpdateWarningStatus
      rp_CS_CanAdapterSafeRx: required-interface=if_CS_ComAbsRxSafe
      rp_ClusterMode: nonqueued-receiver-com-spec{data-element=WSSCurrentClusterMode, init-value=constant-reference=Mdl_wAirbagWSSCurrentClusterModeValue0}, required-interface=TI_WSS_ClusterMode
      rp_Vehiclestate: nonqueued-receiver-com-spec{data-element=WSSCurrentVehicleState, init-value=constant-reference=Mdl_wAirbagWSSCurrentVehicleStateValue0}, required-interface=TI_WSS_VehAppMode
    behavior IB_Mdl_wAirbag
      operation invoked event OIE_pp_Init_Mdl_wAirbag_InitTrigByInit: start-on-event=Mdl_wAirbag_Init, operation=pp_Init.Init
      timing event TEMdl_wAirbag_Task: start-on-event=Mdl_wAirbag_Task, period=0.032
      port-api-options:
        enable-take-address=false, indirect-api=false, port=Mdl_wAirbag/pp_Init
        enable-take-address=false, indirect-api=false, port=Mdl_wAirbag/rpIgnSubstate
        enable-take-address=false, indirect-api=false, port=rpUpdateAirbagWarning
        enable-take-address=false, indirect-api=false, port=rp_CS_CanAdapterSafeRx
        enable-take-address=false, indirect-api=false, port=Mdl_wAirbag/rp_ClusterMode
        enable-take-address=false, indirect-api=false, port=rp_Vehiclestate
      runnable Mdl_wAirbag_Init: can-be-invoked-concurrently=true
      runnable Mdl_wAirbag_Task: can-be-invoked-concurrently=true
        data-receive-point-by-arguments:
          access DRA_rpIgnSubstate_IgnitionSubstate: accessed-variable=rpIgnSubstate.IgnitionSubstate
          access DRA_rp_ClusterMode_WSSCurrentClusterMode: accessed-variable=rp_ClusterMode.WSSCurrentClusterMode
          access DRA_rp_Vehiclestate_WSSCurrentVehicleState: accessed-variable=rp_Vehiclestate.WSSCurrentVehicleState
        10 x sync call, all with timeout=0.0:
          OA_rpUpdateAirbagWarning_UpdateWarningStatus: operation=rpUpdateAirbagWarning.UpdateWarningStatus
          OA_rp_CS_CanAdapterSafeRx_RxCan_GetSignalValueU8Arr: operation=rp_CS_CanAdapterSafeRx.RxCan_GetSignalValueU8Arr
          OA_rp_CS_CanAdapterSafeRx_RxCan_SetSignalInitValue: operation=rp_CS_CanAdapterSafeRx.RxCan_SetSignalInitValue
          OA_rp_CS_CanAdapterSafeRx_RxCan_SetSignalInitValueU8Arr: operation=rp_CS_CanAdapterSafeRx.RxCan_SetSignalInitValueU8Arr
          OA_rp_CS_CanAdapterSafeRx_RxCan_SignalInvalidProcessingControl: operation=rp_CS_CanAdapterSafeRx.RxCan_SignalInvalidProcessingControl
          OA_rp_CS_CanAdapterSafeRx_RxCan_SignalMissingProcessingControl: operation=rp_CS_CanAdapterSafeRx.RxCan_SignalMissingProcessingControl
          OA_rp_CS_CanAdapterSafeRx_RxCan_SignalNRProcessingControl: operation=rp_CS_CanAdapterSafeRx.RxCan_SignalNRProcessingControl
          OA_rp_CS_CanAdapterSafeRx_RxCan_SignalGetJustRcvdStatus: operation=rp_CS_CanAdapterSafeRx.RxCan_SignalGetJustRcvdStatus
          OA_rp_CS_CanAdapterSafeRx_RxCan_SignalClearJustRcvdStatus: operation=rp_CS_CanAdapterSafeRx.RxCan_SignalClearJustRcvdStatus
          OA_rp_CS_CanAdapterSafeRx_RxCan_GetSignalValue: operation=rp_CS_CanAdapterSafeRx.RxCan_GetSignalValue
  constant specification Mdl_wAirbagIgnitionSubstateValue0: value-spec=Mdl_wAirbagIgnitionSubstateValue0:0
  constant specification Mdl_wAirbagWSSCurrentClusterModeValue0: value-spec=Mdl_wAirbagWSSCurrentClusterModeValue0:0
  constant specification Mdl_wAirbagWSSCurrentVehicleStateValue0: value-spec=Mdl_wAirbagWSSCurrentVehicleStateValue0:0
  swc implementation IMPL_Mdl_wAirbag: programming-language=C, behavior=IB_Mdl_wAirbag
    code-descriptors:
      code CodeDescriptor
  application sw component type Mdl_wFuelLidOpen
    provide port pp_Init: server-com-spec{operation=TI_EcumExtInit/Init, queue-length=1}, provided-interface=TI_EcumExtInit
    4 x require port:
      rpIgnSubstate: nonqueued-receiver-com-spec{data-element=IgnitionSubstate, init-value=constant-reference=Mdl_wFuelLidOpenIgnitionSubstateValue0}, required-interface=TI_WSS_IgnitionSubstate
      rpUpdateFuelLidOpenWarning: required-interface=TI_Ctrl_Warning_UpdateWarningStatus
      rp_CS_RxCanAdapterMdl: required-interface=if_CS_ComAbsRx
      rp_ClusterMode: nonqueued-receiver-com-spec{data-element=WSSCurrentClusterMode, init-value=constant-reference=Mdl_wFuelLidOpenWSSCurrentClusterModeValue0}, required-interface=TI_WSS_ClusterMode
    behavior IB_Mdl_wFuelLidOpen
      operation invoked event OIE_pp_Init_Mdl_wFuelLidOpen_InitTrigByInit: start-on-event=Mdl_wFuelLidOpen_Init, operation=pp_Init.Init
      timing event TEMdl_wFuelLidOpen_Task: start-on-event=Mdl_wFuelLidOpen_Task, period=0.032
      port-api-options:
        enable-take-address=false, indirect-api=false, port=Mdl_wFuelLidOpen/pp_Init
        enable-take-address=false, indirect-api=false, port=Mdl_wFuelLidOpen/rpIgnSubstate
        enable-take-address=false, indirect-api=false, port=rpUpdateFuelLidOpenWarning
        enable-take-address=false, indirect-api=false, port=rp_CS_RxCanAdapterMdl
        enable-take-address=false, indirect-api=false, port=Mdl_wFuelLidOpen/rp_ClusterMode
      runnable Mdl_wFuelLidOpen_Init: can-be-invoked-concurrently=true
      runnable Mdl_wFuelLidOpen_Task: can-be-invoked-concurrently=true
        data-receive-point-by-arguments:
          access DRA_rpIgnSubstate_IgnitionSubstate: accessed-variable=rpIgnSubstate.IgnitionSubstate
          access DRA_rp_ClusterMode_WSSCurrentClusterMode: accessed-variable=rp_ClusterMode.WSSCurrentClusterMode
        10 x sync call, all with timeout=0.0:
          OA_rpUpdateFuelLidOpenWarning_UpdateWarningStatus: operation=rpUpdateFuelLidOpenWarning.UpdateWarningStatus
          OA_rp_CS_RxCanAdapterMdl_RxCan_GetSignalValueU8Arr: operation=rp_CS_RxCanAdapterMdl.RxCan_GetSignalValueU8Arr
          OA_rp_CS_RxCanAdapterMdl_RxCan_SetSignalInitValue: operation=rp_CS_RxCanAdapterMdl.RxCan_SetSignalInitValue
          OA_rp_CS_RxCanAdapterMdl_RxCan_SetSignalInitValueU8Arr: operation=rp_CS_RxCanAdapterMdl.RxCan_SetSignalInitValueU8Arr
          OA_rp_CS_RxCanAdapterMdl_RxCan_SignalInvalidProcessingControl: operation=rp_CS_RxCanAdapterMdl.RxCan_SignalInvalidProcessingControl
          OA_rp_CS_RxCanAdapterMdl_RxCan_SignalMissingProcessingControl: operation=rp_CS_RxCanAdapterMdl.RxCan_SignalMissingProcessingControl
          OA_rp_CS_RxCanAdapterMdl_RxCan_SignalNRProcessingControl: operation=rp_CS_RxCanAdapterMdl.RxCan_SignalNRProcessingControl
          OA_rp_CS_RxCanAdapterMdl_RxCan_SignalGetJustRcvdStatus: operation=rp_CS_RxCanAdapterMdl.RxCan_SignalGetJustRcvdStatus
          OA_rp_CS_RxCanAdapterMdl_RxCan_SignalClearJustRcvdStatus: operation=rp_CS_RxCanAdapterMdl.RxCan_SignalClearJustRcvdStatus
          OA_rp_CS_RxCanAdapterMdl_RxCan_GetSignalValue: operation=rp_CS_RxCanAdapterMdl.RxCan_GetSignalValue
  constant specification Mdl_wFuelLidOpenIgnitionSubstateValue0: value-spec=Mdl_wFuelLidOpenIgnitionSubstateValue0:0
  constant specification Mdl_wFuelLidOpenWSSCurrentClusterModeValue0: value-spec=Mdl_wFuelLidOpenWSSCurrentClusterModeValue0:0
  swc implementation IMPL_Mdl_wFuelLidOpen: programming-language=C, behavior=IB_Mdl_wFuelLidOpen
    code-descriptors:
      code CodeDescriptor
  application sw component type WarnMsg_Core_TmrSupport
    provide port pp_Init: server-com-spec{operation=TI_EcumExtInit/Init, queue-length=1}, provided-interface=TI_EcumExtInit
    4 x require port:
      rp_CS_TmExt_Timer_Elapsed: required-interface=TI_If_TmExt_Timer_IsElapsed
      rp_CS_TmExt_Timer_Start: required-interface=TI_If_TmExt_Timer_Start
      rp_CS_TmExt_Timer_Started: required-interface=TI_If_TmExt_Timer_IsStarted
      rp_CS_TmExt_Timer_Stop: required-interface=TI_If_TmExt_Timer_Stop
    behavior IB_WarnMsg_Core_TmrSupport
      operation invoked event OIE_pp_Init_WarnMsg_Core_TmrSupport_InitTrigByInit: start-on-event=WarnMsg_Core_TmrSupport_Init, operation=pp_Init.Init
      timing event TEWarnMsg_Core_TmrSupport_Task: start-on-event=WarnMsg_Core_TmrSupport_Task, period=0.032
      port-api-options:
        enable-take-address=false, indirect-api=false, port=WarnMsg_Core_TmrSupport/pp_Init
        enable-take-address=false, indirect-api=false, port=WarnMsg_Core_TmrSupport/rp_CS_TmExt_Timer_Elapsed
        enable-take-address=false, indirect-api=false, port=WarnMsg_Core_TmrSupport/rp_CS_TmExt_Timer_Start
        enable-take-address=false, indirect-api=false, port=WarnMsg_Core_TmrSupport/rp_CS_TmExt_Timer_Started
        enable-take-address=false, indirect-api=false, port=WarnMsg_Core_TmrSupport/rp_CS_TmExt_Timer_Stop
      runnable WarnMsg_Core_TmrSupport_Init: can-be-invoked-concurrently=true
      runnable WarnMsg_Core_TmrSupport_Task: can-be-invoked-concurrently=true
        4 x sync call, all with timeout=0.0:
          OA_rp_CS_TmExt_Timer_Elapsed_Timer_IsElapsed: operation=rp_CS_TmExt_Timer_Elapsed.Timer_IsElapsed
          OA_rp_CS_TmExt_Timer_Start_Timer_Start: operation=rp_CS_TmExt_Timer_Start.Timer_Start
          OA_rp_CS_TmExt_Timer_Started_Timer_IsStarted: operation=rp_CS_TmExt_Timer_Started.Timer_IsStarted
          OA_rp_CS_TmExt_Timer_Stop_Timer_Stop: operation=rp_CS_TmExt_Timer_Stop.Timer_Stop
  swc implementation IMPL_WarnMsg_Core_TmrSupport: programming-language=C, behavior=IB_WarnMsg_Core_TmrSupport
    code-descriptors:
      code CodeDescriptor
  application sw component type DcmApp
    4 x provide port:
      pp_CS_DID_App_Diag_Action: server-com-spec{operation=TI_DID_App_Diag_Action/DID_DiagAction, queue-length=1}, provided-interface=TI_DID_App_Diag_Action
      pp_CS_DiagEntryStatus: server-com-spec{operation=Diag_Entry_Status, queue-length=1}, provided-interface=TI_DiagEntrySts
      pp_CS_RID_App_Diag_Action: server-com-spec{operation=TI_RID_App_Diag_Action/RID_DiagAction, queue-length=1}, provided-interface=TI_RID_App_Diag_Action
      pp_CmpLibCmd_CDcmApp: server-com-spec{operation=Impl_OnCommand, queue-length=1}, provided-interface=if_CS_ModeOnCommand
    behavior IB_DcmApp
      operation invoked event OIE_pp_CS_DID_App_Diag_Action_CDcmApp_DID_DiagActionTrigByDID_DiagAction: start-on-event=CDcmApp_DID_DiagAction, operation=pp_CS_DID_App_Diag_Action.DID_DiagAction
      operation invoked event OIE_pp_CS_DiagEntryStatus_CDcmApp_Diag_Entry_StatusTrigByDiag_Entry_Status: start-on-event=CDcmApp_Diag_Entry_Status, operation=pp_CS_DiagEntryStatus.Diag_Entry_Status
      timing event TECDcmApp_Impl_MainFunction: start-on-event=CDcmApp_Impl_MainFunction, period=0.01
      operation invoked event OIE_pp_CmpLibCmd_CDcmApp_CDcmApp_Impl_OnCommandTrigByImpl_OnCommand: start-on-event=CDcmApp_Impl_OnCommand, operation=pp_CmpLibCmd_CDcmApp.Impl_OnCommand
      operation invoked event OIE_pp_CS_RID_App_Diag_Action_CDcmApp_RID_DiagActionTrigByRID_DiagAction: start-on-event=CDcmApp_RID_DiagAction, operation=pp_CS_RID_App_Diag_Action.RID_DiagAction
      port-api-options:
        enable-take-address=false, indirect-api=false, port=pp_CS_DID_App_Diag_Action
        enable-take-address=false, indirect-api=false, port=pp_CS_DiagEntryStatus
        enable-take-address=false, indirect-api=false, port=pp_CS_RID_App_Diag_Action
        enable-take-address=false, indirect-api=false, port=pp_CmpLibCmd_CDcmApp
      5 x runnable, all with can-be-invoked-concurrently=true:
        CDcmApp_DID_DiagAction
        CDcmApp_Diag_Entry_Status
        CDcmApp_Impl_MainFunction
        CDcmApp_Impl_OnCommand
        CDcmApp_RID_DiagAction
  swc implementation IMPL_DcmApp: programming-language=C, behavior=IB_DcmApp
    code-descriptors:
      code CodeDescriptor
  application sw component type DemApp
    provide port pp_CmpLibCmd_CDemApp: server-com-spec{operation=Impl_OnCommand, queue-length=1}, provided-interface=if_CS_ModeOnCommand
    require port rp_CS_DemExt_ClearDTC: required-interface=TI_DemExt_ClearDTC
    require port rp_CS_DemExt_SetEventStatus: required-interface=TI_DemExt_SetEventStatus
    require port rp_CS_DemExt_SetOperationCycleState: required-interface=TI_DemExt_SetOperationCycleState
    behavior IB_DemApp
      timing event TECDemApp_Impl_MainFunction: start-on-event=CDemApp_Impl_MainFunction, period=0.01
      operation invoked event OIE_pp_CmpLibCmd_CDemApp_CDemApp_Impl_OnCommandTrigByImpl_OnCommand: start-on-event=CDemApp_Impl_OnCommand, operation=pp_CmpLibCmd_CDemApp.Impl_OnCommand
      port-api-options:
        enable-take-address=false, indirect-api=false, port=pp_CmpLibCmd_CDemApp
        enable-take-address=false, indirect-api=false, port=rp_CS_DemExt_ClearDTC
        enable-take-address=false, indirect-api=false, port=DemApp/rp_CS_DemExt_SetEventStatus
        enable-take-address=false, indirect-api=false, port=rp_CS_DemExt_SetOperationCycleState
      runnable CDemApp_Impl_MainFunction: can-be-invoked-concurrently=true
        sync call OA_rp_CS_DemExt_ClearDTC_DemExt_ClearDTC: operation=rp_CS_DemExt_ClearDTC.DemExt_ClearDTC, timeout=0.0
        sync call OA_rp_CS_DemExt_SetEventStatus_DemExt_SetEventStatus: operation=rp_CS_DemExt_SetEventStatus.DemExt_SetEventStatus, timeout=0.0
        sync call OA_rp_CS_DemExt_SetOperationCycleState_DemExt_SetOperationCycleState: operation=rp_CS_DemExt_SetOperationCycleState.DemExt_SetOperationCycleState, timeout=0.0
      runnable CDemApp_Impl_OnCommand: can-be-invoked-concurrently=true
        sync call OA_rp_CS_DemExt_ClearDTC_DemExt_ClearDTC: operation=rp_CS_DemExt_ClearDTC.DemExt_ClearDTC, timeout=0.0
        sync call OA_rp_CS_DemExt_SetEventStatus_DemExt_SetEventStatus: operation=rp_CS_DemExt_SetEventStatus.DemExt_SetEventStatus, timeout=0.0
        sync call OA_rp_CS_DemExt_SetOperationCycleState_DemExt_SetOperationCycleState: operation=rp_CS_DemExt_SetOperationCycleState.DemExt_SetOperationCycleState, timeout=0.0
  swc implementation IMPL_DemApp: programming-language=C, behavior=IB_DemApp
    code-descriptors:
      code CodeDescriptor
  application sw component type DemExt
    17 x provide port:
      pp_CS_DemExt_ClearDTC: server-com-spec{operation=DemExt_ClearDTC, queue-length=1}, provided-interface=TI_DemExt_ClearDTC
      pp_CS_DemExt_GetDTCOfEvent: server-com-spec{operation=DemExt_GetDTCOfEvent, queue-length=1}, provided-interface=TI_DemExt_GetDTCOfEvent
      pp_CS_DemExt_GetDTCSelectionResult: server-com-spec{operation=DemExt_GetDTCSelectionResult, queue-length=1}, provided-interface=TI_DemExt_GetDTCSelectionResult
      pp_CS_DemExt_GetDTCSelectionResultForClearDTC: server-com-spec{operation=DemExt_GetDTCSelectionResultForClearDTC, queue-length=1}, provided-interface=TI_DemExt_GetDTCSelectionResultForClearDTC
      pp_CS_DemExt_GetDebouncingOfEvent: server-com-spec{operation=DemExt_GetDebouncingOfEvent, queue-length=1}, provided-interface=TI_DemExt_GetDebouncingOfEvent
      pp_CS_DemExt_GetEventExtendedDataRecordEx: server-com-spec{operation=DemExt_GetEventExtendedDataRecordEx, queue-length=1}, provided-interface=TI_DemExt_GetEventExtendedDataRecordEx
      pp_CS_DemExt_GetEventFreezeFrameDataEx: server-com-spec{operation=DemExt_GetEventFreezeFrameDataEx, queue-length=1}, provided-interface=TI_DemExt_GetEventFreezeFrameDataEx
      pp_CS_DemExt_GetEventUdsStatus: server-com-spec{operation=DemExt_GetEventUdsStatus, queue-length=1}, provided-interface=TI_DemExt_GetEventUdsStatus
      pp_CS_DemExt_GetFaultDetectionCounter: server-com-spec{operation=DemExt_GetFaultDetectionCounter, queue-length=1}, provided-interface=TI_DemExt_GetFaultDetectionCounter
      pp_CS_DemExt_GetNumberOfEventMemoryEntries: server-com-spec{operation=DemExt_GetNumberOfEventMemoryEntries, queue-length=1}, provided-interface=TI_DemExt_GetNumberOfEventMemoryEntries
      pp_CS_DemExt_GetOperationCycleState: server-com-spec{operation=DemExt_GetOperationCycleState, queue-length=1}, provided-interface=TI_DemExt_GetOperationCycleState
      pp_CS_DemExt_SelectDTC: server-com-spec{operation=DemExt_SelectDTC, queue-length=1}, provided-interface=TI_DemExt_SelectDTC
      pp_CS_DemExt_SetEnableCondition: server-com-spec{operation=DemExt_SetEnableCondition, queue-length=1}, provided-interface=TI_DemExt_SetEnableCondition
      pp_CS_DemExt_SetEventAvailable: server-com-spec{operation=DemExt_SetEventAvailable, queue-length=1}, provided-interface=TI_DemExt_SetEventAvailable
      pp_CS_DemExt_SetEventStatus: server-com-spec{operation=DemExt_SetEventStatus, queue-length=1}, provided-interface=TI_DemExt_SetEventStatus
      pp_CS_DemExt_SetOperationCycleState: server-com-spec{operation=DemExt_SetOperationCycleState, queue-length=1}, provided-interface=TI_DemExt_SetOperationCycleState
      pp_CS_DemExt_SetStorageCondition: server-com-spec{operation=DemExt_SetStorageCondition, queue-length=1}, provided-interface=TI_DemExt_SetStorageCondition
    behavior IB_DemExt
      17 x operation invoked event:
        OIE_pp_CS_DemExt_ClearDTC_DemExt_ClearDTCTrigByDemExt_ClearDTC: start-on-event=DemExt_ClearDTC, operation=pp_CS_DemExt_ClearDTC.DemExt_ClearDTC
        OIE_pp_CS_DemExt_GetDTCOfEvent_DemExt_GetDTCOfEventTrigByDemExt_GetDTCOfEvent: start-on-event=DemExt_GetDTCOfEvent, operation=pp_CS_DemExt_GetDTCOfEvent.DemExt_GetDTCOfEvent
        OIE_pp_CS_DemExt_GetDTCSelectionResult_DemExt_GetDTCSelectionResultTrigByDemExt_GetDTCSelectionResult: start-on-event=DemExt_GetDTCSelectionResult, operation=pp_CS_DemExt_GetDTCSelectionResult.DemExt_GetDTCSelectionResult
        OperationInvokeEvent_111: start-on-event=DemExt_GetDTCSelectionResultForClearDTC, operation=pp_CS_DemExt_GetDTCSelectionResultForClearDTC.DemExt_GetDTCSelectionResultForClearDTC
        OIE_pp_CS_DemExt_GetDebouncingOfEvent_DemExt_GetDebouncingOfEventTrigByDemExt_GetDebouncingOfEvent: start-on-event=DemExt_GetDebouncingOfEvent, operation=pp_CS_DemExt_GetDebouncingOfEvent.DemExt_GetDebouncingOfEvent
        OIE_pp_CS_DemExt_GetEventExtendedDataRecordEx_DemExt_GetEventExtendedDataRecordExTrigByDemExt_GetEventExtendedDataRecordEx: start-on-event=DemExt_GetEventExtendedDataRecordEx, operation=pp_CS_DemExt_GetEventExtendedDataRecordEx.DemExt_GetEventExtendedDataRecordEx
        OIE_pp_CS_DemExt_GetEventFreezeFrameDataEx_DemExt_GetEventFreezeFrameDataExTrigByDemExt_GetEventFreezeFrameDataEx: start-on-event=DemExt_GetEventFreezeFrameDataEx, operation=pp_CS_DemExt_GetEventFreezeFrameDataEx.DemExt_GetEventFreezeFrameDataEx
        OIE_pp_CS_DemExt_GetEventUdsStatus_DemExt_GetEventUdsStatusTrigByDemExt_GetEventUdsStatus: start-on-event=DemExt_GetEventUdsStatus, operation=pp_CS_DemExt_GetEventUdsStatus.DemExt_GetEventUdsStatus
        OIE_pp_CS_DemExt_GetFaultDetectionCounter_DemExt_GetFaultDetectionCounterTrigByDemExt_GetFaultDetectionCounter: start-on-event=DemExt_GetFaultDetectionCounter, operation=pp_CS_DemExt_GetFaultDetectionCounter.DemExt_GetFaultDetectionCounter
        OIE_pp_CS_DemExt_GetNumberOfEventMemoryEntries_DemExt_GetNumberOfEventMemoryEntriesTrigByDemExt_GetNumberOfEventMemoryEntries: start-on-event=DemExt_GetNumberOfEventMemoryEntries, operation=pp_CS_DemExt_GetNumberOfEventMemoryEntries.DemExt_GetNumberOfEventMemoryEntries
        OIE_pp_CS_DemExt_GetOperationCycleState_DemExt_GetOperationCycleStateTrigByDemExt_GetOperationCycleState: start-on-event=DemExt_GetOperationCycleState, operation=pp_CS_DemExt_GetOperationCycleState.DemExt_GetOperationCycleState
        OIE_pp_CS_DemExt_SelectDTC_DemExt_SelectDTCTrigByDemExt_SelectDTC: start-on-event=DemExt_SelectDTC, operation=pp_CS_DemExt_SelectDTC.DemExt_SelectDTC
        OIE_pp_CS_DemExt_SetEnableCondition_DemExt_SetEnableConditionTrigByDemExt_SetEnableCondition: start-on-event=DemExt_SetEnableCondition, operation=pp_CS_DemExt_SetEnableCondition.DemExt_SetEnableCondition
        OIE_pp_CS_DemExt_SetEventAvailable_DemExt_SetEventAvailableTrigByDemExt_SetEventAvailable: start-on-event=DemExt_SetEventAvailable, operation=pp_CS_DemExt_SetEventAvailable.DemExt_SetEventAvailable
        OIE_pp_CS_DemExt_SetEventStatus_DemExt_SetEventStatusTrigByDemExt_SetEventStatus: start-on-event=DemExt_SetEventStatus, operation=pp_CS_DemExt_SetEventStatus.DemExt_SetEventStatus
        OIE_pp_CS_DemExt_SetOperationCycleState_DemExt_SetOperationCycleStateTrigByDemExt_SetOperationCycleState: start-on-event=DemExt_SetOperationCycleState, operation=pp_CS_DemExt_SetOperationCycleState.DemExt_SetOperationCycleState
        OIE_pp_CS_DemExt_SetStorageCondition_DemExt_SetStorageConditionTrigByDemExt_SetStorageCondition: start-on-event=DemExt_SetStorageCondition, operation=pp_CS_DemExt_SetStorageCondition.DemExt_SetStorageCondition
      timing event TEDemExt_MainFunction: start-on-event=DemExt_MainFunction, period=0.01
      port-api-options:
        enable-take-address=false, indirect-api=false, port=pp_CS_DemExt_ClearDTC
        enable-take-address=false, indirect-api=false, port=pp_CS_DemExt_GetDTCOfEvent
        enable-take-address=false, indirect-api=false, port=pp_CS_DemExt_GetDTCSelectionResult
        enable-take-address=false, indirect-api=false, port=pp_CS_DemExt_GetDTCSelectionResultForClearDTC
        enable-take-address=false, indirect-api=false, port=pp_CS_DemExt_GetDebouncingOfEvent
        enable-take-address=false, indirect-api=false, port=pp_CS_DemExt_GetEventExtendedDataRecordEx
        enable-take-address=false, indirect-api=false, port=pp_CS_DemExt_GetEventFreezeFrameDataEx
        enable-take-address=false, indirect-api=false, port=pp_CS_DemExt_GetEventUdsStatus
        enable-take-address=false, indirect-api=false, port=pp_CS_DemExt_GetFaultDetectionCounter
        enable-take-address=false, indirect-api=false, port=pp_CS_DemExt_GetNumberOfEventMemoryEntries
        enable-take-address=false, indirect-api=false, port=pp_CS_DemExt_GetOperationCycleState
        enable-take-address=false, indirect-api=false, port=pp_CS_DemExt_SelectDTC
        enable-take-address=false, indirect-api=false, port=pp_CS_DemExt_SetEnableCondition
        enable-take-address=false, indirect-api=false, port=pp_CS_DemExt_SetEventAvailable
        enable-take-address=false, indirect-api=false, port=pp_CS_DemExt_SetEventStatus
        enable-take-address=false, indirect-api=false, port=pp_CS_DemExt_SetOperationCycleState
        enable-take-address=false, indirect-api=false, port=pp_CS_DemExt_SetStorageCondition
      18 x runnable, all with can-be-invoked-concurrently=true:
        DemExt_ClearDTC
        DemExt_GetDTCOfEvent
        DemExt_GetDTCSelectionResult
        DemExt_GetDTCSelectionResultForClearDTC
        DemExt_GetDebouncingOfEvent
        DemExt_GetEventExtendedDataRecordEx
        DemExt_GetEventFreezeFrameDataEx
        DemExt_GetEventUdsStatus
        DemExt_GetFaultDetectionCounter
        DemExt_GetNumberOfEventMemoryEntries
        DemExt_GetOperationCycleState
        DemExt_SelectDTC
        DemExt_SetEnableCondition
        DemExt_SetEventAvailable
        DemExt_SetEventStatus
        DemExt_SetOperationCycleState
        DemExt_SetStorageCondition
        DemExt_MainFunction
  swc implementation IMPL_DemExt: programming-language=C, behavior=IB_DemExt
    code-descriptors:
      code CodeDescriptor
